VERSION "BodyCAN"

NS_ :

BS_:

BU_: CCM CEM DDM ETC ILCM PDM POT RLDM RRDM SMD SMP TRM Vector_XXX

BO_ 820 CemBodyFr93: 8 CEM
 SG_ ExtrLtgSts_UB : 4|1@0+ (1,0) [0|1] ""  TRM
 SG_ ExtrLtgStsAFS : 23|2@0+ (1,0) [0|3] ""  TRM
 SG_ ExtrLtgStsAHBC : 21|2@0+ (1,0) [0|3] ""  TRM
 SG_ ExtrLtgStsAHL : 19|2@0+ (1,0) [0|3] ""  TRM
 SG_ ExtrLtgStsAllWL : 17|2@0+ (1,0) [0|3] ""  TRM
 SG_ ExtrLtgStsApproach : 31|2@0+ (1,0) [0|3] ""  TRM
 SG_ ExtrLtgStsChks : 15|8@0+ (1,0) [0|255] "Unitless"  TRM
 SG_ ExtrLtgStsCntr : 3|4@0+ (1,0) [0|15] "Unitless"  TRM
 SG_ ExtrLtgStsCornrgLi : 29|2@0+ (1,0) [0|3] ""  TRM
 SG_ ExtrLtgStsDBL : 27|2@0+ (1,0) [0|3] ""  TRM
 SG_ ExtrLtgStsDRL : 25|2@0+ (1,0) [0|3] ""  TRM
 SG_ ExtrLtgStsFlash : 39|2@0+ (1,0) [0|3] ""  TRM
 SG_ ExtrLtgStsFrntFog : 37|2@0+ (1,0) [0|3] ""  TRM
 SG_ ExtrLtgStsGoodbye : 35|2@0+ (1,0) [0|3] ""  TRM
 SG_ ExtrLtgStsHiBeam : 33|2@0+ (1,0) [0|3] ""  TRM
 SG_ ExtrLtgStsHomeSafe : 47|2@0+ (1,0) [0|3] ""  TRM
 SG_ ExtrLtgStsHWL : 45|2@0+ (1,0) [0|3] ""  TRM
 SG_ ExtrLtgStsLoBeam : 43|2@0+ (1,0) [0|3] ""  TRM
 SG_ ExtrLtgStsLtgShow : 41|2@0+ (1,0) [0|3] ""  TRM
 SG_ ExtrLtgStsPosLiFrnt : 55|2@0+ (1,0) [0|3] ""  TRM
 SG_ ExtrLtgStsPosLiRe : 53|2@0+ (1,0) [0|3] ""  TRM
 SG_ ExtrLtgStsReFog : 51|2@0+ (1,0) [0|3] ""  TRM
 SG_ ExtrLtgStsReverseLi : 49|2@0+ (1,0) [0|3] ""  TRM
 SG_ ExtrLtgStsStopLi : 63|2@0+ (1,0) [0|3] ""  TRM
 SG_ ExtrLtgStsTurnIndrLe : 61|2@0+ (1,0) [0|3] ""  TRM
 SG_ ExtrLtgStsTurnIndrRi : 59|2@0+ (1,0) [0|3] ""  TRM
 SG_ ExtrLtgStsWelcome : 57|2@0+ (1,0) [0|3] ""  TRM

BO_ 836 CemBodyFr95: 8 CEM
 SG_ ADIntrLiCtrlReq : 50|3@0+ (1,0) [0|7] ""  ILCM
 SG_ ADIntrLiCtrlReq_UB : 51|1@0+ (1,0) [0|1] ""  ILCM
 SG_ AmbientLiEffectStatus_UB : 55|1@0+ (1,0) [0|1] ""  ILCM
 SG_ AmbientLiEffectStatusBreathingEf : 47|1@0+ (1,0) [0|1] ""  ILCM
 SG_ AmbientLiEffectStatusIdPen : 43|4@0+ (1,0) [0|15] ""  ILCM
 SG_ AmbientLiEffectStatusTransitionE : 46|1@0+ (1,0) [0|1] ""  ILCM
 SG_ AmbLiEnduranceMilgOpenReq_UB : 58|1@0+ (1,0) [0|1] ""  ILCM
 SG_ AmbLiEnduranceMilgOpenReqIdPen : 63|4@0+ (1,0) [0|15] ""  ILCM
 SG_ AmbLiEnduranceMilgOpenReqOnOff1 : 59|1@0+ (1,0) [0|1] ""  ILCM
 SG_ CallSts : 56|1@0+ (1,0) [0|1] ""  ILCM
 SG_ CallSts_UB : 57|1@0+ (1,0) [0|1] ""  ILCM
 SG_ Zone1Settings_UB : 4|1@0+ (1,0) [0|1] ""  ILCM
 SG_ Zone1SettingsBlue : 23|8@0+ (1,0) [0|255] "Unitless"  ILCM
 SG_ Zone1SettingsGreen : 31|8@0+ (1,0) [0|255] "Unitless"  ILCM
 SG_ Zone1SettingsIdPen : 3|4@0+ (1,0) [0|15] ""  ILCM
 SG_ Zone1SettingsIntensity : 12|5@0+ (1,0) [0|31] "Unitless"  ILCM
 SG_ Zone1SettingsRed : 39|8@0+ (1,0) [0|255] "Unitless"  ILCM
 SG_ Zone1SettingsZoneStatus : 13|1@0+ (1,0) [0|1] ""  ILCM

BO_ 840 CemBodyFr96: 8 CEM
 SG_ AmbLiPhoneOpenReq_UB : 50|1@0+ (1,0) [0|1] ""  ILCM
 SG_ AmbLiPhoneOpenReqIdPen : 55|4@0+ (1,0) [0|15] ""  ILCM
 SG_ AmbLiPhoneOpenReqOnOff1 : 51|1@0+ (1,0) [0|1] ""  ILCM
 SG_ FuLvlLoWarn : 40|1@0+ (1,0) [0|1] ""  ILCM
 SG_ FuLvlLoWarn_UB : 41|1@0+ (1,0) [0|1] ""  ILCM
 SG_ GoodbyeLiOpenReq_UB : 42|1@0+ (1,0) [0|1] ""  ILCM
 SG_ GoodbyeLiOpenReqIdPen : 47|4@0+ (1,0) [0|15] ""  ILCM
 SG_ GoodbyeLiOpenReqOnOff1 : 43|1@0+ (1,0) [0|1] ""  ILCM
 SG_ WelcomeLiOpenReq_UB : 58|1@0+ (1,0) [0|1] ""  ILCM
 SG_ WelcomeLiOpenReqIdPen : 63|4@0+ (1,0) [0|15] ""  ILCM
 SG_ WelcomeLiOpenReqOnOff1 : 59|1@0+ (1,0) [0|1] ""  ILCM
 SG_ Zone2Settings_UB : 4|1@0+ (1,0) [0|1] ""  ILCM
 SG_ Zone2SettingsBlue : 23|8@0+ (1,0) [0|255] "Unitless"  ILCM
 SG_ Zone2SettingsGreen : 31|8@0+ (1,0) [0|255] "Unitless"  ILCM
 SG_ Zone2SettingsIdPen : 3|4@0+ (1,0) [0|15] ""  ILCM
 SG_ Zone2SettingsIntensity : 12|5@0+ (1,0) [0|31] "Unitless"  ILCM
 SG_ Zone2SettingsRed : 39|8@0+ (1,0) [0|255] "Unitless"  ILCM
 SG_ Zone2SettingsZoneStatus : 13|1@0+ (1,0) [0|1] ""  ILCM

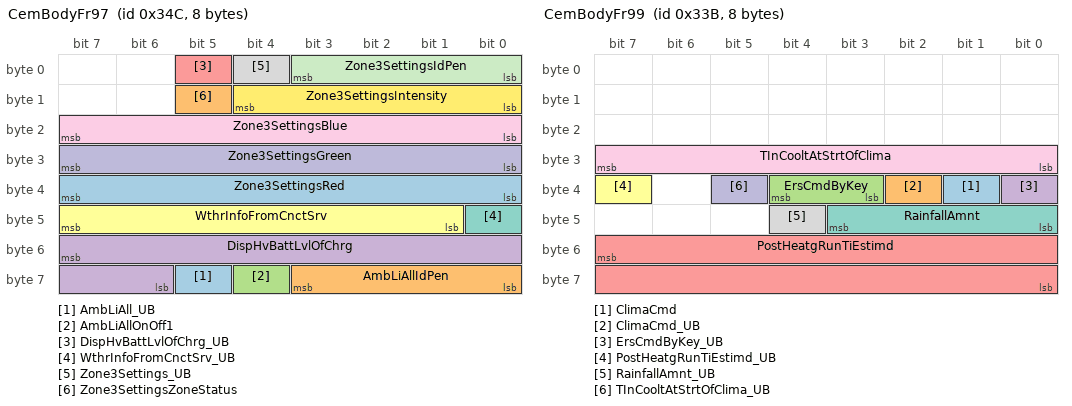
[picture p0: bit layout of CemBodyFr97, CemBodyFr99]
BO_ 844 CemBodyFr97: 8 CEM
 SG_ AmbLiAll_UB : 61|1@0+ (1,0) [0|1] ""  ILCM
 SG_ AmbLiAllIdPen : 59|4@0+ (1,0) [0|15] ""  ILCM
 SG_ AmbLiAllOnOff1 : 60|1@0+ (1,0) [0|1] ""  ILCM
 SG_ DispHvBattLvlOfChrg : 55|10@0+ (0.1,0) [0|102.3] "%"  ILCM
 SG_ DispHvBattLvlOfChrg_UB : 5|1@0+ (1,0) [0|1] ""  ILCM
 SG_ WthrInfoFromCnctSrv : 47|7@0+ (1,0) [0|127] "Unitless"  ILCM
 SG_ WthrInfoFromCnctSrv_UB : 40|1@0+ (1,0) [0|1] ""  ILCM
 SG_ Zone3Settings_UB : 4|1@0+ (1,0) [0|1] ""  ILCM
 SG_ Zone3SettingsBlue : 23|8@0+ (1,0) [0|255] "Unitless"  ILCM
 SG_ Zone3SettingsGreen : 31|8@0+ (1,0) [0|255] "Unitless"  ILCM
 SG_ Zone3SettingsIdPen : 3|4@0+ (1,0) [0|15] ""  ILCM
 SG_ Zone3SettingsIntensity : 12|5@0+ (1,0) [0|31] "Unitless"  ILCM
 SG_ Zone3SettingsRed : 39|8@0+ (1,0) [0|255] "Unitless"  ILCM
 SG_ Zone3SettingsZoneStatus : 13|1@0+ (1,0) [0|1] ""  ILCM

BO_ 34 CemBodyFr98: 8 CEM
 SG_ MusicInfoForMusicShow1_UB : 2|1@0+ (1,0) [0|1] ""  ILCM
 SG_ MusicInfoForMusicShow1DownSampli : 15|4@0+ (1,0) [0|15] "Unitless"  ILCM
 SG_ MusicInfoForMusicShow1MaxFFT100m : 11|4@0+ (1,0) [0|15] "Unitless"  ILCM
 SG_ MusicInfoForMusicShow1MaxFF_0000 : 23|8@0+ (1,0) [0|255] "Unitless"  ILCM
 SG_ MusicInfoForMusicShow1Segment1FF : 31|4@0+ (1,0) [0|15] "Unitless"  ILCM
 SG_ MusicInfoForMusicShow1Segment2FF : 27|4@0+ (1,0) [0|15] "Unitless"  ILCM
 SG_ MusicInfoForMusicShow1Segment3FF : 39|4@0+ (1,0) [0|15] "Unitless"  ILCM
 SG_ MusicInfoForMusicShow1Segment4FF : 35|4@0+ (1,0) [0|15] "Unitless"  ILCM
 SG_ MusicInfoForMusicShow1Segment5FF : 47|4@0+ (1,0) [0|15] "Unitless"  ILCM
 SG_ MusicInfoForMusicShow1Segment6FF : 43|4@0+ (1,0) [0|15] "Unitless"  ILCM
 SG_ MusicInfoForMusicShow1Segment7FF : 55|4@0+ (1,0) [0|15] "Unitless"  ILCM
 SG_ MusicInfoForMusicShow1Segment8FF : 51|4@0+ (1,0) [0|15] "Unitless"  ILCM
 SG_ MusicInfoForMusicShow1StateFlagA : 0|1@0+ (1,0) [0|1] ""  ILCM
 SG_ MusicInfoForMusicShow1StateFlagN : 1|1@0+ (1,0) [0|1] ""  ILCM
 SG_ MusicInfoForMusicShow1TimeFlagAu : 63|4@0+ (1,0) [0|15] "Unitless"  ILCM
 SG_ MusicInfoForMusicShow1TimeFlagMe : 59|4@0+ (1,0) [0|15] "Unitless"  ILCM
 SG_ SecRowRiCmftSet : 4|2@0+ (1,0) [0|3] ""  Vector_XXX
 SG_ SecRowRiCmftSet_UB : 5|1@0+ (1,0) [0|1] ""  Vector_XXX
 SG_ WinOpenLDACReq : 7|1@0+ (1,0) [0|1] ""  DDM,PDM,RLDM,RRDM
 SG_ WinOpenLDACReq_UB : 6|1@0+ (1,0) [0|1] ""  DDM,PDM,RLDM,RRDM

BO_ 827 CemBodyFr99: 8 CEM
 SG_ ClimaCmd : 33|1@0+ (1,0) [0|1] ""  CCM
 SG_ ClimaCmd_UB : 34|1@0+ (1,0) [0|1] ""  CCM
 SG_ ErsCmdByKey : 36|2@0+ (1,0) [0|3] ""  CCM
 SG_ ErsCmdByKey_UB : 32|1@0+ (1,0) [0|1] ""  CCM
 SG_ PostHeatgRunTiEstimd : 55|16@0+ (1,0) [0|65535] "Unitless"  CCM
 SG_ PostHeatgRunTiEstimd_UB : 39|1@0+ (1,0) [0|1] ""  CCM
 SG_ RainfallAmnt : 43|4@0+ (1,0) [0|15] ""  CCM
 SG_ RainfallAmnt_UB : 44|1@0+ (1,0) [0|1] ""  CCM
 SG_ TInCooltAtStrtOfClima : 31|8@0+ (1,-40) [-40|215] "degC"  CCM
 SG_ TInCooltAtStrtOfClima_UB : 37|1@0+ (1,0) [0|1] ""  CCM

BO_ 1281 CemBodyNMFr: 8 CEM
 SG_ PNC16_CEM : 16|1@0+ (1,0) [0|0] ""  CCM
 SG_ PNC17_CEM : 17|1@0+ (1,0) [0|0] ""  CCM
 SG_ PNC18_CEM : 18|1@0+ (1,0) [0|0] ""  CCM
 SG_ PNC19_CEM : 19|1@0+ (1,0) [0|0] ""  CCM
 SG_ PNC20_CEM : 20|1@0+ (1,0) [0|0] ""  CCM
 SG_ PNC21_CEM : 21|1@0+ (1,0) [0|0] ""  CCM
 SG_ PNC22_CEM : 22|1@0+ (1,0) [0|0] ""  CCM
 SG_ PNC23_CEM : 23|1@0+ (1,0) [0|0] ""  CCM
 SG_ PNC24_CEM : 24|1@0+ (1,0) [0|0] ""  CCM
 SG_ PNC25_CEM : 25|1@0+ (1,0) [0|0] ""  CCM
 SG_ PNC26_CEM : 26|1@0+ (1,0) [0|0] ""  CCM
 SG_ PNC27_CEM : 27|1@0+ (1,0) [0|0] ""  CCM
 SG_ PNC28_CEM : 28|1@0+ (1,0) [0|0] ""  CCM
 SG_ PNC29_CEM : 29|1@0+ (1,0) [0|0] ""  CCM
 SG_ PNC30_CEM : 30|1@0+ (1,0) [0|0] ""  CCM
 SG_ PNC31_CEM : 31|1@0+ (1,0) [0|0] ""  CCM
 SG_ PNC32_CEM : 32|1@0+ (1,0) [0|0] ""  CCM
 SG_ PNC33_CEM : 33|1@0+ (1,0) [0|0] ""  CCM
 SG_ PNC34_CEM : 34|1@0+ (1,0) [0|0] ""  CCM
 SG_ PNC35_CEM : 35|1@0+ (1,0) [0|0] ""  CCM
 SG_ PNC36_CEM : 36|1@0+ (1,0) [0|0] ""  CCM
 SG_ PNC37_CEM : 37|1@0+ (1,0) [0|0] ""  CCM
 SG_ PNC38_CEM : 38|1@0+ (1,0) [0|0] ""  CCM
 SG_ PNC39_CEM : 39|1@0+ (1,0) [0|0] ""  CCM
 SG_ PNC40_CEM : 40|1@0+ (1,0) [0|0] ""  CCM
 SG_ PNC41_CEM : 41|1@0+ (1,0) [0|0] ""  CCM
 SG_ PNC42_CEM : 42|1@0+ (1,0) [0|0] ""  CCM
 SG_ NM_PNI_CEM : 14|1@0+ (1,0) [0|0] ""  CCM
 SG_ NM_AW_CEM : 12|1@0+ (1,0) [0|0] ""  CCM
 SG_ NM_CS_CEM : 11|1@0+ (1,0) [0|0] ""  CCM
 SG_ NM_RMR_CEM : 8|1@0+ (1,0) [0|0] ""  CCM
 SG_ NM_NodeID_CEM : 7|8@0+ (1,0) [0|0] ""  CCM

BO_ 2047 CemToAllFuncBodyDiagReqFrame: 8 CEM
 SG_ CemToAllFuncBodyDiagReqNpdu : 7|64@0+ (1,0) [0|0] ""  CCM,DDM,ILCM,PDM,POT,RLDM,RRDM,SMD,SMP,TRM

BO_ 1809 CemToCcmBodyDiagReqFrame: 8 CEM
 SG_ CemToCcmBodyDiagReqNpdu : 7|64@0+ (1,0) [0|0] ""  CCM

BO_ 1810 CemToDdmBodyDiagReqFrame: 8 CEM
 SG_ CemToDdmBodyDiagReqNpdu : 7|64@0+ (1,0) [0|0] ""  DDM

BO_ 1413 CemtoEtcXCPFr01: 8 CEM

BO_ 1414 CemtoEtcXCPFr02: 8 CEM

BO_ 1415 CemtoEtcXCPFr03: 8 CEM

BO_ 1416 CemtoEtcXCPFr04: 8 CEM

BO_ 1840 CemToIlcmBodyDiagReqFrame1: 8 CEM
 SG_ CemToIlcmBodyDiagReqNpdu : 7|64@0+ (1,0) [0|0] ""  ILCM

BO_ 1816 CemToLdmBodyDiagReqFrame: 8 CEM
 SG_ CemToLdmBodyDiagReqNpdu : 7|64@0+ (1,0) [0|0] ""  Vector_XXX

BO_ 1811 CemToPdmBodyDiagReqFrame: 8 CEM
 SG_ CemToPdmBodyDiagReqNpdu : 7|64@0+ (1,0) [0|0] ""  PDM

BO_ 1813 CemToPotBodyDiagReqFrame: 8 CEM
 SG_ CemToPotBodyDiagReqNpdu : 7|64@0+ (1,0) [0|0] ""  POT

BO_ 1817 CemToRdmBodyDiagReqFrame: 8 CEM
 SG_ CemToRdmBodyDiagReqNpdu : 7|64@0+ (1,0) [0|0] ""  Vector_XXX

BO_ 1825 CemToRldmBodyDiagReqFrame: 8 CEM
 SG_ CemToRldmBodyDiagReqNpdu : 7|64@0+ (1,0) [0|0] ""  RLDM

BO_ 1826 CemToRrdmBodyDiagReqFrame: 8 CEM
 SG_ CemToRrdmBodyDiagReqNpdu : 7|64@0+ (1,0) [0|0] ""  RRDM

BO_ 1827 CemToSdlBodyDiagReqFrame: 8 CEM
 SG_ CemToSdlBodyDiagReqNpdu : 7|64@0+ (1,0) [0|0] ""  Vector_XXX

BO_ 1828 CemToSdrBodyDiagReqFrame: 8 CEM
 SG_ CemToSdrBodyDiagReqNpdu : 7|64@0+ (1,0) [0|0] ""  Vector_XXX

BO_ 1841 CemToSmblBodyDiagReqFrame: 8 CEM
 SG_ CemToSmblBodyDiagReqNpdu : 7|64@0+ (1,0) [0|0] ""  Vector_XXX

BO_ 1842 CemToSmbrBodyDiagReqFrame: 8 CEM
 SG_ CemToSmbrBodyDiagReqNpdu : 7|64@0+ (1,0) [0|0] ""  Vector_XXX

BO_ 1831 CemToSmdBodyDiagReqFrame: 8 CEM
 SG_ CemToSmdBodyDiagReqNpdu : 7|64@0+ (1,0) [0|0] ""  SMD

BO_ 1843 CemToSmfBodyDiagReqFram: 8 CEM
 SG_ CemToSmfBodyDiagReqNpdu : 7|64@0+ (1,0) [0|0] ""  Vector_XXX

BO_ 1832 CemToSmpBodyDiagReqFrame: 8 CEM
 SG_ CemToSmpBodyDiagReqNpdu : 7|64@0+ (1,0) [0|0] ""  SMP

BO_ 1833 CemToSmrBodyDiagReqFrame: 8 CEM
 SG_ CemToSmbBodyDiagReqNpdu : 7|64@0+ (1,0) [0|0] ""  Vector_XXX

BO_ 1815 CemToTrmBodyDiagReqFrame: 8 CEM
 SG_ CemToTrmBodyDiagReqNpdu : 7|64@0+ (1,0) [0|0] ""  TRM

BO_ 48 DdmBodyFr01: 8 DDM
 SG_ ChdLockLeftCmd : 7|2@0+ (1,0) [0|3] ""  RLDM
 SG_ ChdLockLeftCmd_UB : 3|1@0+ (1,0) [0|1] ""  RLDM
 SG_ ChdLockRightStsToHmi : 1|2@0+ (1,0) [0|3] ""  CEM
 SG_ ChdLockRightStsToHmi_UB : 2|1@0+ (1,0) [0|1] ""  CEM
 SG_ DoorDrvrHndlHMISts_UB : 15|1@0+ (1,0) [0|1] ""  CEM
 SG_ DoorDrvrHndlHMIStsDeployedOverTm : 23|1@0+ (1,0) [0|1] ""  CEM
 SG_ DoorDrvrHndlHMIStsReserved1 : 22|1@0+ (1,0) [0|1] ""  CEM
 SG_ DoorDrvrHndlHMIStsRetractOverTmd : 21|1@0+ (1,0) [0|1] ""  CEM
 SG_ DoorDrvrHndlHMIStsUnsScsHallSnsr : 20|1@0+ (1,0) [0|1] ""  CEM
 SG_ DoorDrvrRelsFail_UB : 19|1@0+ (1,0) [0|1] ""  CEM
 SG_ DoorDrvrRelsFailCinchOverTimed : 18|1@0+ (1,0) [0|1] ""  CEM
 SG_ DoorDrvrRelsFailFailure1 : 17|1@0+ (1,0) [0|1] ""  CEM
 SG_ DoorDrvrRelsFailMechRels : 16|1@0+ (1,0) [0|1] ""  CEM
 SG_ FltOfIndcrTurnOnDrvrSide : 40|1@0+ (1,0) [0|1] ""  CEM
 SG_ FltOfIndcrTurnOnDrvrSide_UB : 41|1@0+ (1,0) [0|1] ""  CEM
 SG_ MemBtnPsd_UB : 28|1@0+ (1,0) [0|1] ""  CEM
 SG_ MemBtnPsdMemBtn1 : 14|1@0+ (1,0) [0|1] ""  CEM
 SG_ MemBtnPsdMemBtn2 : 13|1@0+ (1,0) [0|1] ""  CEM
 SG_ MemBtnPsdMemBtn3 : 12|1@0+ (1,0) [0|1] ""  CEM
 SG_ MemBtnPsdMemButM : 11|1@0+ (1,0) [0|1] ""  CEM
 SG_ MirrFoldStsAtDrvr : 55|3@0+ (1,0) [0|7] ""  CEM
 SG_ MirrFoldStsAtDrvr_UB : 25|1@0+ (1,0) [0|1] ""  CEM
 SG_ ShortDropWinDrvrSts : 9|2@0+ (1,0) [0|3] ""  CEM
 SG_ ShortDropWinDrvrSts_UB : 10|1@0+ (1,0) [0|1] ""  CEM
 SG_ WinDsblRightCmd : 49|1@0+ (1,0) [0|1] ""  RRDM
 SG_ WinDsblRightCmd_UB : 48|1@0+ (1,0) [0|1] ""  RRDM
 SG_ WinFailrStsAtDrvr : 5|1@0+ (1,0) [0|1] ""  CEM
 SG_ WinFailrStsAtDrvr_UB : 4|1@0+ (1,0) [0|1] ""  CEM

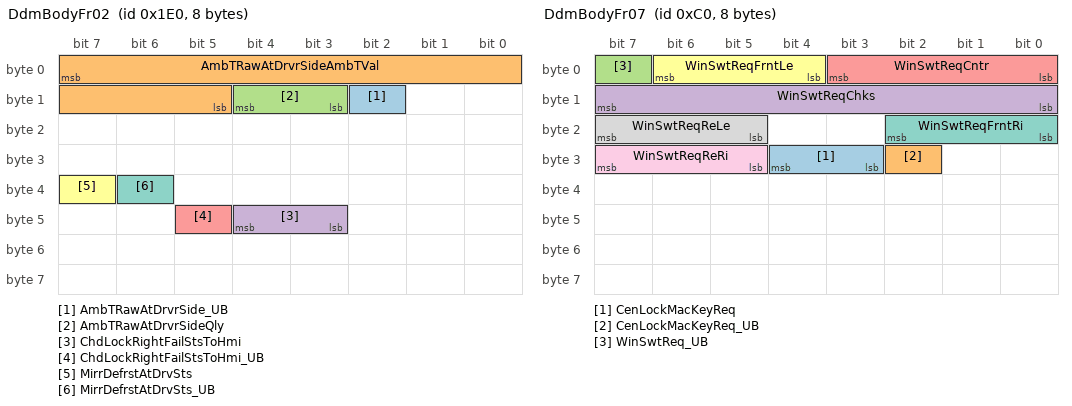
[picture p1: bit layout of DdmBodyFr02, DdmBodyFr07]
BO_ 480 DdmBodyFr02: 8 DDM
 SG_ AmbTRawAtDrvrSide_UB : 10|1@0+ (1,0) [0|1] ""  CEM
 SG_ AmbTRawAtDrvrSideAmbTVal : 7|11@0+ (0.1,-70) [-70|134.7] "degC"  CEM
 SG_ AmbTRawAtDrvrSideQly : 12|2@0+ (1,0) [0|3] ""  CEM
 SG_ ChdLockRightFailStsToHmi : 44|2@0+ (1,0) [0|3] ""  CEM
 SG_ ChdLockRightFailStsToHmi_UB : 45|1@0+ (1,0) [0|1] ""  CEM
 SG_ MirrDefrstAtDrvSts : 39|1@0+ (1,0) [0|1] ""  CEM
 SG_ MirrDefrstAtDrvSts_UB : 38|1@0+ (1,0) [0|1] ""  CEM

BO_ 291 DdmBodyFr03: 8 DDM
 SG_ AmbTURawAtDrvrSide : 55|12@0+ (0.1,-70) [-70|339.5] "degC"  CEM
 SG_ AmbTURawAtDrvrSide_UB : 42|1@0+ (1,0) [0|1] ""  CEM
 SG_ DoorDrvrCinhIntFailInf_UB : 43|1@0+ (1,0) [0|1] ""  CEM
 SG_ DoorDrvrCinhIntFailInfCinchFlt1 : 45|1@0+ (1,0) [0|1] ""  CEM
 SG_ DoorDrvrCinhIntFailInfCinchRestF : 44|1@0+ (1,0) [0|1] ""  CEM
 SG_ DoorDrvrHndlSts : 21|3@0+ (1,0) [0|7] ""  CEM
 SG_ DoorDrvrHndlSts_UB : 22|1@0+ (1,0) [0|1] ""  CEM
 SG_ DoorDrvrSwpLockBtn : 57|1@0+ (1,0) [0|1] ""  CEM
 SG_ DoorDrvrSwpLockBtn_UB : 56|1@0+ (1,0) [0|1] ""  CEM
 SG_ MirrDwnStsAtDrvr : 18|3@0+ (1,0) [0|7] ""  CEM
 SG_ MirrDwnStsAtDrvr_UB : 46|1@0+ (1,0) [0|1] ""  CEM
 SG_ MirrPosnAdjFromCldPass_UB : 23|1@0+ (1,0) [0|1] ""  PDM
 SG_ MirrPosnAdjFromCldPassMirrPosnAd : 7|8@0+ (1,0) [0|180] "Deg"  PDM
 SG_ MirrPosnAdjFromCldPassMirrP_0000 : 15|8@0+ (1,0) [0|180] "Deg"  PDM
 SG_ MirrPosnToCldAtDrvr_UB : 47|1@0+ (1,0) [0|1] ""  CEM
 SG_ MirrPosnToCldAtDrvrMirrPosnAdjCl : 31|8@0+ (1,0) [0|180] "Deg"  CEM
 SG_ MirrPosnToCldAtDrvrMirrPosn_0000 : 39|8@0+ (1,0) [0|180] "Deg"  CEM

BO_ 5 DdmBodyFr04: 8 DDM
 SG_ ChdLockRightCmd : 6|2@0+ (1,0) [0|3] ""  RRDM
 SG_ ChdLockRightCmd_UB : 4|1@0+ (1,0) [0|1] ""  RRDM
 SG_ ChdPrtnLeftFailStsToHmi : 31|2@0+ (1,0) [0|3] ""  CEM
 SG_ ChdPrtnLeftFailStsToHmi_UB : 7|1@0+ (1,0) [0|1] ""  CEM
 SG_ ChdPrtnLeftStsToHmi : 1|2@0+ (1,0) [0|3] ""  CEM
 SG_ ChdPrtnLeftStsToHmi_UB : 2|1@0+ (1,0) [0|1] ""  CEM
 SG_ DoorDrvrLatPawlSt : 33|2@0+ (1,0) [0|3] ""  CEM
 SG_ DoorDrvrLatPawlSt_UB : 34|1@0+ (1,0) [0|1] ""  CEM
 SG_ DoorDrvrLatPosn : 47|2@0+ (1,0) [0|3] ""  CEM
 SG_ DoorDrvrLatPosn_UB : 58|1@0+ (1,0) [0|1] ""  CEM
 SG_ DoorDrvrLockSts : 45|2@0+ (1,0) [0|3] ""  CEM
 SG_ DoorDrvrLockSts_UB : 59|1@0+ (1,0) [0|1] ""  CEM
 SG_ DoorDrvrOpenLowReqOutdSwt1 : 23|2@0+ (1,0) [0|3] ""  CEM
 SG_ DoorDrvrOpenLowReqOutdSwt1_UB : 63|1@0+ (1,0) [0|1] ""  CEM
 SG_ DoorDrvrOpenReqInsdSwt1 : 25|2@0+ (1,0) [0|3] ""  CEM
 SG_ DoorDrvrOpenReqInsdSwt1_UB : 57|1@0+ (1,0) [0|1] ""  CEM
 SG_ DoorDrvrSwtIntrLockgReq : 43|2@0+ (1,0) [0|3] ""  CEM
 SG_ DoorDrvrSwtIntrLockgReq_UB : 60|1@0+ (1,0) [0|1] ""  CEM
 SG_ LcmaLedStsDrvrSide : 29|1@0+ (1,0) [0|1] ""  CEM
 SG_ LcmaLedStsDrvrSide_UB : 28|1@0+ (1,0) [0|1] ""  CEM
 SG_ MirrAtDrvrInMovmt : 41|1@0+ (1,0) [0|1] ""  CEM
 SG_ MirrAtDrvrInMovmt_UB : 61|1@0+ (1,0) [0|1] ""  CEM
 SG_ MirrBtnPsdAtDrvr : 40|1@0+ (1,0) [0|1] ""  CEM
 SG_ MirrBtnPsdAtDrvr_UB : 62|1@0+ (1,0) [0|1] ""  CEM
 SG_ MirrCmdAtPass_UB : 48|1@0+ (1,0) [0|1] ""  PDM
 SG_ MirrCmdAtPassMirrDwnCmd : 55|2@0+ (1,0) [0|3] ""  PDM
 SG_ MirrCmdAtPassMirrFoldCmd : 53|2@0+ (1,0) [0|3] ""  PDM
 SG_ MirrCmdAtPassMirrPosAdjCmd : 51|3@0+ (1,0) [0|7] ""  PDM
 SG_ MirrPosnDownLdSts : 9|2@0+ (1,0) [0|3] ""  CEM
 SG_ MirrPosnDownLdSts_UB : 18|1@0+ (1,0) [0|1] ""  CEM
 SG_ MirrPosnFromCldAtDrvrFb : 11|2@0+ (1,0) [0|3] ""  CEM
 SG_ MirrPosnFromCldAtDrvrFb_UB : 19|1@0+ (1,0) [0|1] ""  CEM
 SG_ MirrPosnFromCldAtPassFb : 13|2@0+ (1,0) [0|3] ""  CEM
 SG_ MirrPosnFromCldAtPassFb_UB : 20|1@0+ (1,0) [0|1] ""  CEM
 SG_ MirrPosnMemSts : 15|2@0+ (1,0) [0|3] ""  CEM
 SG_ MirrPosnMemSts_UB : 21|1@0+ (1,0) [0|1] ""  CEM
 SG_ WinDsblLeftCmd : 26|1@0+ (1,0) [0|1] ""  RLDM
 SG_ WinDsblLeftCmd_UB : 27|1@0+ (1,0) [0|1] ""  RLDM
 SG_ WinPosnStsAtDrvr : 39|5@0+ (1,0) [0|31] ""  CCM,CEM
 SG_ WinPosnStsAtDrvr_UB : 56|1@0+ (1,0) [0|1] ""  CCM,CEM

BO_ 192 DdmBodyFr07: 8 DDM
 SG_ CenLockMacKeyReq : 28|2@0+ (1,0) [0|3] ""  CEM
 SG_ CenLockMacKeyReq_UB : 26|1@0+ (1,0) [0|1] ""  CEM
 SG_ WinSwtReq_UB : 7|1@0+ (1,0) [0|1] ""  PDM,RLDM,RRDM
 SG_ WinSwtReqChks : 15|8@0+ (1,0) [0|255] "Unitless"  PDM,RLDM,RRDM
 SG_ WinSwtReqCntr : 3|4@0+ (1,0) [0|15] "Unitless"  PDM,RLDM,RRDM
 SG_ WinSwtReqFrntLe : 6|3@0+ (1,0) [0|7] ""  PDM,RLDM,RRDM
 SG_ WinSwtReqFrntRi : 18|3@0+ (1,0) [0|7] ""  PDM,RLDM,RRDM
 SG_ WinSwtReqReLe : 23|3@0+ (1,0) [0|7] ""  PDM,RLDM,RRDM
 SG_ WinSwtReqReRi : 31|3@0+ (1,0) [0|7] ""  PDM,RLDM,RRDM

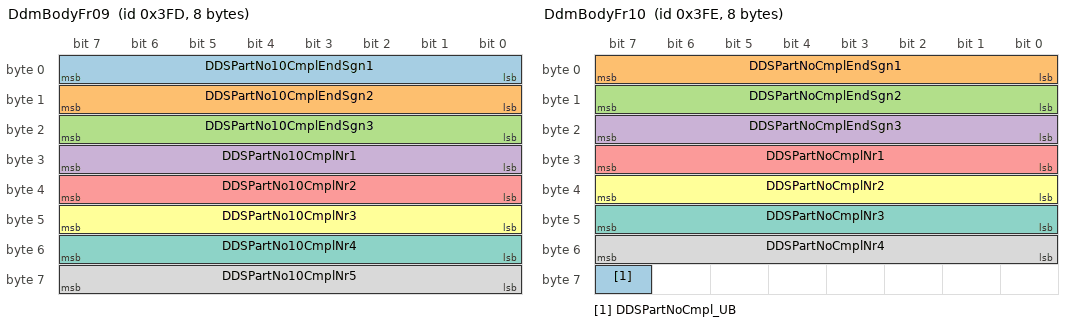
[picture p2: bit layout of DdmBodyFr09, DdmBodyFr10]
BO_ 1021 DdmBodyFr09: 8 DDM
 SG_ DDSPartNo10CmplEndSgn1 : 7|8@0+ (1,0) [0|255] "Unitless"  Vector_XXX
 SG_ DDSPartNo10CmplEndSgn2 : 15|8@0+ (1,0) [0|255] "Unitless"  Vector_XXX
 SG_ DDSPartNo10CmplEndSgn3 : 23|8@0+ (1,0) [0|255] "Unitless"  Vector_XXX
 SG_ DDSPartNo10CmplNr1 : 31|8@0+ (1,0) [0|255] "Unitless"  Vector_XXX
 SG_ DDSPartNo10CmplNr2 : 39|8@0+ (1,0) [0|255] "Unitless"  Vector_XXX
 SG_ DDSPartNo10CmplNr3 : 47|8@0+ (1,0) [0|255] "Unitless"  Vector_XXX
 SG_ DDSPartNo10CmplNr4 : 55|8@0+ (1,0) [0|255] "Unitless"  Vector_XXX
 SG_ DDSPartNo10CmplNr5 : 63|8@0+ (1,0) [0|255] "Unitless"  Vector_XXX

BO_ 1022 DdmBodyFr10: 8 DDM
 SG_ DDSPartNoCmpl_UB : 63|1@0+ (1,0) [0|1] ""  Vector_XXX
 SG_ DDSPartNoCmplEndSgn1 : 7|8@0+ (1,0) [0|255] "Unitless"  Vector_XXX
 SG_ DDSPartNoCmplEndSgn2 : 15|8@0+ (1,0) [0|255] "Unitless"  Vector_XXX
 SG_ DDSPartNoCmplEndSgn3 : 23|8@0+ (1,0) [0|255] "Unitless"  Vector_XXX
 SG_ DDSPartNoCmplNr1 : 31|8@0+ (1,0) [0|255] "Unitless"  Vector_XXX
 SG_ DDSPartNoCmplNr2 : 39|8@0+ (1,0) [0|255] "Unitless"  Vector_XXX
 SG_ DDSPartNoCmplNr3 : 47|8@0+ (1,0) [0|255] "Unitless"  Vector_XXX
 SG_ DDSPartNoCmplNr4 : 55|8@0+ (1,0) [0|255] "Unitless"  Vector_XXX

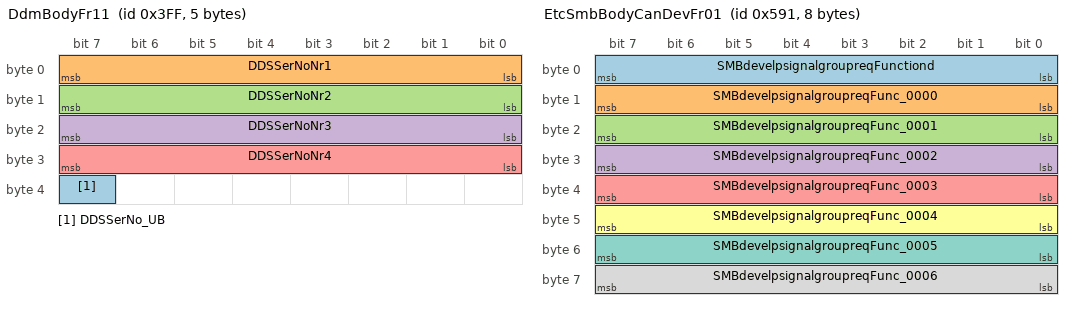
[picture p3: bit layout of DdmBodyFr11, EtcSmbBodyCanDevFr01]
BO_ 1023 DdmBodyFr11: 5 DDM
 SG_ DDSSerNo_UB : 39|1@0+ (1,0) [0|1] ""  Vector_XXX
 SG_ DDSSerNoNr1 : 7|8@0+ (1,0) [0|255] "Unitless"  Vector_XXX
 SG_ DDSSerNoNr2 : 15|8@0+ (1,0) [0|255] "Unitless"  Vector_XXX
 SG_ DDSSerNoNr3 : 23|8@0+ (1,0) [0|255] "Unitless"  Vector_XXX
 SG_ DDSSerNoNr4 : 31|8@0+ (1,0) [0|255] "Unitless"  Vector_XXX

BO_ 1283 DdmBodyNMFr: 8 DDM
 SG_ PNC16_DDM : 16|1@0+ (1,0) [0|0] ""  CEM
 SG_ PNC17_DDM : 17|1@0+ (1,0) [0|0] ""  CEM
 SG_ PNC18_DDM : 18|1@0+ (1,0) [0|0] ""  CEM
 SG_ PNC19_DDM : 19|1@0+ (1,0) [0|0] ""  CEM
 SG_ PNC20_DDM : 20|1@0+ (1,0) [0|0] ""  CEM
 SG_ PNC21_DDM : 21|1@0+ (1,0) [0|0] ""  CEM
 SG_ PNC22_DDM : 22|1@0+ (1,0) [0|0] ""  CEM
 SG_ PNC23_DDM : 23|1@0+ (1,0) [0|0] ""  CEM
 SG_ PNC24_DDM : 24|1@0+ (1,0) [0|0] ""  CEM
 SG_ PNC25_DDM : 25|1@0+ (1,0) [0|0] ""  CEM
 SG_ PNC26_DDM : 26|1@0+ (1,0) [0|0] ""  CEM
 SG_ PNC27_DDM : 27|1@0+ (1,0) [0|0] ""  CEM
 SG_ PNC28_DDM : 28|1@0+ (1,0) [0|0] ""  CEM
 SG_ PNC29_DDM : 29|1@0+ (1,0) [0|0] ""  CEM
 SG_ PNC30_DDM : 30|1@0+ (1,0) [0|0] ""  CEM
 SG_ PNC31_DDM : 31|1@0+ (1,0) [0|0] ""  CEM
 SG_ PNC32_DDM : 32|1@0+ (1,0) [0|0] ""  CEM
 SG_ PNC33_DDM : 33|1@0+ (1,0) [0|0] ""  CEM
 SG_ PNC34_DDM : 34|1@0+ (1,0) [0|0] ""  CEM
 SG_ PNC35_DDM : 35|1@0+ (1,0) [0|0] ""  CEM
 SG_ PNC36_DDM : 36|1@0+ (1,0) [0|0] ""  CEM
 SG_ PNC37_DDM : 37|1@0+ (1,0) [0|0] ""  CEM
 SG_ PNC38_DDM : 38|1@0+ (1,0) [0|0] ""  CEM
 SG_ PNC39_DDM : 39|1@0+ (1,0) [0|0] ""  CEM
 SG_ PNC40_DDM : 40|1@0+ (1,0) [0|0] ""  CEM
 SG_ PNC41_DDM : 41|1@0+ (1,0) [0|0] ""  CEM
 SG_ PNC42_DDM : 42|1@0+ (1,0) [0|0] ""  CEM
 SG_ NM_PNI_DDM : 14|1@0+ (1,0) [0|0] ""  CEM
 SG_ NM_AW_DDM : 12|1@0+ (1,0) [0|0] ""  CEM
 SG_ NM_CS_DDM : 11|1@0+ (1,0) [0|0] ""  CEM
 SG_ NM_RMR_DDM : 8|1@0+ (1,0) [0|0] ""  CEM
 SG_ NM_NodeID_DDM : 7|8@0+ (1,0) [0|0] ""  CEM

BO_ 1347 DdmBodyVFCVectorFr: 8 DDM
 SG_ VFCVectorDDMBlockID : 1|2@0+ (1,0) [0|3] "Unitless"  ETC
 SG_ VFCVectorDDMVFCid0 : 2|1@0+ (1,0) [0|1] ""  ETC
 SG_ VFCVectorDDMVFCid1 : 3|1@0+ (1,0) [0|1] ""  ETC
 SG_ VFCVectorDDMVFCid10 : 12|1@0+ (1,0) [0|1] ""  ETC
 SG_ VFCVectorDDMVFCid11 : 13|1@0+ (1,0) [0|1] ""  ETC
 SG_ VFCVectorDDMVFCid12 : 14|1@0+ (1,0) [0|1] ""  ETC
 SG_ VFCVectorDDMVFCid13 : 15|1@0+ (1,0) [0|1] ""  ETC
 SG_ VFCVectorDDMVFCid14 : 16|1@0+ (1,0) [0|1] ""  ETC
 SG_ VFCVectorDDMVFCid15 : 17|1@0+ (1,0) [0|1] ""  ETC
 SG_ VFCVectorDDMVFCid16 : 18|1@0+ (1,0) [0|1] ""  ETC
 SG_ VFCVectorDDMVFCid17 : 19|1@0+ (1,0) [0|1] ""  ETC
 SG_ VFCVectorDDMVFCid18 : 20|1@0+ (1,0) [0|1] ""  ETC
 SG_ VFCVectorDDMVFCid19 : 21|1@0+ (1,0) [0|1] ""  ETC
 SG_ VFCVectorDDMVFCid2 : 4|1@0+ (1,0) [0|1] ""  ETC
 SG_ VFCVectorDDMVFCid20 : 22|1@0+ (1,0) [0|1] ""  ETC
 SG_ VFCVectorDDMVFCid21 : 23|1@0+ (1,0) [0|1] ""  ETC
 SG_ VFCVectorDDMVFCid22 : 24|1@0+ (1,0) [0|1] ""  ETC
 SG_ VFCVectorDDMVFCid23 : 25|1@0+ (1,0) [0|1] ""  ETC
 SG_ VFCVectorDDMVFCid24 : 26|1@0+ (1,0) [0|1] ""  ETC
 SG_ VFCVectorDDMVFCid25 : 27|1@0+ (1,0) [0|1] ""  ETC
 SG_ VFCVectorDDMVFCid26 : 28|1@0+ (1,0) [0|1] ""  ETC
 SG_ VFCVectorDDMVFCid27 : 29|1@0+ (1,0) [0|1] ""  ETC
 SG_ VFCVectorDDMVFCid28 : 30|1@0+ (1,0) [0|1] ""  ETC
 SG_ VFCVectorDDMVFCid29 : 31|1@0+ (1,0) [0|1] ""  ETC
 SG_ VFCVectorDDMVFCid3 : 5|1@0+ (1,0) [0|1] ""  ETC
 SG_ VFCVectorDDMVFCid30 : 32|1@0+ (1,0) [0|1] ""  ETC
 SG_ VFCVectorDDMVFCid31 : 33|1@0+ (1,0) [0|1] ""  ETC
 SG_ VFCVectorDDMVFCid32 : 34|1@0+ (1,0) [0|1] ""  ETC
 SG_ VFCVectorDDMVFCid33 : 35|1@0+ (1,0) [0|1] ""  ETC
 SG_ VFCVectorDDMVFCid34 : 36|1@0+ (1,0) [0|1] ""  ETC
 SG_ VFCVectorDDMVFCid35 : 37|1@0+ (1,0) [0|1] ""  ETC
 SG_ VFCVectorDDMVFCid36 : 38|1@0+ (1,0) [0|1] ""  ETC
 SG_ VFCVectorDDMVFCid37 : 39|1@0+ (1,0) [0|1] ""  ETC
 SG_ VFCVectorDDMVFCid38 : 40|1@0+ (1,0) [0|1] ""  ETC
 SG_ VFCVectorDDMVFCid39 : 41|1@0+ (1,0) [0|1] ""  ETC
 SG_ VFCVectorDDMVFCid4 : 6|1@0+ (1,0) [0|1] ""  ETC
 SG_ VFCVectorDDMVFCid40 : 42|1@0+ (1,0) [0|1] ""  ETC
 SG_ VFCVectorDDMVFCid41 : 43|1@0+ (1,0) [0|1] ""  ETC
 SG_ VFCVectorDDMVFCid42 : 44|1@0+ (1,0) [0|1] ""  ETC
 SG_ VFCVectorDDMVFCid43 : 45|1@0+ (1,0) [0|1] ""  ETC
 SG_ VFCVectorDDMVFCid44 : 46|1@0+ (1,0) [0|1] ""  ETC
 SG_ VFCVectorDDMVFCid45 : 47|1@0+ (1,0) [0|1] ""  ETC
 SG_ VFCVectorDDMVFCid46 : 48|1@0+ (1,0) [0|1] ""  ETC
 SG_ VFCVectorDDMVFCid47 : 49|1@0+ (1,0) [0|1] ""  ETC
 SG_ VFCVectorDDMVFCid48 : 50|1@0+ (1,0) [0|1] ""  ETC
 SG_ VFCVectorDDMVFCid49 : 51|1@0+ (1,0) [0|1] ""  ETC
 SG_ VFCVectorDDMVFCid5 : 7|1@0+ (1,0) [0|1] ""  ETC
 SG_ VFCVectorDDMVFCid50 : 52|1@0+ (1,0) [0|1] ""  ETC
 SG_ VFCVectorDDMVFCid51 : 53|1@0+ (1,0) [0|1] ""  ETC
 SG_ VFCVectorDDMVFCid52 : 54|1@0+ (1,0) [0|1] ""  ETC
 SG_ VFCVectorDDMVFCid53 : 55|1@0+ (1,0) [0|1] ""  ETC
 SG_ VFCVectorDDMVFCid54 : 56|1@0+ (1,0) [0|1] ""  ETC
 SG_ VFCVectorDDMVFCid55 : 57|1@0+ (1,0) [0|1] ""  ETC
 SG_ VFCVectorDDMVFCid56 : 58|1@0+ (1,0) [0|1] ""  ETC
 SG_ VFCVectorDDMVFCid57 : 59|1@0+ (1,0) [0|1] ""  ETC
 SG_ VFCVectorDDMVFCid58 : 60|1@0+ (1,0) [0|1] ""  ETC
 SG_ VFCVectorDDMVFCid59 : 61|1@0+ (1,0) [0|1] ""  ETC
 SG_ VFCVectorDDMVFCid6 : 8|1@0+ (1,0) [0|1] ""  ETC
 SG_ VFCVectorDDMVFCid60 : 62|1@0+ (1,0) [0|1] ""  ETC
 SG_ VFCVectorDDMVFCid61 : 63|1@0+ (1,0) [0|1] ""  ETC
 SG_ VFCVectorDDMVFCid7 : 9|1@0+ (1,0) [0|1] ""  ETC
 SG_ VFCVectorDDMVFCid8 : 10|1@0+ (1,0) [0|1] ""  ETC
 SG_ VFCVectorDDMVFCid9 : 11|1@0+ (1,0) [0|1] ""  ETC

BO_ 1554 DdmToCemBodyDiagResFrame: 8 DDM
 SG_ DdmToCemBodyDiagResNpdu : 7|64@0+ (1,0) [0|0] ""  CEM

BO_ 1417 DdmtoEtcXCPFr01: 8 DDM

BO_ 1425 EtcSmbBodyCanDevFr01: 8 ETC
 SG_ SMBdevelpsignalgroupreqFunctiond : 7|8@0+ (1,0) [0|255] "Unitless"  Vector_XXX
 SG_ SMBdevelpsignalgroupreqFunc_0000 : 15|8@0+ (1,0) [0|255] "Unitless"  Vector_XXX
 SG_ SMBdevelpsignalgroupreqFunc_0001 : 23|8@0+ (1,0) [0|255] "Unitless"  Vector_XXX
 SG_ SMBdevelpsignalgroupreqFunc_0002 : 31|8@0+ (1,0) [0|255] "Unitless"  Vector_XXX
 SG_ SMBdevelpsignalgroupreqFunc_0003 : 39|8@0+ (1,0) [0|255] "Unitless"  Vector_XXX
 SG_ SMBdevelpsignalgroupreqFunc_0004 : 47|8@0+ (1,0) [0|255] "Unitless"  Vector_XXX
 SG_ SMBdevelpsignalgroupreqFunc_0005 : 55|8@0+ (1,0) [0|255] "Unitless"  Vector_XXX
 SG_ SMBdevelpsignalgroupreqFunc_0006 : 63|8@0+ (1,0) [0|255] "Unitless"  Vector_XXX

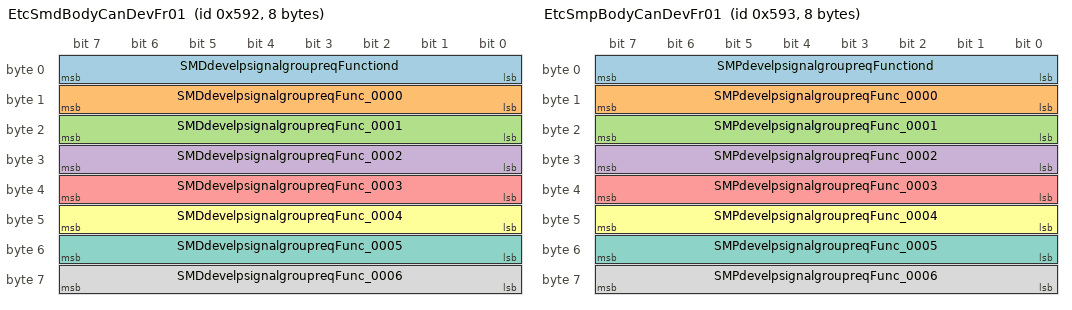
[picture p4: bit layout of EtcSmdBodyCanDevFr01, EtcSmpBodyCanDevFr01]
BO_ 1426 EtcSmdBodyCanDevFr01: 8 ETC
 SG_ SMDdevelpsignalgroupreqFunctiond : 7|8@0+ (1,0) [0|255] "Unitless"  SMD
 SG_ SMDdevelpsignalgroupreqFunc_0000 : 15|8@0+ (1,0) [0|255] "Unitless"  SMD
 SG_ SMDdevelpsignalgroupreqFunc_0001 : 23|8@0+ (1,0) [0|255] "Unitless"  SMD
 SG_ SMDdevelpsignalgroupreqFunc_0002 : 31|8@0+ (1,0) [0|255] "Unitless"  SMD
 SG_ SMDdevelpsignalgroupreqFunc_0003 : 39|8@0+ (1,0) [0|255] "Unitless"  SMD
 SG_ SMDdevelpsignalgroupreqFunc_0004 : 47|8@0+ (1,0) [0|255] "Unitless"  SMD
 SG_ SMDdevelpsignalgroupreqFunc_0005 : 55|8@0+ (1,0) [0|255] "Unitless"  SMD
 SG_ SMDdevelpsignalgroupreqFunc_0006 : 63|8@0+ (1,0) [0|255] "Unitless"  SMD

BO_ 1427 EtcSmpBodyCanDevFr01: 8 ETC
 SG_ SMPdevelpsignalgroupreqFunctiond : 7|8@0+ (1,0) [0|255] "Unitless"  SMP
 SG_ SMPdevelpsignalgroupreqFunc_0000 : 15|8@0+ (1,0) [0|255] "Unitless"  SMP
 SG_ SMPdevelpsignalgroupreqFunc_0001 : 23|8@0+ (1,0) [0|255] "Unitless"  SMP
 SG_ SMPdevelpsignalgroupreqFunc_0002 : 31|8@0+ (1,0) [0|255] "Unitless"  SMP
 SG_ SMPdevelpsignalgroupreqFunc_0003 : 39|8@0+ (1,0) [0|255] "Unitless"  SMP
 SG_ SMPdevelpsignalgroupreqFunc_0004 : 47|8@0+ (1,0) [0|255] "Unitless"  SMP
 SG_ SMPdevelpsignalgroupreqFunc_0005 : 55|8@0+ (1,0) [0|255] "Unitless"  SMP
 SG_ SMPdevelpsignalgroupreqFunc_0006 : 63|8@0+ (1,0) [0|255] "Unitless"  SMP

BO_ 1526 EtcToCcmXCPFr01: 8 ETC

BO_ 1527 EtcToCcmXCPFr02: 8 ETC

BO_ 1528 EtcToCcmXCPFr03: 8 ETC

BO_ 1529 EtcToCcmXCPFr04: 8 ETC

BO_ 1521 EtcToCemXCPFr01: 8 ETC

BO_ 1522 EtcToDdmXCPFr01: 8 ETC

BO_ 1530 EtcToIlcmXcpFr01: 8 ETC

BO_ 1523 EtcToPdmXCPFr01: 8 ETC

BO_ 1467 EtcToPotXCPFr01: 8 ETC

BO_ 1524 EtcToRldmXCPFr01: 8 ETC

BO_ 1525 EtcToRrdmXCPFr01: 8 ETC

BO_ 1465 EtcToTrmXcpFr01: 8 ETC

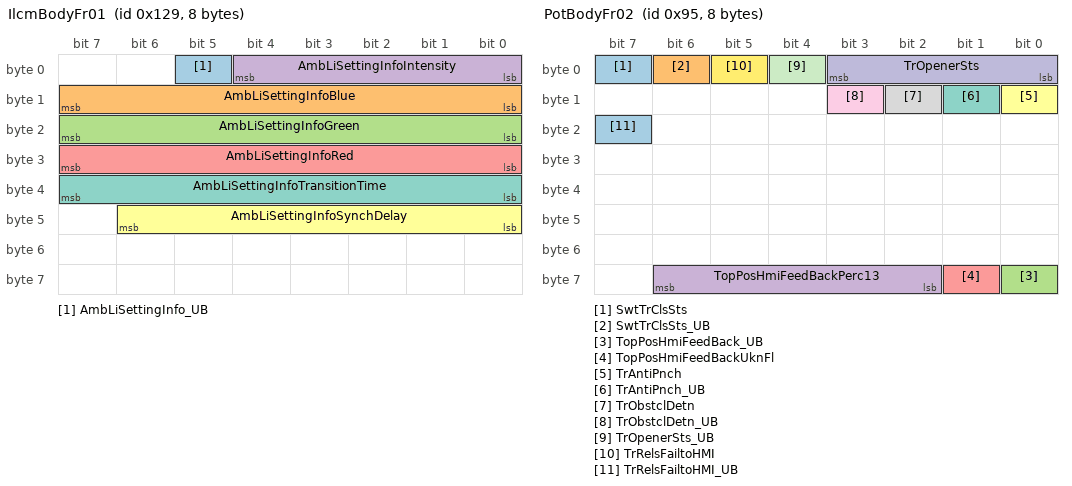
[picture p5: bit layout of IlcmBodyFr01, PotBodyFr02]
BO_ 297 IlcmBodyFr01: 8 ILCM
 SG_ AmbLiSettingInfo_UB : 5|1@0+ (1,0) [0|1] ""  CEM
 SG_ AmbLiSettingInfoBlue : 15|8@0+ (1,0) [0|255] "Unitless"  CEM
 SG_ AmbLiSettingInfoGreen : 23|8@0+ (1,0) [0|255] "Unitless"  CEM
 SG_ AmbLiSettingInfoIntensity : 4|5@0+ (1,0) [0|31] "Unitless"  CEM
 SG_ AmbLiSettingInfoRed : 31|8@0+ (1,0) [0|255] "Unitless"  CEM
 SG_ AmbLiSettingInfoSynchDelay : 46|7@0+ (1,0) [0|127] "Unitless"  CEM
 SG_ AmbLiSettingInfoTransitionTime : 39|8@0+ (1,0) [0|255] "Unitless"  CEM

BO_ 1301 IlcmBodyNMFr: 8 ILCM
 SG_ PNC16_ILCM : 16|1@0+ (1,0) [0|0] ""  DDM
 SG_ PNC17_ILCM : 17|1@0+ (1,0) [0|0] ""  DDM
 SG_ PNC18_ILCM : 18|1@0+ (1,0) [0|0] ""  DDM
 SG_ PNC19_ILCM : 19|1@0+ (1,0) [0|0] ""  DDM
 SG_ PNC20_ILCM : 20|1@0+ (1,0) [0|0] ""  DDM
 SG_ PNC21_ILCM : 21|1@0+ (1,0) [0|0] ""  DDM
 SG_ PNC22_ILCM : 22|1@0+ (1,0) [0|0] ""  DDM
 SG_ PNC23_ILCM : 23|1@0+ (1,0) [0|0] ""  DDM
 SG_ PNC24_ILCM : 24|1@0+ (1,0) [0|0] ""  DDM
 SG_ PNC25_ILCM : 25|1@0+ (1,0) [0|0] ""  DDM
 SG_ PNC26_ILCM : 26|1@0+ (1,0) [0|0] ""  DDM
 SG_ PNC27_ILCM : 27|1@0+ (1,0) [0|0] ""  DDM
 SG_ PNC28_ILCM : 28|1@0+ (1,0) [0|0] ""  DDM
 SG_ PNC29_ILCM : 29|1@0+ (1,0) [0|0] ""  DDM
 SG_ PNC30_ILCM : 30|1@0+ (1,0) [0|0] ""  DDM
 SG_ PNC31_ILCM : 31|1@0+ (1,0) [0|0] ""  DDM
 SG_ PNC32_ILCM : 32|1@0+ (1,0) [0|0] ""  DDM
 SG_ PNC33_ILCM : 33|1@0+ (1,0) [0|0] ""  DDM
 SG_ PNC34_ILCM : 34|1@0+ (1,0) [0|0] ""  DDM
 SG_ PNC35_ILCM : 35|1@0+ (1,0) [0|0] ""  DDM
 SG_ PNC36_ILCM : 36|1@0+ (1,0) [0|0] ""  DDM
 SG_ PNC37_ILCM : 37|1@0+ (1,0) [0|0] ""  DDM
 SG_ PNC38_ILCM : 38|1@0+ (1,0) [0|0] ""  DDM
 SG_ PNC39_ILCM : 39|1@0+ (1,0) [0|0] ""  DDM
 SG_ PNC40_ILCM : 40|1@0+ (1,0) [0|0] ""  DDM
 SG_ PNC41_ILCM : 41|1@0+ (1,0) [0|0] ""  DDM
 SG_ PNC42_ILCM : 42|1@0+ (1,0) [0|0] ""  DDM
 SG_ NM_PNI_ILCM : 14|1@0+ (1,0) [0|0] ""  DDM
 SG_ NM_AW_ILCM : 12|1@0+ (1,0) [0|0] ""  DDM
 SG_ NM_CS_ILCM : 11|1@0+ (1,0) [0|0] ""  DDM
 SG_ NM_RMR_ILCM : 8|1@0+ (1,0) [0|0] ""  DDM
 SG_ NM_NodeID_ILCM : 7|8@0+ (1,0) [0|0] ""  DDM

BO_ 1584 IlcmToCemBodyDiagResFrame1: 8 ILCM
 SG_ IlcmToCemBodyDiagResNpdu : 7|64@0+ (1,0) [0|0] ""  CEM

BO_ 1531 IlcmToEtcXcpFr01: 8 ILCM

BO_ 16 PdmBodyFr01: 8 PDM
 SG_ DoorPassLatPawlSt : 44|2@0+ (1,0) [0|3] ""  CEM
 SG_ DoorPassLatPawlSt_UB : 42|1@0+ (1,0) [0|1] ""  CEM
 SG_ DoorPassLatPosn : 31|2@0+ (1,0) [0|3] ""  CEM
 SG_ DoorPassLatPosn_UB : 32|1@0+ (1,0) [0|1] ""  CEM
 SG_ DoorPassLockSts : 27|2@0+ (1,0) [0|3] ""  CEM
 SG_ DoorPassLockSts_UB : 35|1@0+ (1,0) [0|1] ""  CEM
 SG_ DoorPassOpenLowReqOutdSwt1 : 47|2@0+ (1,0) [0|3] ""  CEM
 SG_ DoorPassOpenLowReqOutdSwt1_UB : 34|1@0+ (1,0) [0|1] ""  CEM
 SG_ DoorPassOpenReqInsdSwt1 : 25|2@0+ (1,0) [0|3] ""  CEM
 SG_ DoorPassOpenReqInsdSwt1_UB : 45|1@0+ (1,0) [0|1] ""  CEM
 SG_ DoorPassRelsFail_UB : 41|1@0+ (1,0) [0|1] ""  CEM
 SG_ DoorPassRelsFailCinchOverTimed : 55|1@0+ (1,0) [0|1] ""  CEM
 SG_ DoorPassRelsFailFailure1 : 54|1@0+ (1,0) [0|1] ""  CEM
 SG_ DoorPassRelsFailMechRels : 53|1@0+ (1,0) [0|1] ""  CEM
 SG_ DoorPassSwtIntrLockgReq : 18|2@0+ (1,0) [0|3] ""  CEM
 SG_ DoorPassSwtIntrLockgReq_UB : 16|1@0+ (1,0) [0|1] ""  CEM
 SG_ FltOfIndcrTurnOnPassSide : 29|1@0+ (1,0) [0|1] ""  CEM
 SG_ FltOfIndcrTurnOnPassSide_UB : 28|1@0+ (1,0) [0|1] ""  CEM
 SG_ LcmaLedStsPassSide : 39|1@0+ (1,0) [0|1] ""  CEM
 SG_ LcmaLedStsPassSide_UB : 33|1@0+ (1,0) [0|1] ""  CEM
 SG_ MirrAtPassInMovmt : 1|1@0+ (1,0) [0|1] ""  CEM
 SG_ MirrAtPassInMovmt_UB : 0|1@0+ (1,0) [0|1] ""  CEM
 SG_ MirrDwnStsAtPass : 15|3@0+ (1,0) [0|7] ""  CEM,DDM
 SG_ MirrDwnStsAtPass_UB : 12|1@0+ (1,0) [0|1] ""  CEM,DDM
 SG_ MirrFoldStsAtPass : 11|3@0+ (1,0) [0|7] ""  CEM,DDM
 SG_ MirrFoldStsAtPass_UB : 8|1@0+ (1,0) [0|1] ""  CEM,DDM
 SG_ PassMemBtnPsd_UB : 19|1@0+ (1,0) [0|1] ""  CEM
 SG_ PassMemBtnPsdMemBtn1 : 23|1@0+ (1,0) [0|1] ""  CEM
 SG_ PassMemBtnPsdMemBtn2 : 22|1@0+ (1,0) [0|1] ""  CEM
 SG_ PassMemBtnPsdMemBtn3 : 21|1@0+ (1,0) [0|1] ""  CEM
 SG_ PassMemBtnPsdMemButM : 20|1@0+ (1,0) [0|1] ""  CEM
 SG_ ShortDropWinPassSts : 38|2@0+ (1,0) [0|3] ""  CEM
 SG_ ShortDropWinPassSts_UB : 36|1@0+ (1,0) [0|1] ""  CEM
 SG_ WinPosnStsAtPass : 7|5@0+ (1,0) [0|31] ""  CCM,CEM
 SG_ WinPosnStsAtPass_UB : 2|1@0+ (1,0) [0|1] ""  CCM,CEM

BO_ 293 PdmBodyFr03: 8 PDM
 SG_ AmbTRawAtPassSide_UB : 29|1@0+ (1,0) [0|1] ""  CEM
 SG_ AmbTRawAtPassSideAmbTVal : 26|11@0+ (0.1,-70) [-70|134.7] "degC"  CEM
 SG_ AmbTRawAtPassSideQly : 28|2@0+ (1,0) [0|3] ""  CEM
 SG_ AmbTURawAtPassSide : 55|12@0+ (0.1,-70) [-70|339.5] "degC"  CEM
 SG_ AmbTURawAtPassSide_UB : 16|1@0+ (1,0) [0|1] ""  CEM
 SG_ DoorPassCinhIntFailInf_UB : 40|1@0+ (1,0) [0|1] ""  CEM
 SG_ DoorPassCinhIntFailInfCinchFlt1 : 42|1@0+ (1,0) [0|1] ""  CEM
 SG_ DoorPassCinhIntFailInfCinchRestF : 41|1@0+ (1,0) [0|1] ""  CEM
 SG_ DoorPassHndlHMISts_UB : 21|1@0+ (1,0) [0|1] ""  CEM
 SG_ DoorPassHndlHMIStsDeployedOverTm : 59|1@0+ (1,0) [0|1] ""  CEM
 SG_ DoorPassHndlHMIStsReserved1 : 58|1@0+ (1,0) [0|1] ""  CEM
 SG_ DoorPassHndlHMIStsRetractOverTmd : 57|1@0+ (1,0) [0|1] ""  CEM
 SG_ DoorPassHndlHMIStsUnsScsHallSnsr : 56|1@0+ (1,0) [0|1] ""  CEM
 SG_ DoorPassHndlSts : 19|3@0+ (1,0) [0|7] ""  CEM
 SG_ DoorPassHndlSts_UB : 20|1@0+ (1,0) [0|1] ""  CEM
 SG_ MirrDefrstAtPassSts : 31|1@0+ (1,0) [0|1] ""  CEM
 SG_ MirrDefrstAtPassSts_UB : 30|1@0+ (1,0) [0|1] ""  CEM
 SG_ MirrPosnFromCldAtPassIntFb : 47|2@0+ (1,0) [0|3] ""  DDM
 SG_ MirrPosnFromCldAtPassIntFb_UB : 45|1@0+ (1,0) [0|1] ""  DDM
 SG_ MirrPosnToCldAtPass_UB : 23|1@0+ (1,0) [0|1] ""  CEM
 SG_ MirrPosnToCldAtPassMirrPosnAdjCl : 7|8@0+ (1,0) [0|180] "Deg"  CEM
 SG_ MirrPosnToCldAtPassMirrPosn_0000 : 15|8@0+ (1,0) [0|180] "Deg"  CEM
 SG_ WinFailrStsAtPass : 44|1@0+ (1,0) [0|1] ""  CEM
 SG_ WinFailrStsAtPass_UB : 43|1@0+ (1,0) [0|1] ""  CEM

BO_ 565 PdmBodyFr04: 8 PDM
 SG_ DoorPassSwpLockBtn : 59|1@0+ (1,0) [0|1] ""  CEM
 SG_ DoorPassSwpLockBtn_UB : 57|1@0+ (1,0) [0|1] ""  CEM

BO_ 1284 PdmBodyNMFr: 8 PDM
 SG_ PNC16_PDM : 16|1@0+ (1,0) [0|0] ""  Vector_XXX
 SG_ PNC17_PDM : 17|1@0+ (1,0) [0|0] ""  Vector_XXX
 SG_ PNC18_PDM : 18|1@0+ (1,0) [0|0] ""  Vector_XXX
 SG_ PNC19_PDM : 19|1@0+ (1,0) [0|0] ""  Vector_XXX
 SG_ PNC20_PDM : 20|1@0+ (1,0) [0|0] ""  Vector_XXX
 SG_ PNC21_PDM : 21|1@0+ (1,0) [0|0] ""  Vector_XXX
 SG_ PNC22_PDM : 22|1@0+ (1,0) [0|0] ""  Vector_XXX
 SG_ PNC23_PDM : 23|1@0+ (1,0) [0|0] ""  Vector_XXX
 SG_ PNC24_PDM : 24|1@0+ (1,0) [0|0] ""  Vector_XXX
 SG_ PNC25_PDM : 25|1@0+ (1,0) [0|0] ""  Vector_XXX
 SG_ PNC26_PDM : 26|1@0+ (1,0) [0|0] ""  Vector_XXX
 SG_ PNC27_PDM : 27|1@0+ (1,0) [0|0] ""  Vector_XXX
 SG_ PNC28_PDM : 28|1@0+ (1,0) [0|0] ""  Vector_XXX
 SG_ PNC29_PDM : 29|1@0+ (1,0) [0|0] ""  Vector_XXX
 SG_ PNC30_PDM : 30|1@0+ (1,0) [0|0] ""  Vector_XXX
 SG_ PNC31_PDM : 31|1@0+ (1,0) [0|0] ""  Vector_XXX
 SG_ PNC32_PDM : 32|1@0+ (1,0) [0|0] ""  Vector_XXX
 SG_ PNC33_PDM : 33|1@0+ (1,0) [0|0] ""  Vector_XXX
 SG_ PNC34_PDM : 34|1@0+ (1,0) [0|0] ""  Vector_XXX
 SG_ PNC35_PDM : 35|1@0+ (1,0) [0|0] ""  Vector_XXX
 SG_ PNC36_PDM : 36|1@0+ (1,0) [0|0] ""  Vector_XXX
 SG_ PNC37_PDM : 37|1@0+ (1,0) [0|0] ""  Vector_XXX
 SG_ PNC38_PDM : 38|1@0+ (1,0) [0|0] ""  Vector_XXX
 SG_ PNC39_PDM : 39|1@0+ (1,0) [0|0] ""  Vector_XXX
 SG_ PNC40_PDM : 40|1@0+ (1,0) [0|0] ""  Vector_XXX
 SG_ PNC41_PDM : 41|1@0+ (1,0) [0|0] ""  Vector_XXX
 SG_ PNC42_PDM : 42|1@0+ (1,0) [0|0] ""  Vector_XXX
 SG_ NM_PNI_PDM : 14|1@0+ (1,0) [0|0] ""  Vector_XXX
 SG_ NM_AW_PDM : 12|1@0+ (1,0) [0|0] ""  Vector_XXX
 SG_ NM_CS_PDM : 11|1@0+ (1,0) [0|0] ""  Vector_XXX
 SG_ NM_RMR_PDM : 8|1@0+ (1,0) [0|0] ""  Vector_XXX
 SG_ NM_NodeID_PDM : 7|8@0+ (1,0) [0|0] ""  Vector_XXX

BO_ 1348 PdmBodyVFCVectorFr: 8 PDM
 SG_ VFCVectorPDMBlockID : 1|2@0+ (1,0) [0|3] "Unitless"  ETC
 SG_ VFCVectorPDMVFCid0 : 2|1@0+ (1,0) [0|1] ""  ETC
 SG_ VFCVectorPDMVFCid1 : 3|1@0+ (1,0) [0|1] ""  ETC
 SG_ VFCVectorPDMVFCid10 : 12|1@0+ (1,0) [0|1] ""  ETC
 SG_ VFCVectorPDMVFCid11 : 13|1@0+ (1,0) [0|1] ""  ETC
 SG_ VFCVectorPDMVFCid12 : 14|1@0+ (1,0) [0|1] ""  ETC
 SG_ VFCVectorPDMVFCid13 : 15|1@0+ (1,0) [0|1] ""  ETC
 SG_ VFCVectorPDMVFCid14 : 16|1@0+ (1,0) [0|1] ""  ETC
 SG_ VFCVectorPDMVFCid15 : 17|1@0+ (1,0) [0|1] ""  ETC
 SG_ VFCVectorPDMVFCid16 : 18|1@0+ (1,0) [0|1] ""  ETC
 SG_ VFCVectorPDMVFCid17 : 19|1@0+ (1,0) [0|1] ""  ETC
 SG_ VFCVectorPDMVFCid18 : 20|1@0+ (1,0) [0|1] ""  ETC
 SG_ VFCVectorPDMVFCid19 : 21|1@0+ (1,0) [0|1] ""  ETC
 SG_ VFCVectorPDMVFCid2 : 4|1@0+ (1,0) [0|1] ""  ETC
 SG_ VFCVectorPDMVFCid20 : 22|1@0+ (1,0) [0|1] ""  ETC
 SG_ VFCVectorPDMVFCid21 : 23|1@0+ (1,0) [0|1] ""  ETC
 SG_ VFCVectorPDMVFCid22 : 24|1@0+ (1,0) [0|1] ""  ETC
 SG_ VFCVectorPDMVFCid23 : 25|1@0+ (1,0) [0|1] ""  ETC
 SG_ VFCVectorPDMVFCid24 : 26|1@0+ (1,0) [0|1] ""  ETC
 SG_ VFCVectorPDMVFCid25 : 27|1@0+ (1,0) [0|1] ""  ETC
 SG_ VFCVectorPDMVFCid26 : 28|1@0+ (1,0) [0|1] ""  ETC
 SG_ VFCVectorPDMVFCid27 : 29|1@0+ (1,0) [0|1] ""  ETC
 SG_ VFCVectorPDMVFCid28 : 30|1@0+ (1,0) [0|1] ""  ETC
 SG_ VFCVectorPDMVFCid29 : 31|1@0+ (1,0) [0|1] ""  ETC
 SG_ VFCVectorPDMVFCid3 : 5|1@0+ (1,0) [0|1] ""  ETC
 SG_ VFCVectorPDMVFCid30 : 32|1@0+ (1,0) [0|1] ""  ETC
 SG_ VFCVectorPDMVFCid31 : 33|1@0+ (1,0) [0|1] ""  ETC
 SG_ VFCVectorPDMVFCid32 : 34|1@0+ (1,0) [0|1] ""  ETC
 SG_ VFCVectorPDMVFCid33 : 35|1@0+ (1,0) [0|1] ""  ETC
 SG_ VFCVectorPDMVFCid34 : 36|1@0+ (1,0) [0|1] ""  ETC
 SG_ VFCVectorPDMVFCid35 : 37|1@0+ (1,0) [0|1] ""  ETC
 SG_ VFCVectorPDMVFCid36 : 38|1@0+ (1,0) [0|1] ""  ETC
 SG_ VFCVectorPDMVFCid37 : 39|1@0+ (1,0) [0|1] ""  ETC
 SG_ VFCVectorPDMVFCid38 : 40|1@0+ (1,0) [0|1] ""  ETC
 SG_ VFCVectorPDMVFCid39 : 41|1@0+ (1,0) [0|1] ""  ETC
 SG_ VFCVectorPDMVFCid4 : 6|1@0+ (1,0) [0|1] ""  ETC
 SG_ VFCVectorPDMVFCid40 : 42|1@0+ (1,0) [0|1] ""  ETC
 SG_ VFCVectorPDMVFCid41 : 43|1@0+ (1,0) [0|1] ""  ETC
 SG_ VFCVectorPDMVFCid42 : 44|1@0+ (1,0) [0|1] ""  ETC
 SG_ VFCVectorPDMVFCid43 : 45|1@0+ (1,0) [0|1] ""  ETC
 SG_ VFCVectorPDMVFCid44 : 46|1@0+ (1,0) [0|1] ""  ETC
 SG_ VFCVectorPDMVFCid45 : 47|1@0+ (1,0) [0|1] ""  ETC
 SG_ VFCVectorPDMVFCid46 : 48|1@0+ (1,0) [0|1] ""  ETC
 SG_ VFCVectorPDMVFCid47 : 49|1@0+ (1,0) [0|1] ""  ETC
 SG_ VFCVectorPDMVFCid48 : 50|1@0+ (1,0) [0|1] ""  ETC
 SG_ VFCVectorPDMVFCid49 : 51|1@0+ (1,0) [0|1] ""  ETC
 SG_ VFCVectorPDMVFCid5 : 7|1@0+ (1,0) [0|1] ""  ETC
 SG_ VFCVectorPDMVFCid50 : 52|1@0+ (1,0) [0|1] ""  ETC
 SG_ VFCVectorPDMVFCid51 : 53|1@0+ (1,0) [0|1] ""  ETC
 SG_ VFCVectorPDMVFCid52 : 54|1@0+ (1,0) [0|1] ""  ETC
 SG_ VFCVectorPDMVFCid53 : 55|1@0+ (1,0) [0|1] ""  ETC
 SG_ VFCVectorPDMVFCid54 : 56|1@0+ (1,0) [0|1] ""  ETC
 SG_ VFCVectorPDMVFCid55 : 57|1@0+ (1,0) [0|1] ""  ETC
 SG_ VFCVectorPDMVFCid56 : 58|1@0+ (1,0) [0|1] ""  ETC
 SG_ VFCVectorPDMVFCid57 : 59|1@0+ (1,0) [0|1] ""  ETC
 SG_ VFCVectorPDMVFCid58 : 60|1@0+ (1,0) [0|1] ""  ETC
 SG_ VFCVectorPDMVFCid59 : 61|1@0+ (1,0) [0|1] ""  ETC
 SG_ VFCVectorPDMVFCid6 : 8|1@0+ (1,0) [0|1] ""  ETC
 SG_ VFCVectorPDMVFCid60 : 62|1@0+ (1,0) [0|1] ""  ETC
 SG_ VFCVectorPDMVFCid61 : 63|1@0+ (1,0) [0|1] ""  ETC
 SG_ VFCVectorPDMVFCid7 : 9|1@0+ (1,0) [0|1] ""  ETC
 SG_ VFCVectorPDMVFCid8 : 10|1@0+ (1,0) [0|1] ""  ETC
 SG_ VFCVectorPDMVFCid9 : 11|1@0+ (1,0) [0|1] ""  ETC

BO_ 1555 PdmToCemBodyDiagResFrame: 8 PDM
 SG_ PdmToCemBodyDiagResNpdu : 7|64@0+ (1,0) [0|0] ""  CEM

BO_ 1424 PdmToEtcXCPFr01: 8 PDM

BO_ 416 PotBodyFr01: 8 POT
 SG_ BodyMissComPrmntFromBoot : 0|1@0+ (1,0) [0|1] ""  CEM
 SG_ BodyMissComPrmntFromBoot_UB : 1|1@0+ (1,0) [0|1] ""  CEM

BO_ 149 PotBodyFr02: 8 POT
 SG_ SwtTrClsSts : 7|1@0+ (1,0) [0|1] ""  CEM
 SG_ SwtTrClsSts_UB : 6|1@0+ (1,0) [0|1] ""  CEM
 SG_ TopPosHmiFeedBack_UB : 56|1@0+ (1,0) [0|1] ""  CEM
 SG_ TopPosHmiFeedBackPerc13 : 62|5@0+ (4,0) [0|100] "%"  CEM
 SG_ TopPosHmiFeedBackUknFl : 57|1@0+ (1,0) [0|1] ""  CEM
 SG_ TrAntiPnch : 8|1@0+ (1,0) [0|1] ""  CEM
 SG_ TrAntiPnch_UB : 9|1@0+ (1,0) [0|1] ""  CEM
 SG_ TrObstclDetn : 10|1@0+ (1,0) [0|1] ""  CEM
 SG_ TrObstclDetn_UB : 11|1@0+ (1,0) [0|1] ""  CEM
 SG_ TrOpenerSts : 3|4@0+ (1,0) [0|15] ""  CEM
 SG_ TrOpenerSts_UB : 4|1@0+ (1,0) [0|1] ""  CEM
 SG_ TrRelsFailtoHMI : 5|1@0+ (1,0) [0|1] ""  CEM
 SG_ TrRelsFailtoHMI_UB : 23|1@0+ (1,0) [0|1] ""  CEM

BO_ 1287 PotBodyNMFr: 8 POT
 SG_ PNC16_POT : 16|1@0+ (1,0) [0|0] ""  PDM
 SG_ PNC17_POT : 17|1@0+ (1,0) [0|0] ""  PDM
 SG_ PNC18_POT : 18|1@0+ (1,0) [0|0] ""  PDM
 SG_ PNC19_POT : 19|1@0+ (1,0) [0|0] ""  PDM
 SG_ PNC20_POT : 20|1@0+ (1,0) [0|0] ""  PDM
 SG_ PNC21_POT : 21|1@0+ (1,0) [0|0] ""  PDM
 SG_ PNC22_POT : 22|1@0+ (1,0) [0|0] ""  PDM
 SG_ PNC23_POT : 23|1@0+ (1,0) [0|0] ""  PDM
 SG_ PNC24_POT : 24|1@0+ (1,0) [0|0] ""  PDM
 SG_ PNC25_POT : 25|1@0+ (1,0) [0|0] ""  PDM
 SG_ PNC26_POT : 26|1@0+ (1,0) [0|0] ""  PDM
 SG_ PNC27_POT : 27|1@0+ (1,0) [0|0] ""  PDM
 SG_ PNC28_POT : 28|1@0+ (1,0) [0|0] ""  PDM
 SG_ PNC29_POT : 29|1@0+ (1,0) [0|0] ""  PDM
 SG_ PNC30_POT : 30|1@0+ (1,0) [0|0] ""  PDM
 SG_ PNC31_POT : 31|1@0+ (1,0) [0|0] ""  PDM
 SG_ PNC32_POT : 32|1@0+ (1,0) [0|0] ""  PDM
 SG_ PNC33_POT : 33|1@0+ (1,0) [0|0] ""  PDM
 SG_ PNC34_POT : 34|1@0+ (1,0) [0|0] ""  PDM
 SG_ PNC35_POT : 35|1@0+ (1,0) [0|0] ""  PDM
 SG_ PNC36_POT : 36|1@0+ (1,0) [0|0] ""  PDM
 SG_ PNC37_POT : 37|1@0+ (1,0) [0|0] ""  PDM
 SG_ PNC38_POT : 38|1@0+ (1,0) [0|0] ""  PDM
 SG_ PNC39_POT : 39|1@0+ (1,0) [0|0] ""  PDM
 SG_ PNC40_POT : 40|1@0+ (1,0) [0|0] ""  PDM
 SG_ PNC41_POT : 41|1@0+ (1,0) [0|0] ""  PDM
 SG_ PNC42_POT : 42|1@0+ (1,0) [0|0] ""  PDM
 SG_ NM_PNI_POT : 14|1@0+ (1,0) [0|0] ""  PDM
 SG_ NM_AW_POT : 12|1@0+ (1,0) [0|0] ""  PDM
 SG_ NM_CS_POT : 11|1@0+ (1,0) [0|0] ""  PDM
 SG_ NM_RMR_POT : 8|1@0+ (1,0) [0|0] ""  PDM
 SG_ NM_NodeID_POT : 7|8@0+ (1,0) [0|0] ""  PDM

BO_ 1351 PotBodyVFCVectorFr: 8 POT
 SG_ VFCVectorPOTBlockID : 1|2@0+ (1,0) [0|3] "Unitless"  ETC
 SG_ VFCVectorPOTVFCid0 : 2|1@0+ (1,0) [0|1] ""  ETC
 SG_ VFCVectorPOTVFCid1 : 3|1@0+ (1,0) [0|1] ""  ETC
 SG_ VFCVectorPOTVFCid10 : 12|1@0+ (1,0) [0|1] ""  ETC
 SG_ VFCVectorPOTVFCid11 : 13|1@0+ (1,0) [0|1] ""  ETC
 SG_ VFCVectorPOTVFCid12 : 14|1@0+ (1,0) [0|1] ""  ETC
 SG_ VFCVectorPOTVFCid13 : 15|1@0+ (1,0) [0|1] ""  ETC
 SG_ VFCVectorPOTVFCid14 : 16|1@0+ (1,0) [0|1] ""  ETC
 SG_ VFCVectorPOTVFCid15 : 17|1@0+ (1,0) [0|1] ""  ETC
 SG_ VFCVectorPOTVFCid16 : 18|1@0+ (1,0) [0|1] ""  ETC
 SG_ VFCVectorPOTVFCid17 : 19|1@0+ (1,0) [0|1] ""  ETC
 SG_ VFCVectorPOTVFCid18 : 20|1@0+ (1,0) [0|1] ""  ETC
 SG_ VFCVectorPOTVFCid19 : 21|1@0+ (1,0) [0|1] ""  ETC
 SG_ VFCVectorPOTVFCid2 : 4|1@0+ (1,0) [0|1] ""  ETC
 SG_ VFCVectorPOTVFCid20 : 22|1@0+ (1,0) [0|1] ""  ETC
 SG_ VFCVectorPOTVFCid21 : 23|1@0+ (1,0) [0|1] ""  ETC
 SG_ VFCVectorPOTVFCid22 : 24|1@0+ (1,0) [0|1] ""  ETC
 SG_ VFCVectorPOTVFCid23 : 25|1@0+ (1,0) [0|1] ""  ETC
 SG_ VFCVectorPOTVFCid24 : 26|1@0+ (1,0) [0|1] ""  ETC
 SG_ VFCVectorPOTVFCid25 : 27|1@0+ (1,0) [0|1] ""  ETC
 SG_ VFCVectorPOTVFCid26 : 28|1@0+ (1,0) [0|1] ""  ETC
 SG_ VFCVectorPOTVFCid27 : 29|1@0+ (1,0) [0|1] ""  ETC
 SG_ VFCVectorPOTVFCid28 : 30|1@0+ (1,0) [0|1] ""  ETC
 SG_ VFCVectorPOTVFCid29 : 31|1@0+ (1,0) [0|1] ""  ETC
 SG_ VFCVectorPOTVFCid3 : 5|1@0+ (1,0) [0|1] ""  ETC
 SG_ VFCVectorPOTVFCid30 : 32|1@0+ (1,0) [0|1] ""  ETC
 SG_ VFCVectorPOTVFCid31 : 33|1@0+ (1,0) [0|1] ""  ETC
 SG_ VFCVectorPOTVFCid32 : 34|1@0+ (1,0) [0|1] ""  ETC
 SG_ VFCVectorPOTVFCid33 : 35|1@0+ (1,0) [0|1] ""  ETC
 SG_ VFCVectorPOTVFCid34 : 36|1@0+ (1,0) [0|1] ""  ETC
 SG_ VFCVectorPOTVFCid35 : 37|1@0+ (1,0) [0|1] ""  ETC
 SG_ VFCVectorPOTVFCid36 : 38|1@0+ (1,0) [0|1] ""  ETC
 SG_ VFCVectorPOTVFCid37 : 39|1@0+ (1,0) [0|1] ""  ETC
 SG_ VFCVectorPOTVFCid38 : 40|1@0+ (1,0) [0|1] ""  ETC
 SG_ VFCVectorPOTVFCid39 : 41|1@0+ (1,0) [0|1] ""  ETC
 SG_ VFCVectorPOTVFCid4 : 6|1@0+ (1,0) [0|1] ""  ETC
 SG_ VFCVectorPOTVFCid40 : 42|1@0+ (1,0) [0|1] ""  ETC
 SG_ VFCVectorPOTVFCid41 : 43|1@0+ (1,0) [0|1] ""  ETC
 SG_ VFCVectorPOTVFCid42 : 44|1@0+ (1,0) [0|1] ""  ETC
 SG_ VFCVectorPOTVFCid43 : 45|1@0+ (1,0) [0|1] ""  ETC
 SG_ VFCVectorPOTVFCid44 : 46|1@0+ (1,0) [0|1] ""  ETC
 SG_ VFCVectorPOTVFCid45 : 47|1@0+ (1,0) [0|1] ""  ETC
 SG_ VFCVectorPOTVFCid46 : 48|1@0+ (1,0) [0|1] ""  ETC
 SG_ VFCVectorPOTVFCid47 : 49|1@0+ (1,0) [0|1] ""  ETC
 SG_ VFCVectorPOTVFCid48 : 50|1@0+ (1,0) [0|1] ""  ETC
 SG_ VFCVectorPOTVFCid49 : 51|1@0+ (1,0) [0|1] ""  ETC
 SG_ VFCVectorPOTVFCid5 : 7|1@0+ (1,0) [0|1] ""  ETC
 SG_ VFCVectorPOTVFCid50 : 52|1@0+ (1,0) [0|1] ""  ETC
 SG_ VFCVectorPOTVFCid51 : 53|1@0+ (1,0) [0|1] ""  ETC
 SG_ VFCVectorPOTVFCid52 : 54|1@0+ (1,0) [0|1] ""  ETC
 SG_ VFCVectorPOTVFCid53 : 55|1@0+ (1,0) [0|1] ""  ETC
 SG_ VFCVectorPOTVFCid54 : 56|1@0+ (1,0) [0|1] ""  ETC
 SG_ VFCVectorPOTVFCid55 : 57|1@0+ (1,0) [0|1] ""  ETC
 SG_ VFCVectorPOTVFCid56 : 58|1@0+ (1,0) [0|1] ""  ETC
 SG_ VFCVectorPOTVFCid57 : 59|1@0+ (1,0) [0|1] ""  ETC
 SG_ VFCVectorPOTVFCid58 : 60|1@0+ (1,0) [0|1] ""  ETC
 SG_ VFCVectorPOTVFCid59 : 61|1@0+ (1,0) [0|1] ""  ETC
 SG_ VFCVectorPOTVFCid6 : 8|1@0+ (1,0) [0|1] ""  ETC
 SG_ VFCVectorPOTVFCid60 : 62|1@0+ (1,0) [0|1] ""  ETC
 SG_ VFCVectorPOTVFCid61 : 63|1@0+ (1,0) [0|1] ""  ETC
 SG_ VFCVectorPOTVFCid7 : 9|1@0+ (1,0) [0|1] ""  ETC
 SG_ VFCVectorPOTVFCid8 : 10|1@0+ (1,0) [0|1] ""  ETC
 SG_ VFCVectorPOTVFCid9 : 11|1@0+ (1,0) [0|1] ""  ETC

BO_ 1557 PotToCemBodyDiagResFrame: 8 POT
 SG_ PotToCemBodyDiagResNpdu : 7|64@0+ (1,0) [0|0] ""  CEM

BO_ 1466 PotToEtcXCPFr01: 8 POT

CM_ SG_ 820 ExtrLtgStsAFS "AFS status";
CM_ SG_ 820 ExtrLtgStsAHBC "AHBC Status";
CM_ SG_ 820 ExtrLtgStsAHL "AHL Status";
CM_ SG_ 820 ExtrLtgStsAllWL "All Weather Light Status";
CM_ SG_ 820 ExtrLtgStsApproach "Approach Light Status";
CM_ SG_ 820 ExtrLtgStsChks "Checksum";
CM_ SG_ 820 ExtrLtgStsCntr "Counter";
CM_ SG_ 820 ExtrLtgStsCornrgLi "Cornering Light Status";
CM_ SG_ 820 ExtrLtgStsDBL "DBL Stataus";
CM_ SG_ 820 ExtrLtgStsDRL "DRL Status";
CM_ SG_ 820 ExtrLtgStsFlash "Flash Light Status";
CM_ SG_ 820 ExtrLtgStsFrntFog "Front Fog Light Status";
CM_ SG_ 820 ExtrLtgStsGoodbye "Good Bye Light Status";
CM_ SG_ 820 ExtrLtgStsHiBeam "Hi Beam Status";
CM_ SG_ 820 ExtrLtgStsHomeSafe "Home Safe Light Status";
CM_ SG_ 820 ExtrLtgStsHWL "HWL Status";
CM_ SG_ 820 ExtrLtgStsLoBeam "Low Beam Status";
CM_ SG_ 820 ExtrLtgStsLtgShow "Light Show Status";
CM_ SG_ 820 ExtrLtgStsPosLiFrnt "Position Light Front Status";
CM_ SG_ 820 ExtrLtgStsPosLiRe "Position Light Rear Status";
CM_ SG_ 820 ExtrLtgStsReFog "Rear Fog Light Status";
CM_ SG_ 820 ExtrLtgStsReverseLi "Reverse Light Status";
CM_ SG_ 820 ExtrLtgStsStopLi "Stop Light Status";
CM_ SG_ 820 ExtrLtgStsTurnIndrLe "Turn Indicator Left Status";
CM_ SG_ 820 ExtrLtgStsTurnIndrRi "Turn Indicator Right Status
";
CM_ SG_ 820 ExtrLtgStsWelcome "Welcome Light Status";
CM_ SG_ 836 ADIntrLiCtrlReq "Atmosphere light request for AD function.";
CM_ SG_ 836 AmbientLiEffectStatusBreathingEf "Breathing effect enable or disable";
CM_ SG_ 836 AmbientLiEffectStatusIdPen "Profile save";
CM_ SG_ 836 AmbientLiEffectStatusTransitionE "Transition effect enable or disable";
CM_ SG_ 836 AmbLiEnduranceMilgOpenReqIdPen "Ambience light endurance mileage remind";
CM_ SG_ 836 AmbLiEnduranceMilgOpenReqOnOff1 "Ambience light endurance mileage remind";
CM_ SG_ 836 CallSts "call status";
CM_ SG_ 836 Zone1SettingsBlue "Color settings for zone 1";
CM_ SG_ 836 Zone1SettingsGreen "Color settings for zone 1";
CM_ SG_ 836 Zone1SettingsIdPen "Idpen";
CM_ SG_ 836 Zone1SettingsIntensity "Intensity settings for zone 1";
CM_ SG_ 836 Zone1SettingsRed "Color settings for zone 1";
CM_ SG_ 836 Zone1SettingsZoneStatus "Zone status settings for zone 1";
CM_ SG_ 840 AmbLiPhoneOpenReqIdPen "Ambience light phone reminding open request";
CM_ SG_ 840 AmbLiPhoneOpenReqOnOff1 "Ambience light phone reminding open request";
CM_ SG_ 840 FuLvlLoWarn "Signal that indicated if the RED low fuel warning LED is lit";
CM_ SG_ 840 GoodbyeLiOpenReqIdPen "Open or close ambience light goodbye show";
CM_ SG_ 840 GoodbyeLiOpenReqOnOff1 "Open or close ambience light goodbye show";
CM_ SG_ 840 WelcomeLiOpenReqIdPen "Welcome light open or close request";
CM_ SG_ 840 WelcomeLiOpenReqOnOff1 "Welcome light open or close request";
CM_ SG_ 840 Zone2SettingsBlue "Color settings for zone 2";
CM_ SG_ 840 Zone2SettingsGreen "Color settings for zone 2";
CM_ SG_ 840 Zone2SettingsIdPen "Idpen";
CM_ SG_ 840 Zone2SettingsIntensity "Intensity settings for zone 2";
CM_ SG_ 840 Zone2SettingsRed "Color settings for zone 2";
CM_ SG_ 840 Zone2SettingsZoneStatus "Zone status settings for zone 2";
CM_ SG_ 844 AmbLiAllIdPen "A main on/off button to control Ambience light";
CM_ SG_ 844 AmbLiAllOnOff1 "A main on/off button to control Ambience light";
CM_ SG_ 844 DispHvBattLvlOfChrg "HV battery State-Of-Charge (SOC) value for display to driver. Note: this value may differ from the actual battery SOC. ";
CM_ SG_ 844 WthrInfoFromCnctSrv "Weather information from Connected Service";
CM_ SG_ 844 Zone3SettingsBlue "Color settings for zone 3";
CM_ SG_ 844 Zone3SettingsGreen "Color settings for zone 3";
CM_ SG_ 844 Zone3SettingsIdPen "Idpen";
CM_ SG_ 844 Zone3SettingsIntensity "Intensity settings for zone 3";
CM_ SG_ 844 Zone3SettingsRed "Color settings for zone 3";
CM_ SG_ 844 Zone3SettingsZoneStatus "Zone status settings for zone 3";
CM_ SG_ 34 MusicInfoForMusicShow1DownSampli "The down-sampling amplitude of 10ms raw PCM audio data ";
CM_ SG_ 34 MusicInfoForMusicShow1MaxFFT100m "The amplitude of max amplitude-frequency point among
100Hz-2.65kHz,";
CM_ SG_ 34 MusicInfoForMusicShow1MaxFF_0000 "The frequency of max amplitude-frequency point among
100Hz-2.65kHz,";
CM_ SG_ 34 MusicInfoForMusicShow1Segment1FF "10ms amplitude-frequency results of 1st segment";
CM_ SG_ 34 MusicInfoForMusicShow1Segment2FF "10ms amplitude-frequency results of 2nd segment";
CM_ SG_ 34 MusicInfoForMusicShow1Segment3FF "10ms amplitude-frequency results of 3rd segment";
CM_ SG_ 34 MusicInfoForMusicShow1Segment4FF "10ms amplitude-frequency results of 4th segment";
CM_ SG_ 34 MusicInfoForMusicShow1Segment5FF "10ms amplitude-frequency results of 5th segment";
CM_ SG_ 34 MusicInfoForMusicShow1Segment6FF "10ms amplitude-frequency results of 6th segment";
CM_ SG_ 34 MusicInfoForMusicShow1Segment7FF "10ms amplitude-frequency results of 7th segment";
CM_ SG_ 34 MusicInfoForMusicShow1Segment8FF "10ms amplitude-frequency results of 8th segment";
CM_ SG_ 34 MusicInfoForMusicShow1StateFlagA "The flag of audio playing status";
CM_ SG_ 34 MusicInfoForMusicShow1StateFlagN "The flag of a new audio";
CM_ SG_ 34 MusicInfoForMusicShow1TimeFlagAu "The time stamp of the playing audio";
CM_ SG_ 34 MusicInfoForMusicShow1TimeFlagMe "The time stamp of data transmission";
CM_ SG_ 34 SecRowRiCmftSet "One-key seat comfort or recover position adjustment control for Second row right customer.";
CM_ SG_ 34 WinOpenLDACReq "Lower windows request from LDAC";
CM_ SG_ 827 ClimaCmd "Indicates whether the climate sub-system is allowed by CELC to start a requested operation.";
CM_ SG_ 827 ErsCmdByKey "Signaling Engine Remote Start commands from the keyfob.

- ErsCmdNotSet: No ERS command active
- ErsCmdOn: Keyfob command to start ERS
- ErsCmdOff: Keyfob command to stop ERS";
CM_ SG_ 827 PostHeatgRunTiEstimd "Estimated heating afterrun time.";
CM_ SG_ 827 RainfallAmnt "The signal describe the amount of rain falling";
CM_ SG_ 827 TInCooltAtStrtOfClima "Temperature measured by the heater in the coolant at the start of the latest pre-conditioning.";
CM_ SG_ 48 ChdLockLeftCmd "Signal sent from the Driver door module to the locking and window functionality in the left rear door module. The signal contains information whether the power window disable function and the electric child lock function shall be enabled or disabled.";
CM_ SG_ 48 ChdLockRightStsToHmi "Signal sent from the Driver door module to the Driver information module to inform if the electric child lock  is ative or not for right rear door";
CM_ SG_ 48 DoorDrvrHndlHMIStsDeployedOverTm "Signal Utilized to communicate to HMI subsystem the following specific events in Driver door
Handle retract over timed On-Off
Handle deploy over timed On-Off
Unsuccessful  Hall sensor reset On-Off";
CM_ SG_ 48 DoorDrvrHndlHMIStsReserved1 "Signal Utilized to communicate to HMI subsystem the following specific events in Driver door
Handle retract over timed On-Off
Handle deploy over timed On-Off
Unsuccessful  Hall sensor reset On-Off";
CM_ SG_ 48 DoorDrvrHndlHMIStsRetractOverTmd "Signal Utilized to communicate to HMI subsystem the following specific events in Driver door
Handle retract over timed On-Off
Handle deploy over timed On-Off
Unsuccessful  Hall sensor reset On-Off";
CM_ SG_ 48 DoorDrvrHndlHMIStsUnsScsHallSnsr "Signal Utilized to communicate to HMI subsystem the following specific events in Driver door
Handle retract over timed On-Off
Handle deploy over timed On-Off
Unsuccessful  Hall sensor reset On-Off";
CM_ SG_ 48 DoorDrvrRelsFailCinchOverTimed "Cinch processwas not successfull. It is overtimed.";
CM_ SG_ 48 DoorDrvrRelsFailFailure1 "Issue described by requiremnt according to specific project";
CM_ SG_ 48 DoorDrvrRelsFailMechRels "Door Mechanical release (No Power operated)";
CM_ SG_ 48 FltOfIndcrTurnOnDrvrSide "Light source failure (open load or short circuit) indication to driver, side direction indicator driver side.";
CM_ SG_ 48 MemBtnPsdMemBtn1 "Driver Memory Button 2";
CM_ SG_ 48 MemBtnPsdMemBtn2 "Driver Memory Button 2";
CM_ SG_ 48 MemBtnPsdMemBtn3 "Driver Memory Button 3";
CM_ SG_ 48 MemBtnPsdMemButM "Driver Memory Button";
CM_ SG_ 48 MirrFoldStsAtDrvr "Reports the fold status of the outer rear view mirrors. Driver side.";
CM_ SG_ 48 ShortDropWinDrvrSts "Short drop a status sent back to locking to secure window is down and door is ready to be released. ";
CM_ SG_ 48 WinDsblRightCmd "Rear Right Window Switch Control";
CM_ SG_ 48 WinFailrStsAtDrvr "Report failure if Window motor is not possible to Run";
CM_ SG_ 480 AmbTRawAtDrvrSideAmbTVal "Unfiltered ambient temp raw data in deg C";
CM_ SG_ 480 AmbTRawAtDrvrSideQly "quality";
CM_ SG_ 480 ChdLockRightFailStsToHmi "Signal sent from the Driver door module to the Driver information module to inform if there is a failure in the electric child lock funtionality for right rear door";
CM_ SG_ 480 MirrDefrstAtDrvSts "Status signal exterior rear view mirror electrical defroster driver side.";
CM_ SG_ 291 AmbTURawAtDrvrSide "Ambient temp raw data in deg C at Driver side";
CM_ SG_ 291 DoorDrvrCinhIntFailInfCinchFlt1 "Cinch fault";
CM_ SG_ 291 DoorDrvrCinhIntFailInfCinchRestF "Cinch reset fault";
CM_ SG_ 291 DoorDrvrHndlSts "To inform about driver door handle status, i.e. unknown, opened, closed according to
DoorDrvrHndlSts
- Ukwn
- FullRtrctd
- MovgOut
- StopDurgDply
- FullDplyd
- MovgIn
- StopDurgRtrct
- Flt";
CM_ SG_ 291 DoorDrvrSwpLockBtn "Door Driver swiping locking status";
CM_ SG_ 291 MirrDwnStsAtDrvr "Reports the status of the mirror dipping mode. Driver side.";
CM_ SG_ 291 MirrPosnAdjFromCldPassMirrPosnAd "Passenger Mirror Position adjustment from Cloud Lef-Right";
CM_ SG_ 291 MirrPosnAdjFromCldPassMirrP_0000 "Passenger Mirror Position adjustment from Cloud Up-Down";
CM_ SG_ 291 MirrPosnToCldAtDrvrMirrPosnAdjCl "Mirror Position send to Cloud Left-Right";
CM_ SG_ 291 MirrPosnToCldAtDrvrMirrPosn_0000 "Mirror Position send to Cloud Up-Down";
CM_ SG_ 5 ChdLockRightCmd "Signal sent from the Driver door module to the locking and window functionality in the right rear door module. The signal contains information whether the power window disable function and the electric child lock function shall be enabled or disabled.";
CM_ SG_ 5 ChdPrtnLeftFailStsToHmi "Signal sent from the Driver door module to the Driver information module to inform if there is a failure in the electric child lock funtionality";
CM_ SG_ 5 ChdPrtnLeftStsToHmi "Signal sent from the Driver door module to the Driver information module to inform if the electric child lock  is ative or not";
CM_ SG_ 5 DoorDrvrLatPawlSt "Used to indicate if the driver door actuator must be triggered based in the pawl switch status AND other conditions from Driver door latch. [Close] Door is fully closed, the Pawl switch has changed value to PSD and timer to reach ajar is out without reaching ajar. [Open] Pawl Switch has not changed status to [PSD] OR latch successfully reach Ajar position within time. [Undefined] Not enough information about Pawl Switch status is found";
CM_ SG_ 5 DoorDrvrLatPosn "Driver door Cinch position. x01 equal fully open, x02 equal secondary position, x03 equal fully closed.";
CM_ SG_ 5 DoorDrvrLockSts "DoorDrvrLockSts - Driver Door Lock Status
Lock status
LockStsUkwn - Lock Status Unknown
Unlckd - Unlocked
Lockd - Locked
SafeLockd - Safe Locked (Double Locked)";
CM_ SG_ 5 DoorDrvrOpenLowReqOutdSwt1 "DoorDrvrOpenLowReqOutdSwt1 - Driver Door Open Request from Outside Switch 1 - Traditional door (No Power operated). Button status of the outside driver door handle switch connection 1.
Psd - Pressed
NotPsd - Not Pressed
NoInfo1/2 - Invalid";
CM_ SG_ 5 DoorDrvrOpenReqInsdSwt1 "DoorDrvrOpenReqInsdSwt1 - Driver Door Open Request from Inside Switch 1
Button status of the inside driver door handle switch connection 1
Psd - Pressed
NotPsd - Not Pressed
NoInfo1/2 - Invalid";
CM_ SG_ 5 DoorDrvrSwtIntrLockgReq "DoorDrvrSwtIntrLockgReq - Driver Door Interior Locking Switch Request
Central locking-unlocking request from driver door interior central locking-unlocking switch
Idle - No Request
Unlck - Unlock request
Lock - Lock request";
CM_ SG_ 5 LcmaLedStsDrvrSide "LED status in Driver side rear mirror.";
CM_ SG_ 5 MirrAtDrvrInMovmt "Informs the Setting Management subsystem that the outer rear view mirrors are in movement. Driver side.";
CM_ SG_ 5 MirrBtnPsdAtDrvr "Tells if any mirror button has been pressed.";
CM_ SG_ 5 MirrCmdAtPassMirrDwnCmd "Mirror Down/Dip Command";
CM_ SG_ 5 MirrCmdAtPassMirrFoldCmd "Mirror Fold Command";
CM_ SG_ 5 MirrCmdAtPassMirrPosAdjCmd "Mirror Position Adjust Command";
CM_ SG_ 5 MirrPosnDownLdSts "Mirror position Download Status.";
CM_ SG_ 5 MirrPosnFromCldAtDrvrFb "Mirror position feedback to ProfMgr";
CM_ SG_ 5 MirrPosnFromCldAtPassFb "Mirror position feedback to ProfMgr";
CM_ SG_ 5 MirrPosnMemSts "Mirror Position memory status.";
CM_ SG_ 5 WinDsblLeftCmd "Turn local rear window switch ON/OFF";
CM_ SG_ 5 WinPosnStsAtDrvr "Signal sent to inform the rest of the car of the window position status for the front driver side door. The value of the signal is either an approximated percentage of openness, of the window is moving or if the position is unkown.
";
CM_ SG_ 192 CenLockMacKeyReq "Mechanical key central control lock lock request";
CM_ SG_ 192 WinSwtReqChks "Checksum";
CM_ SG_ 192 WinSwtReqCntr "Counter";
CM_ SG_ 192 WinSwtReqFrntLe "Signal from the Driver door switchpack to the Door modules containing the state of the window switches. Front left. ";
CM_ SG_ 192 WinSwtReqFrntRi "Signal from the Driver door switchpack to the Door modules containing the state of the window switches. Front right. ";
CM_ SG_ 192 WinSwtReqReLe "Signal from the Driver door switchpack to the Door modules containing the state of the window switches. Rear left. ";
CM_ SG_ 192 WinSwtReqReRi "Signal from the Driver door switchpack to the Door modules containing the state of the window switches.  Rear right. ";
CM_ SG_ 1021 DDSPartNo10CmplEndSgn1 " First letter of suffix";
CM_ SG_ 1021 DDSPartNo10CmplEndSgn2 " Second letter of suffix";
CM_ SG_ 1021 DDSPartNo10CmplEndSgn3 " Third letter of suffix";
CM_ SG_ 1021 DDSPartNo10CmplNr1 " First two BCD numbers";
CM_ SG_ 1021 DDSPartNo10CmplNr2 " Second two BCD numbers";
CM_ SG_ 1021 DDSPartNo10CmplNr3 " Third two BCD numbers";
CM_ SG_ 1021 DDSPartNo10CmplNr4 " Fourth pair of BCD numbers";
CM_ SG_ 1021 DDSPartNo10CmplNr5 " Fifth pair of BCD numbers";
CM_ SG_ 1022 DDSPartNoCmplEndSgn1 " First letter of suffix";
CM_ SG_ 1022 DDSPartNoCmplEndSgn2 " Second letter of suffix";
CM_ SG_ 1022 DDSPartNoCmplEndSgn3 " Third letter of suffix";
CM_ SG_ 1022 DDSPartNoCmplNr1 " First two BCD numbers";
CM_ SG_ 1022 DDSPartNoCmplNr2 " Second two BCD numbers";
CM_ SG_ 1022 DDSPartNoCmplNr3 " Third two BCD numbers";
CM_ SG_ 1022 DDSPartNoCmplNr4 " Fourth pair of BCD numbers";
CM_ SG_ 1023 DDSSerNoNr1 "Most significant byte of the serial number.";
CM_ SG_ 1023 DDSSerNoNr2 "Byte 2 of the serial number";
CM_ SG_ 1023 DDSSerNoNr3 "Byte 3 of the serial number";
CM_ SG_ 1023 DDSSerNoNr4 "Least significant byte of the serial number";
CM_ SG_ 1347 VFCVectorDDMBlockID "Block Identifier";
CM_ SG_ 1347 VFCVectorDDMVFCid0 "VFC0";
CM_ SG_ 1347 VFCVectorDDMVFCid1 "VFC1";
CM_ SG_ 1347 VFCVectorDDMVFCid10 "VFC10";
CM_ SG_ 1347 VFCVectorDDMVFCid11 "VFC11";
CM_ SG_ 1347 VFCVectorDDMVFCid12 "VFC12";
CM_ SG_ 1347 VFCVectorDDMVFCid13 "VFC13";
CM_ SG_ 1347 VFCVectorDDMVFCid14 "VFC14";
CM_ SG_ 1347 VFCVectorDDMVFCid15 "VFC15";
CM_ SG_ 1347 VFCVectorDDMVFCid16 "VFC16";
CM_ SG_ 1347 VFCVectorDDMVFCid17 "VFC17";
CM_ SG_ 1347 VFCVectorDDMVFCid18 "VFC18";
CM_ SG_ 1347 VFCVectorDDMVFCid19 "VFC19";
CM_ SG_ 1347 VFCVectorDDMVFCid2 "VFC2";
CM_ SG_ 1347 VFCVectorDDMVFCid20 "VFC20";
CM_ SG_ 1347 VFCVectorDDMVFCid21 "VFC21";
CM_ SG_ 1347 VFCVectorDDMVFCid22 "VFC22";
CM_ SG_ 1347 VFCVectorDDMVFCid23 "VFC23";
CM_ SG_ 1347 VFCVectorDDMVFCid24 "VFC24";
CM_ SG_ 1347 VFCVectorDDMVFCid25 "VFC25";
CM_ SG_ 1347 VFCVectorDDMVFCid26 "VFC26";
CM_ SG_ 1347 VFCVectorDDMVFCid27 "VFC27";
CM_ SG_ 1347 VFCVectorDDMVFCid28 "VFC28";
CM_ SG_ 1347 VFCVectorDDMVFCid29 "VFC29";
CM_ SG_ 1347 VFCVectorDDMVFCid3 "VFC3";
CM_ SG_ 1347 VFCVectorDDMVFCid30 "VFC30";
CM_ SG_ 1347 VFCVectorDDMVFCid31 "VFC31";
CM_ SG_ 1347 VFCVectorDDMVFCid32 "VFC32";
CM_ SG_ 1347 VFCVectorDDMVFCid33 "VFC33";
CM_ SG_ 1347 VFCVectorDDMVFCid34 "VFC34";
CM_ SG_ 1347 VFCVectorDDMVFCid35 "VFC35";
CM_ SG_ 1347 VFCVectorDDMVFCid36 "VFC36";
CM_ SG_ 1347 VFCVectorDDMVFCid37 "VFC37";
CM_ SG_ 1347 VFCVectorDDMVFCid38 "VFC38";
CM_ SG_ 1347 VFCVectorDDMVFCid39 "VFC39";
CM_ SG_ 1347 VFCVectorDDMVFCid4 "VFC4";
CM_ SG_ 1347 VFCVectorDDMVFCid40 "VFC40";
CM_ SG_ 1347 VFCVectorDDMVFCid41 "VFC41";
CM_ SG_ 1347 VFCVectorDDMVFCid42 "VFC42";
CM_ SG_ 1347 VFCVectorDDMVFCid43 "VFC43";
CM_ SG_ 1347 VFCVectorDDMVFCid44 "VFC44";
CM_ SG_ 1347 VFCVectorDDMVFCid45 "VFC45";
CM_ SG_ 1347 VFCVectorDDMVFCid46 "VFC46";
CM_ SG_ 1347 VFCVectorDDMVFCid47 "VFC47";
CM_ SG_ 1347 VFCVectorDDMVFCid48 "VFC48";
CM_ SG_ 1347 VFCVectorDDMVFCid49 "VFC49";
CM_ SG_ 1347 VFCVectorDDMVFCid5 "VFC5";
CM_ SG_ 1347 VFCVectorDDMVFCid50 "VFC50";
CM_ SG_ 1347 VFCVectorDDMVFCid51 "VFC51";
CM_ SG_ 1347 VFCVectorDDMVFCid52 "VFC52";
CM_ SG_ 1347 VFCVectorDDMVFCid53 "VFC53";
CM_ SG_ 1347 VFCVectorDDMVFCid54 "VFC54";
CM_ SG_ 1347 VFCVectorDDMVFCid55 "VFC55";
CM_ SG_ 1347 VFCVectorDDMVFCid56 "VFC56";
CM_ SG_ 1347 VFCVectorDDMVFCid57 "VFC57";
CM_ SG_ 1347 VFCVectorDDMVFCid58 "VFC58";
CM_ SG_ 1347 VFCVectorDDMVFCid59 "VFC59";
CM_ SG_ 1347 VFCVectorDDMVFCid6 "VFC6";
CM_ SG_ 1347 VFCVectorDDMVFCid60 "VFC60";
CM_ SG_ 1347 VFCVectorDDMVFCid61 "VFC61";
CM_ SG_ 1347 VFCVectorDDMVFCid7 "VFC7";
CM_ SG_ 1347 VFCVectorDDMVFCid8 "VFC8";
CM_ SG_ 1347 VFCVectorDDMVFCid9 "VFC9";
CM_ SG_ 1425 SMBdevelpsignalgroupreqFunctiond "develop signal group request";
CM_ SG_ 1425 SMBdevelpsignalgroupreqFunc_0000 "develop signal group request";
CM_ SG_ 1425 SMBdevelpsignalgroupreqFunc_0001 "develop signal group request";
CM_ SG_ 1425 SMBdevelpsignalgroupreqFunc_0002 "develop signal group request";
CM_ SG_ 1425 SMBdevelpsignalgroupreqFunc_0003 "develop signal group request";
CM_ SG_ 1425 SMBdevelpsignalgroupreqFunc_0004 "develop signal group request";
CM_ SG_ 1425 SMBdevelpsignalgroupreqFunc_0005 "develop signal group request";
CM_ SG_ 1425 SMBdevelpsignalgroupreqFunc_0006 "develop signal group request";
CM_ SG_ 1426 SMDdevelpsignalgroupreqFunctiond "develop signal group request";
CM_ SG_ 1426 SMDdevelpsignalgroupreqFunc_0000 "develop signal group request";
CM_ SG_ 1426 SMDdevelpsignalgroupreqFunc_0001 "develop signal group request";
CM_ SG_ 1426 SMDdevelpsignalgroupreqFunc_0002 "develop signal group request";
CM_ SG_ 1426 SMDdevelpsignalgroupreqFunc_0003 "develop signal group request";
CM_ SG_ 1426 SMDdevelpsignalgroupreqFunc_0004 "develop signal group request";
CM_ SG_ 1426 SMDdevelpsignalgroupreqFunc_0005 "develop signal group request";
CM_ SG_ 1426 SMDdevelpsignalgroupreqFunc_0006 "develop signal group request";
CM_ SG_ 1427 SMPdevelpsignalgroupreqFunctiond "develop signal group request";
CM_ SG_ 1427 SMPdevelpsignalgroupreqFunc_0000 "develop signal group request";
CM_ SG_ 1427 SMPdevelpsignalgroupreqFunc_0001 "develop signal group request";
CM_ SG_ 1427 SMPdevelpsignalgroupreqFunc_0002 "develop signal group request";
CM_ SG_ 1427 SMPdevelpsignalgroupreqFunc_0003 "develop signal group request";
CM_ SG_ 1427 SMPdevelpsignalgroupreqFunc_0004 "develop signal group request";
CM_ SG_ 1427 SMPdevelpsignalgroupreqFunc_0005 "develop signal group request";
CM_ SG_ 1427 SMPdevelpsignalgroupreqFunc_0006 "develop signal group request";
CM_ SG_ 297 AmbLiSettingInfoBlue "Blue ingredient.";
CM_ SG_ 297 AmbLiSettingInfoGreen "Green ingredient.";
CM_ SG_ 297 AmbLiSettingInfoIntensity "Intensity";
CM_ SG_ 297 AmbLiSettingInfoRed "Red ingredient.";
CM_ SG_ 297 AmbLiSettingInfoSynchDelay "Synchronisation delay";
CM_ SG_ 297 AmbLiSettingInfoTransitionTime "Transition time";
CM_ SG_ 16 DoorPassLatPawlSt "Used to indicate if the passenger door actuator must be triggered based in the pawl switch status AND other conditions from passenger door latch. [Close] Door is fully closed, the Pawl switch has changed value to PSD and timer to reach ajar is out without reaching ajar. [Open] Pawl Switch has not changed status to [PSD] OR latch successfully reach Ajar position within time. [Undefined] Not enough information about Pawl Switch status is found";
CM_ SG_ 16 DoorPassLatPosn "Passenger door Cinch position. x01 equal fully open, x02 equal secondary position, x03 equal fully closed.";
CM_ SG_ 16 DoorPassLockSts "DoorPassLockSts - Passenger Door Lock Status
Lock status
LockStsUkwn - Lock Status Unknown
Unlckd - Unlocked
Lockd - Locked
SafeLockd - Safe Locked (Double Locked)";
CM_ SG_ 16 DoorPassOpenLowReqOutdSwt1 "DooPassOpenLowReqOutdSwt1 - Passenger Door Open Request from Outside Switch 1 - Traditional door (No Power operated). Button status of the outside dpassenger door handle switch connection 1.
Psd - Pressed
NotPsd - Not Pressed
NoInfo1/2 - Invalid";
CM_ SG_ 16 DoorPassOpenReqInsdSwt1 "DoorDrvrOpenReqInsdSwt1 - Passenger Door Open Request from Inside Switch 1
Button status of the inside passenger door handle switch connection 1
Psd - Pressed
NotPsd - Not Pressed
NoInfo1/2 - Invalid";
CM_ SG_ 16 DoorPassRelsFailCinchOverTimed "Cinch processwas not successfull. It is overtimed.";
CM_ SG_ 16 DoorPassRelsFailFailure1 "Issue described by requiremnt according to specific project";
CM_ SG_ 16 DoorPassRelsFailMechRels "Door Mechanical release (No Power operated)";
CM_ SG_ 16 DoorPassSwtIntrLockgReq "DoorPassSwtIntrLockgReq - Passenger Door Interior Locking Switch Request
Central locking or unlocking request from passenger door interior central locking or unlocking switch
Idle - No Request
Unlck - Unlock request
Lock - Lock request";
CM_ SG_ 16 FltOfIndcrTurnOnPassSide "Light source failure (open load or short circuit) indication to driver, side direction indicator passenger side.";
CM_ SG_ 16 LcmaLedStsPassSide "LED status in passenger side rear mirror";
CM_ SG_ 16 MirrAtPassInMovmt "Informs the Setting Management subsystem that the outer rear view mirrors are in movement. Passanger side.";
CM_ SG_ 16 MirrDwnStsAtPass "Reports the status of the mirror dipping mode. Passanger side.";
CM_ SG_ 16 MirrFoldStsAtPass "Reports the fold status of the outer rear view mirrors. Passanger side.";
CM_ SG_ 16 PassMemBtnPsdMemBtn1 "Passenger Memory Button 1";
CM_ SG_ 16 PassMemBtnPsdMemBtn2 "Passenger Memory Button 2";
CM_ SG_ 16 PassMemBtnPsdMemBtn3 "Passenger Memory Button 3";
CM_ SG_ 16 PassMemBtnPsdMemButM "Passenger Memory Button";
CM_ SG_ 16 ShortDropWinPassSts "Short drop a status sent back to locking to secure window is down and door is ready to be released. ";
CM_ SG_ 16 WinPosnStsAtPass "Signal sent to inform the rest of the car of the window position status for the front passenger side door. The value of the signal is either an approximated percentage of openness, of the window is moving or if the position is unkown.
";
CM_ SG_ 293 AmbTRawAtPassSideAmbTVal "Unfiltered ambient temp raw data in deg C";
CM_ SG_ 293 AmbTRawAtPassSideQly "quality";
CM_ SG_ 293 AmbTURawAtPassSide "Ambient temp raw data in deg C at passenger side";
CM_ SG_ 293 DoorPassCinhIntFailInfCinchFlt1 "Cinch fault";
CM_ SG_ 293 DoorPassCinhIntFailInfCinchRestF "Cinch reset fault";
CM_ SG_ 293 DoorPassHndlHMIStsDeployedOverTm "Signal Utilized to communicate to HMI subsystem the following specific events in passenger door
Handle retract over timed On-Off
Handle deploy over timed On-Off
Unsuccessful  Hall sensor reset On-Off";
CM_ SG_ 293 DoorPassHndlHMIStsReserved1 "Signal Utilized to communicate to HMI subsystem the following specific events in passenger door
Handle retract over timed On-Off
Handle deploy over timed On-Off
Unsuccessful  Hall sensor reset On-Off";
CM_ SG_ 293 DoorPassHndlHMIStsRetractOverTmd "Signal Utilized to communicate to HMI subsystem the following specific events in passenger door
Handle retract over timed On-Off
Handle deploy over timed On-Off
Unsuccessful  Hall sensor reset On-Off";
CM_ SG_ 293 DoorPassHndlHMIStsUnsScsHallSnsr "Signal Utilized to communicate to HMI subsystem the following specific events in passenger door
Handle retract over timed On-Off
Handle deploy over timed On-Off
Unsuccessful  Hall sensor reset On-Off";
CM_ SG_ 293 DoorPassHndlSts "To inform about passenger door handle status, i.e. unknown, opened, closed according to
DoorPassHndlSts
- Ukwn
- FullRtrctd
- MovgOut
- StopDurgDply
- FullDplyd
- MovgIn
- StopDurgRtrct
- Flt";
CM_ SG_ 293 MirrDefrstAtPassSts "Status signal exterior rear view mirror electrical defroster passenger side.";
CM_ SG_ 293 MirrPosnFromCldAtPassIntFb "Mirror position feedback to MirrPosnMst.";
CM_ SG_ 293 MirrPosnToCldAtPassMirrPosnAdjCl "Mirror Position send to Cloud Left-Right";
CM_ SG_ 293 MirrPosnToCldAtPassMirrPosn_0000 "Mirror Position send to Cloud Up-Down";
CM_ SG_ 293 WinFailrStsAtPass "Report failure if Window motor is not possible to Run";
CM_ SG_ 565 DoorPassSwpLockBtn "Door Passenger swiping locking status";
CM_ SG_ 1348 VFCVectorPDMBlockID "Block Identifier";
CM_ SG_ 1348 VFCVectorPDMVFCid0 "VFC0";
CM_ SG_ 1348 VFCVectorPDMVFCid1 "VFC1";
CM_ SG_ 1348 VFCVectorPDMVFCid10 "VFC10";
CM_ SG_ 1348 VFCVectorPDMVFCid11 "VFC11";
CM_ SG_ 1348 VFCVectorPDMVFCid12 "VFC12";
CM_ SG_ 1348 VFCVectorPDMVFCid13 "VFC13";
CM_ SG_ 1348 VFCVectorPDMVFCid14 "VFC14";
CM_ SG_ 1348 VFCVectorPDMVFCid15 "VFC15";
CM_ SG_ 1348 VFCVectorPDMVFCid16 "VFC16";
CM_ SG_ 1348 VFCVectorPDMVFCid17 "VFC17";
CM_ SG_ 1348 VFCVectorPDMVFCid18 "VFC18";
CM_ SG_ 1348 VFCVectorPDMVFCid19 "VFC19";
CM_ SG_ 1348 VFCVectorPDMVFCid2 "VFC2";
CM_ SG_ 1348 VFCVectorPDMVFCid20 "VFC20";
CM_ SG_ 1348 VFCVectorPDMVFCid21 "VFC21";
CM_ SG_ 1348 VFCVectorPDMVFCid22 "VFC22";
CM_ SG_ 1348 VFCVectorPDMVFCid23 "VFC23";
CM_ SG_ 1348 VFCVectorPDMVFCid24 "VFC24";
CM_ SG_ 1348 VFCVectorPDMVFCid25 "VFC25";
CM_ SG_ 1348 VFCVectorPDMVFCid26 "VFC26";
CM_ SG_ 1348 VFCVectorPDMVFCid27 "VFC27";
CM_ SG_ 1348 VFCVectorPDMVFCid28 "VFC28";
CM_ SG_ 1348 VFCVectorPDMVFCid29 "VFC29";
CM_ SG_ 1348 VFCVectorPDMVFCid3 "VFC3";
CM_ SG_ 1348 VFCVectorPDMVFCid30 "VFC30";
CM_ SG_ 1348 VFCVectorPDMVFCid31 "VFC31";
CM_ SG_ 1348 VFCVectorPDMVFCid32 "VFC32";
CM_ SG_ 1348 VFCVectorPDMVFCid33 "VFC33";
CM_ SG_ 1348 VFCVectorPDMVFCid34 "VFC34";
CM_ SG_ 1348 VFCVectorPDMVFCid35 "VFC35";
CM_ SG_ 1348 VFCVectorPDMVFCid36 "VFC36";
CM_ SG_ 1348 VFCVectorPDMVFCid37 "VFC37";
CM_ SG_ 1348 VFCVectorPDMVFCid38 "VFC38";
CM_ SG_ 1348 VFCVectorPDMVFCid39 "VFC39";
CM_ SG_ 1348 VFCVectorPDMVFCid4 "VFC4";
CM_ SG_ 1348 VFCVectorPDMVFCid40 "VFC40";
CM_ SG_ 1348 VFCVectorPDMVFCid41 "VFC41";
CM_ SG_ 1348 VFCVectorPDMVFCid42 "VFC42";
CM_ SG_ 1348 VFCVectorPDMVFCid43 "VFC43";
CM_ SG_ 1348 VFCVectorPDMVFCid44 "VFC44";
CM_ SG_ 1348 VFCVectorPDMVFCid45 "VFC45";
CM_ SG_ 1348 VFCVectorPDMVFCid46 "VFC46";
CM_ SG_ 1348 VFCVectorPDMVFCid47 "VFC47";
CM_ SG_ 1348 VFCVectorPDMVFCid48 "VFC48";
CM_ SG_ 1348 VFCVectorPDMVFCid49 "VFC49";
CM_ SG_ 1348 VFCVectorPDMVFCid5 "VFC5";
CM_ SG_ 1348 VFCVectorPDMVFCid50 "VFC50";
CM_ SG_ 1348 VFCVectorPDMVFCid51 "VFC51";
CM_ SG_ 1348 VFCVectorPDMVFCid52 "VFC52";
CM_ SG_ 1348 VFCVectorPDMVFCid53 "VFC53";
CM_ SG_ 1348 VFCVectorPDMVFCid54 "VFC54";
CM_ SG_ 1348 VFCVectorPDMVFCid55 "VFC55";
CM_ SG_ 1348 VFCVectorPDMVFCid56 "VFC56";
CM_ SG_ 1348 VFCVectorPDMVFCid57 "VFC57";
CM_ SG_ 1348 VFCVectorPDMVFCid58 "VFC58";
CM_ SG_ 1348 VFCVectorPDMVFCid59 "VFC59";
CM_ SG_ 1348 VFCVectorPDMVFCid6 "VFC6";
CM_ SG_ 1348 VFCVectorPDMVFCid60 "VFC60";
CM_ SG_ 1348 VFCVectorPDMVFCid61 "VFC61";
CM_ SG_ 1348 VFCVectorPDMVFCid7 "VFC7";
CM_ SG_ 1348 VFCVectorPDMVFCid8 "VFC8";
CM_ SG_ 1348 VFCVectorPDMVFCid9 "VFC9";
CM_ SG_ 416 BodyMissComPrmntFromBoot "BodyMissComPrmntBoot - Permanent missing communication POT";
CM_ SG_ 149 SwtTrClsSts "SwtTrClsSts - Close Tailgate/Bootlid switch status

Status signal for shutface close switch.

Psd - Pressed
NotPsd - Not Pressed";
CM_ SG_ 149 TopPosHmiFeedBackPerc13 "Bootlid position from 0 to 100 with 4 % resolution";
CM_ SG_ 149 TopPosHmiFeedBackUknFl "Bootlid status feedback signal to HMI. The status varies between Unkown or Fail";
CM_ SG_ 149 TrAntiPnch "Contains info if POT motor anti-pinch is activated or not";
CM_ SG_ 149 TrObstclDetn "TrObstclDetn - Trunk Obstacle Detection
Signal if obstacle is detected by trunk while opening.
False - No obstacle detected
True - Obstacle detected";
CM_ SG_ 149 TrOpenerSts "To inform about POT status. moving, opened, closed...";
CM_ SG_ 149 TrRelsFailtoHMI "Used to communicate if there is an error in Tailgate/bootlid latch power operation";
CM_ SG_ 1351 VFCVectorPOTBlockID "BlockID";
CM_ SG_ 1351 VFCVectorPOTVFCid0 "SettingsComfort";
CM_ SG_ 1351 VFCVectorPOTVFCid1 "ParkingDrivingClimatization";
CM_ SG_ 1351 VFCVectorPOTVFCid10 "ExteriorLighting";
CM_ SG_ 1351 VFCVectorPOTVFCid11 "VFCid11";
CM_ SG_ 1351 VFCVectorPOTVFCid12 "Alarm";
CM_ SG_ 1351 VFCVectorPOTVFCid13 "VFCid13";
CM_ SG_ 1351 VFCVectorPOTVFCid14 "InteriorLighting";
CM_ SG_ 1351 VFCVectorPOTVFCid15 "VFCid15";
CM_ SG_ 1351 VFCVectorPOTVFCid16 "Locking";
CM_ SG_ 1351 VFCVectorPOTVFCid17 "RemoteKeyFunctionality";
CM_ SG_ 1351 VFCVectorPOTVFCid18 "PropulsionStart";
CM_ SG_ 1351 VFCVectorPOTVFCid19 "VFCid19";
CM_ SG_ 1351 VFCVectorPOTVFCid2 "PostClimatisation";
CM_ SG_ 1351 VFCVectorPOTVFCid20 "VFCid20";
CM_ SG_ 1351 VFCVectorPOTVFCid21 "PowerClosures";
CM_ SG_ 1351 VFCVectorPOTVFCid22 "VehicleDriving";
CM_ SG_ 1351 VFCVectorPOTVFCid23 "VFCid23";
CM_ SG_ 1351 VFCVectorPOTVFCid24 "SettingsProfile";
CM_ SG_ 1351 VFCVectorPOTVFCid25 "SeatComfortFunctions";
CM_ SG_ 1351 VFCVectorPOTVFCid26 "Brake";
CM_ SG_ 1351 VFCVectorPOTVFCid27 "InfotainmentPoll";
CM_ SG_ 1351 VFCVectorPOTVFCid28 "HVEnergyStorage";
CM_ SG_ 1351 VFCVectorPOTVFCid29 "VFCid29";
CM_ SG_ 1351 VFCVectorPOTVFCid3 "PowertrainParkingClimatization";
CM_ SG_ 1351 VFCVectorPOTVFCid30 "TelematicsConnectivity";
CM_ SG_ 1351 VFCVectorPOTVFCid31 "VFCid31";
CM_ SG_ 1351 VFCVectorPOTVFCid32 "VFCid32";
CM_ SG_ 1351 VFCVectorPOTVFCid33 "Diagnostics";
CM_ SG_ 1351 VFCVectorPOTVFCid34 "VehicleModeManagement";
CM_ SG_ 1351 VFCVectorPOTVFCid35 "TrailerCaravanFunctions";
CM_ SG_ 1351 VFCVectorPOTVFCid36 "Immobilizer";
CM_ SG_ 1351 VFCVectorPOTVFCid37 "Windows";
CM_ SG_ 1351 VFCVectorPOTVFCid38 "Visibility";
CM_ SG_ 1351 VFCVectorPOTVFCid39 "VFCid39";
CM_ SG_ 1351 VFCVectorPOTVFCid4 "VFCid4";
CM_ SG_ 1351 VFCVectorPOTVFCid40 "VFCid40";
CM_ SG_ 1351 VFCVectorPOTVFCid41 "InfotainmentPush";
CM_ SG_ 1351 VFCVectorPOTVFCid42 "ChargingHV";
CM_ SG_ 1351 VFCVectorPOTVFCid43 "BodyPreClimatisation";
CM_ SG_ 1351 VFCVectorPOTVFCid44 "Crash";
CM_ SG_ 1351 VFCVectorPOTVFCid45 "GlobalShortDuration";
CM_ SG_ 1351 VFCVectorPOTVFCid46 "ExteriorLightsHazard";
CM_ SG_ 1351 VFCVectorPOTVFCid47 "VFCid47";
CM_ SG_ 1351 VFCVectorPOTVFCid48 "DoorOpenWarning";
CM_ SG_ 1351 VFCVectorPOTVFCid49 "ChargingLVInit";
CM_ SG_ 1351 VFCVectorPOTVFCid5 "VFCid5";
CM_ SG_ 1351 VFCVectorPOTVFCid50 "VFCid50";
CM_ SG_ 1351 VFCVectorPOTVFCid51 "VFCid51";
CM_ SG_ 1351 VFCVectorPOTVFCid52 "HVBatteryThermalEventWarning";
CM_ SG_ 1351 VFCVectorPOTVFCid53 "VisualAssist";
CM_ SG_ 1351 VFCVectorPOTVFCid54 "VFCid54";
CM_ SG_ 1351 VFCVectorPOTVFCid55 "VFCid55";
CM_ SG_ 1351 VFCVectorPOTVFCid56 "VFCid56";
CM_ SG_ 1351 VFCVectorPOTVFCid57 "VFCid57";
CM_ SG_ 1351 VFCVectorPOTVFCid58 "VFCid58";
CM_ SG_ 1351 VFCVectorPOTVFCid59 "VFCid59";
CM_ SG_ 1351 VFCVectorPOTVFCid6 "SettingsVehicle";
CM_ SG_ 1351 VFCVectorPOTVFCid60 "VFCid60";
CM_ SG_ 1351 VFCVectorPOTVFCid61 "VFCid61";
CM_ SG_ 1351 VFCVectorPOTVFCid7 "VFCid7";
CM_ SG_ 1351 VFCVectorPOTVFCid8 "VFCid8";
CM_ SG_ 1351 VFCVectorPOTVFCid9 "IPWakeup";
BA_DEF_ BO_  "GenMsgSendType" ENUM  "cyclic","spontaneous","not-used","not-used","not-used","cyclicAndSpontaneous","not-used","cyclicIfActive","NoMsgSendType";
BA_DEF_ BO_  "GenMsgCycleTime" INT 0 65536;
BA_DEF_ BO_  "GenMsgStartDelayTime" INT 0 65536;
BA_DEF_ BO_  "GenMsgDelayTime" INT 0 65536;
BA_DEF_ SG_  "GenSigSendType" ENUM  "Cyclic","OnWrite","OnWriteWithRepetition","OnChange","OnChangeWithRepetition","IfActive","IfActiveWithRepetition","NoSigSendType";
BA_DEF_ SG_  "GenSigStartValue" HEX 0 80000000;
BA_DEF_ BO_  "GenMsgILSupport" ENUM  "No","Yes";
BA_DEF_ BO_  "NmAsrMessage" ENUM  "No","Yes";
BA_DEF_ SG_  "GenSigFuncType" ENUM  "NoFunction","n/a","n/a","n/a","n/a","n/a","n/a","n/a","n/a","n/a","n/a","n/a","n/a","n/a","n/a","CHK","CNTR","n/a","n/a","n/a","CNTR_AR_01","CRC_AR_01_BOTH","CRC_AR_01_ALT","CRC_AR_01_LOW","CRC_AR_01_NIBBLE","CNTR_AR_04","CRC_AR_04A","CNTR_AR_05","CRC_AR_05";
BA_DEF_ SG_  "GenSigDataID" STRING ;
BA_DEF_ SG_  "SystemSignalLongSymbol" STRING ;
BA_DEF_DEF_  "GenMsgSendType" "NoMsgSendType";
BA_DEF_DEF_  "GenMsgCycleTime" 0;
BA_DEF_DEF_  "GenMsgStartDelayTime" 0;
BA_DEF_DEF_  "GenMsgDelayTime" 0;
BA_DEF_DEF_  "GenSigSendType" "NoSigSendType";
BA_DEF_DEF_  "GenSigStartValue" 0;
BA_DEF_DEF_  "GenMsgILSupport" "Yes";
BA_DEF_DEF_  "NmAsrMessage" "No";
BA_DEF_DEF_  "GenSigFuncType" "NoFunction";
BA_DEF_DEF_  "GenSigDataID" "";
BA_DEF_DEF_  "SystemSignalLongSymbol" "";
BA_ "GenMsgSendType" BO_ 820 0;
BA_ "GenMsgCycleTime" BO_ 820 200;
BA_ "GenMsgSendType" BO_ 836 0;
BA_ "GenMsgCycleTime" BO_ 836 140;
BA_ "GenMsgSendType" BO_ 840 0;
BA_ "GenMsgCycleTime" BO_ 840 140;
BA_ "GenMsgSendType" BO_ 844 0;
BA_ "GenMsgCycleTime" BO_ 844 140;
BA_ "GenMsgSendType" BO_ 34 0;
BA_ "GenMsgCycleTime" BO_ 34 30;
BA_ "GenMsgSendType" BO_ 827 0;
BA_ "GenMsgCycleTime" BO_ 827 240;
BA_ "GenMsgSendType" BO_ 1281 1;
BA_ "GenMsgDelayTime" BO_ 1281 20;
BA_ "GenMsgILSupport" BO_ 1281 0;
BA_ "NmAsrMessage" BO_ 1281 1;
BA_ "GenMsgSendType" BO_ 2047 1;
BA_ "GenMsgDelayTime" BO_ 2047 5;
BA_ "GenMsgSendType" BO_ 1809 1;
BA_ "GenMsgDelayTime" BO_ 1809 5;
BA_ "GenMsgSendType" BO_ 1810 1;
BA_ "GenMsgDelayTime" BO_ 1810 5;
BA_ "GenMsgSendType" BO_ 1413 1;
BA_ "GenMsgDelayTime" BO_ 1413 5;
BA_ "GenMsgSendType" BO_ 1414 1;
BA_ "GenMsgDelayTime" BO_ 1414 5;
BA_ "GenMsgSendType" BO_ 1415 1;
BA_ "GenMsgDelayTime" BO_ 1415 5;
BA_ "GenMsgSendType" BO_ 1416 1;
BA_ "GenMsgDelayTime" BO_ 1416 5;
BA_ "GenMsgSendType" BO_ 1840 1;
BA_ "GenMsgDelayTime" BO_ 1840 5;
BA_ "GenMsgSendType" BO_ 1816 1;
BA_ "GenMsgDelayTime" BO_ 1816 5;
BA_ "GenMsgSendType" BO_ 1811 1;
BA_ "GenMsgDelayTime" BO_ 1811 5;
BA_ "GenMsgSendType" BO_ 1813 1;
BA_ "GenMsgDelayTime" BO_ 1813 5;
BA_ "GenMsgSendType" BO_ 1817 1;
BA_ "GenMsgDelayTime" BO_ 1817 5;
BA_ "GenMsgSendType" BO_ 1825 1;
BA_ "GenMsgDelayTime" BO_ 1825 5;
BA_ "GenMsgSendType" BO_ 1826 1;
BA_ "GenMsgDelayTime" BO_ 1826 5;
BA_ "GenMsgSendType" BO_ 1827 1;
BA_ "GenMsgDelayTime" BO_ 1827 5;
BA_ "GenMsgSendType" BO_ 1828 1;
BA_ "GenMsgDelayTime" BO_ 1828 5;
BA_ "GenMsgSendType" BO_ 1841 1;
BA_ "GenMsgDelayTime" BO_ 1841 5;
BA_ "GenMsgSendType" BO_ 1842 1;
BA_ "GenMsgDelayTime" BO_ 1842 5;
BA_ "GenMsgSendType" BO_ 1831 1;
BA_ "GenMsgDelayTime" BO_ 1831 5;
BA_ "GenMsgSendType" BO_ 1843 1;
BA_ "GenMsgDelayTime" BO_ 1843 5;
BA_ "GenMsgSendType" BO_ 1832 1;
BA_ "GenMsgDelayTime" BO_ 1832 5;
BA_ "GenMsgSendType" BO_ 1833 1;
BA_ "GenMsgDelayTime" BO_ 1833 5;
BA_ "GenMsgSendType" BO_ 1815 1;
BA_ "GenMsgDelayTime" BO_ 1815 5;
BA_ "GenMsgSendType" BO_ 48 5;
BA_ "GenMsgCycleTime" BO_ 48 70;
BA_ "GenMsgDelayTime" BO_ 48 20;
BA_ "GenMsgSendType" BO_ 480 0;
BA_ "GenMsgCycleTime" BO_ 480 400;
BA_ "GenMsgSendType" BO_ 291 0;
BA_ "GenMsgCycleTime" BO_ 291 100;
BA_ "GenMsgSendType" BO_ 5 0;
BA_ "GenMsgCycleTime" BO_ 5 25;
BA_ "GenMsgSendType" BO_ 192 0;
BA_ "GenMsgCycleTime" BO_ 192 20;
BA_ "GenMsgSendType" BO_ 1021 0;
BA_ "GenMsgCycleTime" BO_ 1021 500;
BA_ "GenMsgSendType" BO_ 1022 0;
BA_ "GenMsgCycleTime" BO_ 1022 500;
BA_ "GenMsgSendType" BO_ 1023 0;
BA_ "GenMsgCycleTime" BO_ 1023 500;
BA_ "GenMsgSendType" BO_ 1283 1;
BA_ "GenMsgDelayTime" BO_ 1283 20;
BA_ "GenMsgILSupport" BO_ 1283 0;
BA_ "NmAsrMessage" BO_ 1283 1;
BA_ "GenMsgSendType" BO_ 1347 1;
BA_ "GenMsgDelayTime" BO_ 1347 495;
BA_ "GenMsgSendType" BO_ 1554 1;
BA_ "GenMsgDelayTime" BO_ 1554 5;
BA_ "GenMsgSendType" BO_ 1417 1;
BA_ "GenMsgDelayTime" BO_ 1417 5;
BA_ "GenMsgSendType" BO_ 1425 1;
BA_ "GenMsgDelayTime" BO_ 1425 95;
BA_ "GenMsgSendType" BO_ 1426 1;
BA_ "GenMsgDelayTime" BO_ 1426 95;
BA_ "GenMsgSendType" BO_ 1427 1;
BA_ "GenMsgDelayTime" BO_ 1427 95;
BA_ "GenMsgSendType" BO_ 1526 1;
BA_ "GenMsgDelayTime" BO_ 1526 5;
BA_ "GenMsgSendType" BO_ 1527 1;
BA_ "GenMsgDelayTime" BO_ 1527 5;
BA_ "GenMsgSendType" BO_ 1528 1;
BA_ "GenMsgDelayTime" BO_ 1528 5;
BA_ "GenMsgSendType" BO_ 1529 1;
BA_ "GenMsgDelayTime" BO_ 1529 5;
BA_ "GenMsgSendType" BO_ 1521 1;
BA_ "GenMsgDelayTime" BO_ 1521 5;
BA_ "GenMsgSendType" BO_ 1522 1;
BA_ "GenMsgDelayTime" BO_ 1522 5;
BA_ "GenMsgSendType" BO_ 1530 1;
BA_ "GenMsgDelayTime" BO_ 1530 5;
BA_ "GenMsgSendType" BO_ 1523 1;
BA_ "GenMsgDelayTime" BO_ 1523 5;
BA_ "GenMsgSendType" BO_ 1467 1;
BA_ "GenMsgDelayTime" BO_ 1467 10;
BA_ "GenMsgSendType" BO_ 1524 1;
BA_ "GenMsgDelayTime" BO_ 1524 5;
BA_ "GenMsgSendType" BO_ 1525 1;
BA_ "GenMsgDelayTime" BO_ 1525 5;
BA_ "GenMsgSendType" BO_ 1465 1;
BA_ "GenMsgDelayTime" BO_ 1465 10;
BA_ "GenMsgSendType" BO_ 297 0;
BA_ "GenMsgCycleTime" BO_ 297 100;
BA_ "GenMsgSendType" BO_ 1301 1;
BA_ "GenMsgDelayTime" BO_ 1301 20;
BA_ "GenMsgILSupport" BO_ 1301 0;
BA_ "NmAsrMessage" BO_ 1301 1;
BA_ "GenMsgSendType" BO_ 1584 1;
BA_ "GenMsgDelayTime" BO_ 1584 5;
BA_ "GenMsgSendType" BO_ 1531 1;
BA_ "GenMsgDelayTime" BO_ 1531 5;
BA_ "GenMsgSendType" BO_ 16 5;
BA_ "GenMsgCycleTime" BO_ 16 20;
BA_ "GenMsgDelayTime" BO_ 16 20;
BA_ "GenMsgSendType" BO_ 293 0;
BA_ "GenMsgCycleTime" BO_ 293 100;
BA_ "GenMsgSendType" BO_ 565 0;
BA_ "GenMsgCycleTime" BO_ 565 100;
BA_ "GenMsgSendType" BO_ 1284 1;
BA_ "GenMsgDelayTime" BO_ 1284 20;
BA_ "GenMsgILSupport" BO_ 1284 0;
BA_ "NmAsrMessage" BO_ 1284 1;
BA_ "GenMsgSendType" BO_ 1348 1;
BA_ "GenMsgDelayTime" BO_ 1348 495;
BA_ "GenMsgSendType" BO_ 1555 1;
BA_ "GenMsgDelayTime" BO_ 1555 5;
BA_ "GenMsgSendType" BO_ 1424 1;
BA_ "GenMsgDelayTime" BO_ 1424 5;
BA_ "GenMsgSendType" BO_ 416 0;
BA_ "GenMsgCycleTime" BO_ 416 300;
BA_ "GenMsgSendType" BO_ 149 0;
BA_ "GenMsgCycleTime" BO_ 149 45;
BA_ "GenMsgSendType" BO_ 1287 1;
BA_ "GenMsgDelayTime" BO_ 1287 20;
BA_ "GenMsgILSupport" BO_ 1287 0;
BA_ "NmAsrMessage" BO_ 1287 1;
BA_ "GenMsgSendType" BO_ 1351 1;
BA_ "GenMsgDelayTime" BO_ 1351 495;
BA_ "GenMsgSendType" BO_ 1557 1;
BA_ "GenMsgDelayTime" BO_ 1557 5;
BA_ "GenMsgSendType" BO_ 1466 1;
BA_ "GenMsgDelayTime" BO_ 1466 10;
BA_ "GenSigSendType" SG_ 820 ExtrLtgStsAFS 0;
BA_ "GenSigSendType" SG_ 820 ExtrLtgStsAHBC 0;
BA_ "GenSigSendType" SG_ 820 ExtrLtgStsAHL 0;
BA_ "GenSigSendType" SG_ 820 ExtrLtgStsAllWL 0;
BA_ "GenSigSendType" SG_ 820 ExtrLtgStsApproach 0;
BA_ "GenSigSendType" SG_ 820 ExtrLtgStsChks 0;
BA_ "GenSigFuncType" SG_ 820 ExtrLtgStsChks 15;
BA_ "GenSigDataID" SG_ 820 ExtrLtgStsChks "0x44C";
BA_ "GenSigSendType" SG_ 820 ExtrLtgStsCntr 0;
BA_ "GenSigFuncType" SG_ 820 ExtrLtgStsCntr 16;
BA_ "GenSigSendType" SG_ 820 ExtrLtgStsCornrgLi 0;
BA_ "GenSigSendType" SG_ 820 ExtrLtgStsDBL 0;
BA_ "GenSigSendType" SG_ 820 ExtrLtgStsDRL 0;
BA_ "GenSigSendType" SG_ 820 ExtrLtgStsFlash 0;
BA_ "GenSigSendType" SG_ 820 ExtrLtgStsFrntFog 0;
BA_ "GenSigSendType" SG_ 820 ExtrLtgStsGoodbye 0;
BA_ "GenSigSendType" SG_ 820 ExtrLtgStsHiBeam 0;
BA_ "GenSigSendType" SG_ 820 ExtrLtgStsHomeSafe 0;
BA_ "GenSigSendType" SG_ 820 ExtrLtgStsHWL 0;
BA_ "GenSigSendType" SG_ 820 ExtrLtgStsLoBeam 0;
BA_ "GenSigSendType" SG_ 820 ExtrLtgStsLtgShow 0;
BA_ "GenSigSendType" SG_ 820 ExtrLtgStsPosLiFrnt 0;
BA_ "GenSigSendType" SG_ 820 ExtrLtgStsPosLiRe 0;
BA_ "GenSigSendType" SG_ 820 ExtrLtgStsReFog 0;
BA_ "GenSigSendType" SG_ 820 ExtrLtgStsReverseLi 0;
BA_ "GenSigSendType" SG_ 820 ExtrLtgStsStopLi 0;
BA_ "GenSigSendType" SG_ 820 ExtrLtgStsTurnIndrLe 0;
BA_ "GenSigSendType" SG_ 820 ExtrLtgStsTurnIndrRi 0;
BA_ "GenSigSendType" SG_ 820 ExtrLtgStsWelcome 0;
BA_ "GenSigSendType" SG_ 836 ADIntrLiCtrlReq 0;
BA_ "GenSigSendType" SG_ 836 AmbientLiEffectStatusBreathingEf 0;
BA_ "SystemSignalLongSymbol" SG_ 836 AmbientLiEffectStatusBreathingEf "AmbientLiEffectStatusBreathingEffectStatus";
BA_ "GenSigSendType" SG_ 836 AmbientLiEffectStatusIdPen 0;
BA_ "GenSigSendType" SG_ 836 AmbientLiEffectStatusTransitionE 0;
BA_ "SystemSignalLongSymbol" SG_ 836 AmbientLiEffectStatusTransitionE "AmbientLiEffectStatusTransitionEffectStatus";
BA_ "GenSigSendType" SG_ 836 AmbLiEnduranceMilgOpenReqIdPen 0;
BA_ "GenSigSendType" SG_ 836 AmbLiEnduranceMilgOpenReqOnOff1 0;
BA_ "GenSigSendType" SG_ 836 CallSts 0;
BA_ "GenSigSendType" SG_ 836 Zone1SettingsBlue 0;
BA_ "GenSigSendType" SG_ 836 Zone1SettingsGreen 0;
BA_ "GenSigSendType" SG_ 836 Zone1SettingsIdPen 0;
BA_ "GenSigSendType" SG_ 836 Zone1SettingsIntensity 0;
BA_ "GenSigSendType" SG_ 836 Zone1SettingsRed 0;
BA_ "GenSigSendType" SG_ 836 Zone1SettingsZoneStatus 0;
BA_ "GenSigSendType" SG_ 840 AmbLiPhoneOpenReqIdPen 0;
BA_ "GenSigSendType" SG_ 840 AmbLiPhoneOpenReqOnOff1 0;
BA_ "GenSigSendType" SG_ 840 FuLvlLoWarn 0;
BA_ "GenSigSendType" SG_ 840 GoodbyeLiOpenReqIdPen 0;
BA_ "GenSigSendType" SG_ 840 GoodbyeLiOpenReqOnOff1 0;
BA_ "GenSigSendType" SG_ 840 WelcomeLiOpenReqIdPen 0;
BA_ "GenSigSendType" SG_ 840 WelcomeLiOpenReqOnOff1 0;
BA_ "GenSigSendType" SG_ 840 Zone2SettingsBlue 0;
BA_ "GenSigSendType" SG_ 840 Zone2SettingsGreen 0;
BA_ "GenSigSendType" SG_ 840 Zone2SettingsIdPen 0;
BA_ "GenSigSendType" SG_ 840 Zone2SettingsIntensity 0;
BA_ "GenSigSendType" SG_ 840 Zone2SettingsRed 0;
BA_ "GenSigSendType" SG_ 840 Zone2SettingsZoneStatus 0;
BA_ "GenSigSendType" SG_ 844 AmbLiAllIdPen 0;
BA_ "GenSigSendType" SG_ 844 AmbLiAllOnOff1 0;
BA_ "GenSigSendType" SG_ 844 DispHvBattLvlOfChrg 0;
BA_ "GenSigStartValue" SG_ 844 WthrInfoFromCnctSrv 127;
BA_ "GenSigSendType" SG_ 844 WthrInfoFromCnctSrv 0;
BA_ "GenSigSendType" SG_ 844 Zone3SettingsBlue 0;
BA_ "GenSigSendType" SG_ 844 Zone3SettingsGreen 0;
BA_ "GenSigSendType" SG_ 844 Zone3SettingsIdPen 0;
BA_ "GenSigSendType" SG_ 844 Zone3SettingsIntensity 0;
BA_ "GenSigSendType" SG_ 844 Zone3SettingsRed 0;
BA_ "GenSigSendType" SG_ 844 Zone3SettingsZoneStatus 0;
BA_ "GenSigSendType" SG_ 34 MusicInfoForMusicShow1DownSampli 0;
BA_ "SystemSignalLongSymbol" SG_ 34 MusicInfoForMusicShow1DownSampli "MusicInfoForMusicShow1DownSamplingAmplitude";
BA_ "GenSigSendType" SG_ 34 MusicInfoForMusicShow1MaxFFT100m 0;
BA_ "SystemSignalLongSymbol" SG_ 34 MusicInfoForMusicShow1MaxFFT100m "MusicInfoForMusicShow1MaxFFT100ms3kAmplitude";
BA_ "GenSigSendType" SG_ 34 MusicInfoForMusicShow1MaxFF_0000 0;
BA_ "SystemSignalLongSymbol" SG_ 34 MusicInfoForMusicShow1MaxFF_0000 "MusicInfoForMusicShow1MaxFFT100ms3kFrequency";
BA_ "GenSigSendType" SG_ 34 MusicInfoForMusicShow1Segment1FF 0;
BA_ "SystemSignalLongSymbol" SG_ 34 MusicInfoForMusicShow1Segment1FF "MusicInfoForMusicShow1Segment1FFTamplitude";
BA_ "GenSigSendType" SG_ 34 MusicInfoForMusicShow1Segment2FF 0;
BA_ "SystemSignalLongSymbol" SG_ 34 MusicInfoForMusicShow1Segment2FF "MusicInfoForMusicShow1Segment2FFTamplitude";
BA_ "GenSigSendType" SG_ 34 MusicInfoForMusicShow1Segment3FF 0;
BA_ "SystemSignalLongSymbol" SG_ 34 MusicInfoForMusicShow1Segment3FF "MusicInfoForMusicShow1Segment3FFTamplitude";
BA_ "GenSigSendType" SG_ 34 MusicInfoForMusicShow1Segment4FF 0;
BA_ "SystemSignalLongSymbol" SG_ 34 MusicInfoForMusicShow1Segment4FF "MusicInfoForMusicShow1Segment4FFTamplitude";
BA_ "GenSigSendType" SG_ 34 MusicInfoForMusicShow1Segment5FF 0;
BA_ "SystemSignalLongSymbol" SG_ 34 MusicInfoForMusicShow1Segment5FF "MusicInfoForMusicShow1Segment5FFTamplitude";
BA_ "GenSigSendType" SG_ 34 MusicInfoForMusicShow1Segment6FF 0;
BA_ "SystemSignalLongSymbol" SG_ 34 MusicInfoForMusicShow1Segment6FF "MusicInfoForMusicShow1Segment6FFTamplitude";
BA_ "GenSigSendType" SG_ 34 MusicInfoForMusicShow1Segment7FF 0;
BA_ "SystemSignalLongSymbol" SG_ 34 MusicInfoForMusicShow1Segment7FF "MusicInfoForMusicShow1Segment7FFTamplitude";
BA_ "GenSigSendType" SG_ 34 MusicInfoForMusicShow1Segment8FF 0;
BA_ "SystemSignalLongSymbol" SG_ 34 MusicInfoForMusicShow1Segment8FF "MusicInfoForMusicShow1Segment8FFTamplitude";
BA_ "GenSigSendType" SG_ 34 MusicInfoForMusicShow1StateFlagA 0;
BA_ "SystemSignalLongSymbol" SG_ 34 MusicInfoForMusicShow1StateFlagA "MusicInfoForMusicShow1StateFlagAudioPlay";
BA_ "GenSigSendType" SG_ 34 MusicInfoForMusicShow1StateFlagN 0;
BA_ "SystemSignalLongSymbol" SG_ 34 MusicInfoForMusicShow1StateFlagN "MusicInfoForMusicShow1StateFlagNewAudio";
BA_ "GenSigSendType" SG_ 34 MusicInfoForMusicShow1TimeFlagAu 0;
BA_ "SystemSignalLongSymbol" SG_ 34 MusicInfoForMusicShow1TimeFlagAu "MusicInfoForMusicShow1TimeFlagAudioPlay";
BA_ "GenSigSendType" SG_ 34 MusicInfoForMusicShow1TimeFlagMe 0;
BA_ "SystemSignalLongSymbol" SG_ 34 MusicInfoForMusicShow1TimeFlagMe "MusicInfoForMusicShow1TimeFlagMessage";
BA_ "GenSigSendType" SG_ 34 SecRowRiCmftSet 0;
BA_ "GenSigSendType" SG_ 827 ClimaCmd 0;
BA_ "GenSigSendType" SG_ 827 ErsCmdByKey 0;
BA_ "GenSigStartValue" SG_ 827 RainfallAmnt 14;
BA_ "GenSigSendType" SG_ 827 RainfallAmnt 0;
BA_ "GenSigStartValue" SG_ 827 TInCooltAtStrtOfClima 40;
BA_ "GenSigSendType" SG_ 827 TInCooltAtStrtOfClima 0;
BA_ "GenSigSendType" SG_ 48 ChdLockLeftCmd 0;
BA_ "GenSigSendType" SG_ 48 ChdLockRightStsToHmi 0;
BA_ "GenSigSendType" SG_ 48 DoorDrvrHndlHMIStsDeployedOverTm 0;
BA_ "SystemSignalLongSymbol" SG_ 48 DoorDrvrHndlHMIStsDeployedOverTm "DoorDrvrHndlHMIStsDeployedOverTmd";
BA_ "GenSigSendType" SG_ 48 DoorDrvrHndlHMIStsReserved1 0;
BA_ "GenSigSendType" SG_ 48 DoorDrvrHndlHMIStsRetractOverTmd 0;
BA_ "GenSigSendType" SG_ 48 DoorDrvrHndlHMIStsUnsScsHallSnsr 0;
BA_ "SystemSignalLongSymbol" SG_ 48 DoorDrvrHndlHMIStsUnsScsHallSnsr "DoorDrvrHndlHMIStsUnsScsHallSnsrRest";
BA_ "GenSigSendType" SG_ 48 DoorDrvrRelsFailCinchOverTimed 0;
BA_ "GenSigSendType" SG_ 48 DoorDrvrRelsFailFailure1 0;
BA_ "GenSigSendType" SG_ 48 DoorDrvrRelsFailMechRels 0;
BA_ "GenSigSendType" SG_ 48 FltOfIndcrTurnOnDrvrSide 0;
BA_ "GenSigSendType" SG_ 48 MemBtnPsdMemBtn1 1;
BA_ "GenSigSendType" SG_ 48 MemBtnPsdMemBtn2 1;
BA_ "GenSigSendType" SG_ 48 MemBtnPsdMemBtn3 1;
BA_ "GenSigSendType" SG_ 48 MemBtnPsdMemButM 1;
BA_ "GenSigSendType" SG_ 48 MirrFoldStsAtDrvr 0;
BA_ "GenSigSendType" SG_ 48 ShortDropWinDrvrSts 0;
BA_ "GenSigSendType" SG_ 48 WinDsblRightCmd 0;
BA_ "GenSigSendType" SG_ 48 WinFailrStsAtDrvr 0;
BA_ "GenSigStartValue" SG_ 480 AmbTRawAtDrvrSideAmbTVal 700;
BA_ "GenSigSendType" SG_ 480 AmbTRawAtDrvrSideAmbTVal 0;
BA_ "GenSigSendType" SG_ 480 AmbTRawAtDrvrSideQly 0;
BA_ "GenSigStartValue" SG_ 480 ChdLockRightFailStsToHmi 2;
BA_ "GenSigSendType" SG_ 480 ChdLockRightFailStsToHmi 0;
BA_ "GenSigSendType" SG_ 480 MirrDefrstAtDrvSts 0;
BA_ "GenSigStartValue" SG_ 291 AmbTURawAtDrvrSide 700;
BA_ "GenSigSendType" SG_ 291 AmbTURawAtDrvrSide 0;
BA_ "GenSigSendType" SG_ 291 DoorDrvrCinhIntFailInfCinchFlt1 0;
BA_ "GenSigSendType" SG_ 291 DoorDrvrCinhIntFailInfCinchRestF 0;
BA_ "SystemSignalLongSymbol" SG_ 291 DoorDrvrCinhIntFailInfCinchRestF "DoorDrvrCinhIntFailInfCinchRestFlt";
BA_ "GenSigSendType" SG_ 291 DoorDrvrHndlSts 0;
BA_ "GenSigSendType" SG_ 291 DoorDrvrSwpLockBtn 0;
BA_ "GenSigSendType" SG_ 291 MirrDwnStsAtDrvr 0;
BA_ "GenSigSendType" SG_ 291 MirrPosnAdjFromCldPassMirrPosnAd 0;
BA_ "SystemSignalLongSymbol" SG_ 291 MirrPosnAdjFromCldPassMirrPosnAd "MirrPosnAdjFromCldPassMirrPosnAdjCldLeRi";
BA_ "GenSigSendType" SG_ 291 MirrPosnAdjFromCldPassMirrP_0000 0;
BA_ "SystemSignalLongSymbol" SG_ 291 MirrPosnAdjFromCldPassMirrP_0000 "MirrPosnAdjFromCldPassMirrPosnAdjCldUpDwn";
BA_ "GenSigSendType" SG_ 291 MirrPosnToCldAtDrvrMirrPosnAdjCl 0;
BA_ "SystemSignalLongSymbol" SG_ 291 MirrPosnToCldAtDrvrMirrPosnAdjCl "MirrPosnToCldAtDrvrMirrPosnAdjCldLeRi";
BA_ "GenSigSendType" SG_ 291 MirrPosnToCldAtDrvrMirrPosn_0000 0;
BA_ "SystemSignalLongSymbol" SG_ 291 MirrPosnToCldAtDrvrMirrPosn_0000 "MirrPosnToCldAtDrvrMirrPosnAdjCldUpDwn";
BA_ "GenSigSendType" SG_ 5 ChdLockRightCmd 0;
BA_ "GenSigStartValue" SG_ 5 ChdPrtnLeftFailStsToHmi 2;
BA_ "GenSigSendType" SG_ 5 ChdPrtnLeftFailStsToHmi 0;
BA_ "GenSigSendType" SG_ 5 ChdPrtnLeftStsToHmi 0;
BA_ "GenSigSendType" SG_ 5 DoorDrvrLatPawlSt 0;
BA_ "GenSigSendType" SG_ 5 DoorDrvrLatPosn 0;
BA_ "GenSigSendType" SG_ 5 DoorDrvrLockSts 0;
BA_ "GenSigStartValue" SG_ 5 DoorDrvrOpenLowReqOutdSwt1 2;
BA_ "GenSigSendType" SG_ 5 DoorDrvrOpenLowReqOutdSwt1 0;
BA_ "GenSigStartValue" SG_ 5 DoorDrvrOpenReqInsdSwt1 2;
BA_ "GenSigSendType" SG_ 5 DoorDrvrOpenReqInsdSwt1 0;
BA_ "GenSigSendType" SG_ 5 DoorDrvrSwtIntrLockgReq 0;
BA_ "GenSigStartValue" SG_ 5 LcmaLedStsDrvrSide 1;
BA_ "GenSigSendType" SG_ 5 LcmaLedStsDrvrSide 0;
BA_ "GenSigSendType" SG_ 5 MirrAtDrvrInMovmt 0;
BA_ "GenSigSendType" SG_ 5 MirrBtnPsdAtDrvr 0;
BA_ "GenSigSendType" SG_ 5 MirrCmdAtPassMirrDwnCmd 0;
BA_ "GenSigSendType" SG_ 5 MirrCmdAtPassMirrFoldCmd 0;
BA_ "GenSigSendType" SG_ 5 MirrCmdAtPassMirrPosAdjCmd 0;
BA_ "GenSigSendType" SG_ 5 MirrPosnDownLdSts 0;
BA_ "GenSigSendType" SG_ 5 MirrPosnFromCldAtDrvrFb 0;
BA_ "GenSigSendType" SG_ 5 MirrPosnFromCldAtPassFb 0;
BA_ "GenSigSendType" SG_ 5 MirrPosnMemSts 0;
BA_ "GenSigSendType" SG_ 5 WinDsblLeftCmd 0;
BA_ "GenSigSendType" SG_ 5 WinPosnStsAtDrvr 0;
BA_ "GenSigSendType" SG_ 192 CenLockMacKeyReq 0;
BA_ "GenSigSendType" SG_ 192 WinSwtReqChks 0;
BA_ "GenSigFuncType" SG_ 192 WinSwtReqChks 15;
BA_ "GenSigDataID" SG_ 192 WinSwtReqChks "0x45E";
BA_ "GenSigSendType" SG_ 192 WinSwtReqCntr 0;
BA_ "GenSigFuncType" SG_ 192 WinSwtReqCntr 16;
BA_ "GenSigSendType" SG_ 192 WinSwtReqFrntLe 0;
BA_ "GenSigSendType" SG_ 192 WinSwtReqFrntRi 0;
BA_ "GenSigSendType" SG_ 192 WinSwtReqReLe 0;
BA_ "GenSigSendType" SG_ 192 WinSwtReqReRi 0;
BA_ "GenSigSendType" SG_ 1021 DDSPartNo10CmplEndSgn1 0;
BA_ "GenSigSendType" SG_ 1021 DDSPartNo10CmplEndSgn2 0;
BA_ "GenSigSendType" SG_ 1021 DDSPartNo10CmplEndSgn3 0;
BA_ "GenSigSendType" SG_ 1021 DDSPartNo10CmplNr1 0;
BA_ "GenSigSendType" SG_ 1021 DDSPartNo10CmplNr2 0;
BA_ "GenSigSendType" SG_ 1021 DDSPartNo10CmplNr3 0;
BA_ "GenSigSendType" SG_ 1021 DDSPartNo10CmplNr4 0;
BA_ "GenSigSendType" SG_ 1021 DDSPartNo10CmplNr5 0;
BA_ "GenSigSendType" SG_ 1022 DDSPartNoCmplEndSgn1 0;
BA_ "GenSigSendType" SG_ 1022 DDSPartNoCmplEndSgn2 0;
BA_ "GenSigSendType" SG_ 1022 DDSPartNoCmplEndSgn3 0;
BA_ "GenSigSendType" SG_ 1022 DDSPartNoCmplNr1 0;
BA_ "GenSigSendType" SG_ 1022 DDSPartNoCmplNr2 0;
BA_ "GenSigSendType" SG_ 1022 DDSPartNoCmplNr3 0;
BA_ "GenSigSendType" SG_ 1022 DDSPartNoCmplNr4 0;
BA_ "GenSigSendType" SG_ 1023 DDSSerNoNr1 0;
BA_ "GenSigSendType" SG_ 1023 DDSSerNoNr2 0;
BA_ "GenSigSendType" SG_ 1023 DDSSerNoNr3 0;
BA_ "GenSigSendType" SG_ 1023 DDSSerNoNr4 0;
BA_ "GenSigSendType" SG_ 1347 VFCVectorDDMBlockID 1;
BA_ "GenSigSendType" SG_ 1347 VFCVectorDDMVFCid0 1;
BA_ "GenSigSendType" SG_ 1347 VFCVectorDDMVFCid1 1;
BA_ "GenSigSendType" SG_ 1347 VFCVectorDDMVFCid10 1;
BA_ "GenSigSendType" SG_ 1347 VFCVectorDDMVFCid11 1;
BA_ "GenSigSendType" SG_ 1347 VFCVectorDDMVFCid12 1;
BA_ "GenSigSendType" SG_ 1347 VFCVectorDDMVFCid13 1;
BA_ "GenSigSendType" SG_ 1347 VFCVectorDDMVFCid14 1;
BA_ "GenSigSendType" SG_ 1347 VFCVectorDDMVFCid15 1;
BA_ "GenSigSendType" SG_ 1347 VFCVectorDDMVFCid16 1;
BA_ "GenSigSendType" SG_ 1347 VFCVectorDDMVFCid17 1;
BA_ "GenSigSendType" SG_ 1347 VFCVectorDDMVFCid18 1;
BA_ "GenSigSendType" SG_ 1347 VFCVectorDDMVFCid19 1;
BA_ "GenSigSendType" SG_ 1347 VFCVectorDDMVFCid2 1;
BA_ "GenSigSendType" SG_ 1347 VFCVectorDDMVFCid20 1;
BA_ "GenSigSendType" SG_ 1347 VFCVectorDDMVFCid21 1;
BA_ "GenSigSendType" SG_ 1347 VFCVectorDDMVFCid22 1;
BA_ "GenSigSendType" SG_ 1347 VFCVectorDDMVFCid23 1;
BA_ "GenSigSendType" SG_ 1347 VFCVectorDDMVFCid24 1;
BA_ "GenSigSendType" SG_ 1347 VFCVectorDDMVFCid25 1;
BA_ "GenSigSendType" SG_ 1347 VFCVectorDDMVFCid26 1;
BA_ "GenSigSendType" SG_ 1347 VFCVectorDDMVFCid27 1;
BA_ "GenSigSendType" SG_ 1347 VFCVectorDDMVFCid28 1;
BA_ "GenSigSendType" SG_ 1347 VFCVectorDDMVFCid29 1;
BA_ "GenSigSendType" SG_ 1347 VFCVectorDDMVFCid3 1;
BA_ "GenSigSendType" SG_ 1347 VFCVectorDDMVFCid30 1;
BA_ "GenSigSendType" SG_ 1347 VFCVectorDDMVFCid31 1;
BA_ "GenSigSendType" SG_ 1347 VFCVectorDDMVFCid32 1;
BA_ "GenSigSendType" SG_ 1347 VFCVectorDDMVFCid33 1;
BA_ "GenSigSendType" SG_ 1347 VFCVectorDDMVFCid34 1;
BA_ "GenSigSendType" SG_ 1347 VFCVectorDDMVFCid35 1;
BA_ "GenSigSendType" SG_ 1347 VFCVectorDDMVFCid36 1;
BA_ "GenSigSendType" SG_ 1347 VFCVectorDDMVFCid37 1;
BA_ "GenSigSendType" SG_ 1347 VFCVectorDDMVFCid38 1;
BA_ "GenSigSendType" SG_ 1347 VFCVectorDDMVFCid39 1;
BA_ "GenSigSendType" SG_ 1347 VFCVectorDDMVFCid4 1;
BA_ "GenSigSendType" SG_ 1347 VFCVectorDDMVFCid40 1;
BA_ "GenSigSendType" SG_ 1347 VFCVectorDDMVFCid41 1;
BA_ "GenSigSendType" SG_ 1347 VFCVectorDDMVFCid42 1;
BA_ "GenSigSendType" SG_ 1347 VFCVectorDDMVFCid43 1;
BA_ "GenSigSendType" SG_ 1347 VFCVectorDDMVFCid44 1;
BA_ "GenSigSendType" SG_ 1347 VFCVectorDDMVFCid45 1;
BA_ "GenSigSendType" SG_ 1347 VFCVectorDDMVFCid46 1;
BA_ "GenSigSendType" SG_ 1347 VFCVectorDDMVFCid47 1;
BA_ "GenSigSendType" SG_ 1347 VFCVectorDDMVFCid48 1;
BA_ "GenSigSendType" SG_ 1347 VFCVectorDDMVFCid49 1;
BA_ "GenSigSendType" SG_ 1347 VFCVectorDDMVFCid5 1;
BA_ "GenSigSendType" SG_ 1347 VFCVectorDDMVFCid50 1;
BA_ "GenSigSendType" SG_ 1347 VFCVectorDDMVFCid51 1;
BA_ "GenSigSendType" SG_ 1347 VFCVectorDDMVFCid52 1;
BA_ "GenSigSendType" SG_ 1347 VFCVectorDDMVFCid53 1;
BA_ "GenSigSendType" SG_ 1347 VFCVectorDDMVFCid54 1;
BA_ "GenSigSendType" SG_ 1347 VFCVectorDDMVFCid55 1;
BA_ "GenSigSendType" SG_ 1347 VFCVectorDDMVFCid56 1;
BA_ "GenSigSendType" SG_ 1347 VFCVectorDDMVFCid57 1;
BA_ "GenSigSendType" SG_ 1347 VFCVectorDDMVFCid58 1;
BA_ "GenSigSendType" SG_ 1347 VFCVectorDDMVFCid59 1;
BA_ "GenSigSendType" SG_ 1347 VFCVectorDDMVFCid6 1;
BA_ "GenSigSendType" SG_ 1347 VFCVectorDDMVFCid60 1;
BA_ "GenSigSendType" SG_ 1347 VFCVectorDDMVFCid61 1;
BA_ "GenSigSendType" SG_ 1347 VFCVectorDDMVFCid7 1;
BA_ "GenSigSendType" SG_ 1347 VFCVectorDDMVFCid8 1;
BA_ "GenSigSendType" SG_ 1347 VFCVectorDDMVFCid9 1;
BA_ "GenSigSendType" SG_ 1425 SMBdevelpsignalgroupreqFunctiond 1;
BA_ "SystemSignalLongSymbol" SG_ 1425 SMBdevelpsignalgroupreqFunctiond "SMBdevelpsignalgroupreqFunctiondevpsignalgroup1";
BA_ "GenSigSendType" SG_ 1425 SMBdevelpsignalgroupreqFunc_0000 1;
BA_ "SystemSignalLongSymbol" SG_ 1425 SMBdevelpsignalgroupreqFunc_0000 "SMBdevelpsignalgroupreqFunctiondevpsignalgroup2";
BA_ "GenSigSendType" SG_ 1425 SMBdevelpsignalgroupreqFunc_0001 1;
BA_ "SystemSignalLongSymbol" SG_ 1425 SMBdevelpsignalgroupreqFunc_0001 "SMBdevelpsignalgroupreqFunctiondevpsignalgroup3";
BA_ "GenSigSendType" SG_ 1425 SMBdevelpsignalgroupreqFunc_0002 1;
BA_ "SystemSignalLongSymbol" SG_ 1425 SMBdevelpsignalgroupreqFunc_0002 "SMBdevelpsignalgroupreqFunctiondevpsignalgroup4";
BA_ "GenSigSendType" SG_ 1425 SMBdevelpsignalgroupreqFunc_0003 1;
BA_ "SystemSignalLongSymbol" SG_ 1425 SMBdevelpsignalgroupreqFunc_0003 "SMBdevelpsignalgroupreqFunctiondevpsignalgroup5";
BA_ "GenSigSendType" SG_ 1425 SMBdevelpsignalgroupreqFunc_0004 1;
BA_ "SystemSignalLongSymbol" SG_ 1425 SMBdevelpsignalgroupreqFunc_0004 "SMBdevelpsignalgroupreqFunctiondevpsignalgroup6";
BA_ "GenSigSendType" SG_ 1425 SMBdevelpsignalgroupreqFunc_0005 1;
BA_ "SystemSignalLongSymbol" SG_ 1425 SMBdevelpsignalgroupreqFunc_0005 "SMBdevelpsignalgroupreqFunctiondevpsignalgroup7";
BA_ "GenSigSendType" SG_ 1425 SMBdevelpsignalgroupreqFunc_0006 1;
BA_ "SystemSignalLongSymbol" SG_ 1425 SMBdevelpsignalgroupreqFunc_0006 "SMBdevelpsignalgroupreqFunctiondevpsignalgroup8";
BA_ "GenSigSendType" SG_ 1426 SMDdevelpsignalgroupreqFunctiond 1;
BA_ "SystemSignalLongSymbol" SG_ 1426 SMDdevelpsignalgroupreqFunctiond "SMDdevelpsignalgroupreqFunctiondevpsignalgroup1";
BA_ "GenSigSendType" SG_ 1426 SMDdevelpsignalgroupreqFunc_0000 1;
BA_ "SystemSignalLongSymbol" SG_ 1426 SMDdevelpsignalgroupreqFunc_0000 "SMDdevelpsignalgroupreqFunctiondevpsignalgroup2";
BA_ "GenSigSendType" SG_ 1426 SMDdevelpsignalgroupreqFunc_0001 1;
BA_ "SystemSignalLongSymbol" SG_ 1426 SMDdevelpsignalgroupreqFunc_0001 "SMDdevelpsignalgroupreqFunctiondevpsignalgroup3";
BA_ "GenSigSendType" SG_ 1426 SMDdevelpsignalgroupreqFunc_0002 1;
BA_ "SystemSignalLongSymbol" SG_ 1426 SMDdevelpsignalgroupreqFunc_0002 "SMDdevelpsignalgroupreqFunctiondevpsignalgroup4";
BA_ "GenSigSendType" SG_ 1426 SMDdevelpsignalgroupreqFunc_0003 1;
BA_ "SystemSignalLongSymbol" SG_ 1426 SMDdevelpsignalgroupreqFunc_0003 "SMDdevelpsignalgroupreqFunctiondevpsignalgroup5";
BA_ "GenSigSendType" SG_ 1426 SMDdevelpsignalgroupreqFunc_0004 1;
BA_ "SystemSignalLongSymbol" SG_ 1426 SMDdevelpsignalgroupreqFunc_0004 "SMDdevelpsignalgroupreqFunctiondevpsignalgroup6";
BA_ "GenSigSendType" SG_ 1426 SMDdevelpsignalgroupreqFunc_0005 1;
BA_ "SystemSignalLongSymbol" SG_ 1426 SMDdevelpsignalgroupreqFunc_0005 "SMDdevelpsignalgroupreqFunctiondevpsignalgroup7";
BA_ "GenSigSendType" SG_ 1426 SMDdevelpsignalgroupreqFunc_0006 1;
BA_ "SystemSignalLongSymbol" SG_ 1426 SMDdevelpsignalgroupreqFunc_0006 "SMDdevelpsignalgroupreqFunctiondevpsignalgroup8";
BA_ "GenSigSendType" SG_ 1427 SMPdevelpsignalgroupreqFunctiond 1;
BA_ "SystemSignalLongSymbol" SG_ 1427 SMPdevelpsignalgroupreqFunctiond "SMPdevelpsignalgroupreqFunctiondevpsignalgroup1";
BA_ "GenSigSendType" SG_ 1427 SMPdevelpsignalgroupreqFunc_0000 1;
BA_ "SystemSignalLongSymbol" SG_ 1427 SMPdevelpsignalgroupreqFunc_0000 "SMPdevelpsignalgroupreqFunctiondevpsignalgroup2";
BA_ "GenSigSendType" SG_ 1427 SMPdevelpsignalgroupreqFunc_0001 1;
BA_ "SystemSignalLongSymbol" SG_ 1427 SMPdevelpsignalgroupreqFunc_0001 "SMPdevelpsignalgroupreqFunctiondevpsignalgroup3";
BA_ "GenSigSendType" SG_ 1427 SMPdevelpsignalgroupreqFunc_0002 1;
BA_ "SystemSignalLongSymbol" SG_ 1427 SMPdevelpsignalgroupreqFunc_0002 "SMPdevelpsignalgroupreqFunctiondevpsignalgroup4";
BA_ "GenSigSendType" SG_ 1427 SMPdevelpsignalgroupreqFunc_0003 1;
BA_ "SystemSignalLongSymbol" SG_ 1427 SMPdevelpsignalgroupreqFunc_0003 "SMPdevelpsignalgroupreqFunctiondevpsignalgroup5";
BA_ "GenSigSendType" SG_ 1427 SMPdevelpsignalgroupreqFunc_0004 1;
BA_ "SystemSignalLongSymbol" SG_ 1427 SMPdevelpsignalgroupreqFunc_0004 "SMPdevelpsignalgroupreqFunctiondevpsignalgroup6";
BA_ "GenSigSendType" SG_ 1427 SMPdevelpsignalgroupreqFunc_0005 1;
BA_ "SystemSignalLongSymbol" SG_ 1427 SMPdevelpsignalgroupreqFunc_0005 "SMPdevelpsignalgroupreqFunctiondevpsignalgroup7";
BA_ "GenSigSendType" SG_ 1427 SMPdevelpsignalgroupreqFunc_0006 1;
BA_ "SystemSignalLongSymbol" SG_ 1427 SMPdevelpsignalgroupreqFunc_0006 "SMPdevelpsignalgroupreqFunctiondevpsignalgroup8";
BA_ "GenSigSendType" SG_ 297 AmbLiSettingInfoBlue 0;
BA_ "GenSigSendType" SG_ 297 AmbLiSettingInfoGreen 0;
BA_ "GenSigSendType" SG_ 297 AmbLiSettingInfoIntensity 0;
BA_ "GenSigSendType" SG_ 297 AmbLiSettingInfoRed 0;
BA_ "GenSigSendType" SG_ 297 AmbLiSettingInfoSynchDelay 0;
BA_ "GenSigSendType" SG_ 297 AmbLiSettingInfoTransitionTime 0;
BA_ "GenSigSendType" SG_ 16 DoorPassLatPawlSt 0;
BA_ "GenSigSendType" SG_ 16 DoorPassLatPosn 0;
BA_ "GenSigSendType" SG_ 16 DoorPassLockSts 0;
BA_ "GenSigStartValue" SG_ 16 DoorPassOpenLowReqOutdSwt1 2;
BA_ "GenSigSendType" SG_ 16 DoorPassOpenLowReqOutdSwt1 0;
BA_ "GenSigStartValue" SG_ 16 DoorPassOpenReqInsdSwt1 2;
BA_ "GenSigSendType" SG_ 16 DoorPassOpenReqInsdSwt1 0;
BA_ "GenSigSendType" SG_ 16 DoorPassRelsFailCinchOverTimed 0;
BA_ "GenSigSendType" SG_ 16 DoorPassRelsFailFailure1 0;
BA_ "GenSigSendType" SG_ 16 DoorPassRelsFailMechRels 0;
BA_ "GenSigSendType" SG_ 16 DoorPassSwtIntrLockgReq 0;
BA_ "GenSigSendType" SG_ 16 FltOfIndcrTurnOnPassSide 0;
BA_ "GenSigStartValue" SG_ 16 LcmaLedStsPassSide 1;
BA_ "GenSigSendType" SG_ 16 LcmaLedStsPassSide 0;
BA_ "GenSigSendType" SG_ 16 MirrAtPassInMovmt 0;
BA_ "GenSigSendType" SG_ 16 MirrDwnStsAtPass 0;
BA_ "GenSigSendType" SG_ 16 MirrFoldStsAtPass 0;
BA_ "GenSigSendType" SG_ 16 PassMemBtnPsdMemBtn1 1;
BA_ "GenSigSendType" SG_ 16 PassMemBtnPsdMemBtn2 1;
BA_ "GenSigSendType" SG_ 16 PassMemBtnPsdMemBtn3 1;
BA_ "GenSigSendType" SG_ 16 PassMemBtnPsdMemButM 1;
BA_ "GenSigSendType" SG_ 16 ShortDropWinPassSts 0;
BA_ "GenSigSendType" SG_ 16 WinPosnStsAtPass 0;
BA_ "GenSigStartValue" SG_ 293 AmbTRawAtPassSideAmbTVal 700;
BA_ "GenSigSendType" SG_ 293 AmbTRawAtPassSideAmbTVal 0;
BA_ "GenSigSendType" SG_ 293 AmbTRawAtPassSideQly 0;
BA_ "GenSigStartValue" SG_ 293 AmbTURawAtPassSide 700;
BA_ "GenSigSendType" SG_ 293 AmbTURawAtPassSide 0;
BA_ "GenSigSendType" SG_ 293 DoorPassCinhIntFailInfCinchFlt1 0;
BA_ "GenSigSendType" SG_ 293 DoorPassCinhIntFailInfCinchRestF 0;
BA_ "SystemSignalLongSymbol" SG_ 293 DoorPassCinhIntFailInfCinchRestF "DoorPassCinhIntFailInfCinchRestFlt";
BA_ "GenSigSendType" SG_ 293 DoorPassHndlHMIStsDeployedOverTm 0;
BA_ "SystemSignalLongSymbol" SG_ 293 DoorPassHndlHMIStsDeployedOverTm "DoorPassHndlHMIStsDeployedOverTmd";
BA_ "GenSigSendType" SG_ 293 DoorPassHndlHMIStsReserved1 0;
BA_ "GenSigSendType" SG_ 293 DoorPassHndlHMIStsRetractOverTmd 0;
BA_ "GenSigSendType" SG_ 293 DoorPassHndlHMIStsUnsScsHallSnsr 0;
BA_ "SystemSignalLongSymbol" SG_ 293 DoorPassHndlHMIStsUnsScsHallSnsr "DoorPassHndlHMIStsUnsScsHallSnsrRest";
BA_ "GenSigSendType" SG_ 293 DoorPassHndlSts 0;
BA_ "GenSigSendType" SG_ 293 MirrDefrstAtPassSts 0;
BA_ "GenSigSendType" SG_ 293 MirrPosnFromCldAtPassIntFb 0;
BA_ "GenSigSendType" SG_ 293 MirrPosnToCldAtPassMirrPosnAdjCl 0;
BA_ "SystemSignalLongSymbol" SG_ 293 MirrPosnToCldAtPassMirrPosnAdjCl "MirrPosnToCldAtPassMirrPosnAdjCldLeRi";
BA_ "GenSigSendType" SG_ 293 MirrPosnToCldAtPassMirrPosn_0000 0;
BA_ "SystemSignalLongSymbol" SG_ 293 MirrPosnToCldAtPassMirrPosn_0000 "MirrPosnToCldAtPassMirrPosnAdjCldUpDwn";
BA_ "GenSigSendType" SG_ 293 WinFailrStsAtPass 0;
BA_ "GenSigSendType" SG_ 565 DoorPassSwpLockBtn 0;
BA_ "GenSigSendType" SG_ 1348 VFCVectorPDMBlockID 1;
BA_ "GenSigSendType" SG_ 1348 VFCVectorPDMVFCid0 1;
BA_ "GenSigSendType" SG_ 1348 VFCVectorPDMVFCid1 1;
BA_ "GenSigSendType" SG_ 1348 VFCVectorPDMVFCid10 1;
BA_ "GenSigSendType" SG_ 1348 VFCVectorPDMVFCid11 1;
BA_ "GenSigSendType" SG_ 1348 VFCVectorPDMVFCid12 1;
BA_ "GenSigSendType" SG_ 1348 VFCVectorPDMVFCid13 1;
BA_ "GenSigSendType" SG_ 1348 VFCVectorPDMVFCid14 1;
BA_ "GenSigSendType" SG_ 1348 VFCVectorPDMVFCid15 1;
BA_ "GenSigSendType" SG_ 1348 VFCVectorPDMVFCid16 1;
BA_ "GenSigSendType" SG_ 1348 VFCVectorPDMVFCid17 1;
BA_ "GenSigSendType" SG_ 1348 VFCVectorPDMVFCid18 1;
BA_ "GenSigSendType" SG_ 1348 VFCVectorPDMVFCid19 1;
BA_ "GenSigSendType" SG_ 1348 VFCVectorPDMVFCid2 1;
BA_ "GenSigSendType" SG_ 1348 VFCVectorPDMVFCid20 1;
BA_ "GenSigSendType" SG_ 1348 VFCVectorPDMVFCid21 1;
BA_ "GenSigSendType" SG_ 1348 VFCVectorPDMVFCid22 1;
BA_ "GenSigSendType" SG_ 1348 VFCVectorPDMVFCid23 1;
BA_ "GenSigSendType" SG_ 1348 VFCVectorPDMVFCid24 1;
BA_ "GenSigSendType" SG_ 1348 VFCVectorPDMVFCid25 1;
BA_ "GenSigSendType" SG_ 1348 VFCVectorPDMVFCid26 1;
BA_ "GenSigSendType" SG_ 1348 VFCVectorPDMVFCid27 1;
BA_ "GenSigSendType" SG_ 1348 VFCVectorPDMVFCid28 1;
BA_ "GenSigSendType" SG_ 1348 VFCVectorPDMVFCid29 1;
BA_ "GenSigSendType" SG_ 1348 VFCVectorPDMVFCid3 1;
BA_ "GenSigSendType" SG_ 1348 VFCVectorPDMVFCid30 1;
BA_ "GenSigSendType" SG_ 1348 VFCVectorPDMVFCid31 1;
BA_ "GenSigSendType" SG_ 1348 VFCVectorPDMVFCid32 1;
BA_ "GenSigSendType" SG_ 1348 VFCVectorPDMVFCid33 1;
BA_ "GenSigSendType" SG_ 1348 VFCVectorPDMVFCid34 1;
BA_ "GenSigSendType" SG_ 1348 VFCVectorPDMVFCid35 1;
BA_ "GenSigSendType" SG_ 1348 VFCVectorPDMVFCid36 1;
BA_ "GenSigSendType" SG_ 1348 VFCVectorPDMVFCid37 1;
BA_ "GenSigSendType" SG_ 1348 VFCVectorPDMVFCid38 1;
BA_ "GenSigSendType" SG_ 1348 VFCVectorPDMVFCid39 1;
BA_ "GenSigSendType" SG_ 1348 VFCVectorPDMVFCid4 1;
BA_ "GenSigSendType" SG_ 1348 VFCVectorPDMVFCid40 1;
BA_ "GenSigSendType" SG_ 1348 VFCVectorPDMVFCid41 1;
BA_ "GenSigSendType" SG_ 1348 VFCVectorPDMVFCid42 1;
BA_ "GenSigSendType" SG_ 1348 VFCVectorPDMVFCid43 1;
BA_ "GenSigSendType" SG_ 1348 VFCVectorPDMVFCid44 1;
BA_ "GenSigSendType" SG_ 1348 VFCVectorPDMVFCid45 1;
BA_ "GenSigSendType" SG_ 1348 VFCVectorPDMVFCid46 1;
BA_ "GenSigSendType" SG_ 1348 VFCVectorPDMVFCid47 1;
BA_ "GenSigSendType" SG_ 1348 VFCVectorPDMVFCid48 1;
BA_ "GenSigSendType" SG_ 1348 VFCVectorPDMVFCid49 1;
BA_ "GenSigSendType" SG_ 1348 VFCVectorPDMVFCid5 1;
BA_ "GenSigSendType" SG_ 1348 VFCVectorPDMVFCid50 1;
BA_ "GenSigSendType" SG_ 1348 VFCVectorPDMVFCid51 1;
BA_ "GenSigSendType" SG_ 1348 VFCVectorPDMVFCid52 1;
BA_ "GenSigSendType" SG_ 1348 VFCVectorPDMVFCid53 1;
BA_ "GenSigSendType" SG_ 1348 VFCVectorPDMVFCid54 1;
BA_ "GenSigSendType" SG_ 1348 VFCVectorPDMVFCid55 1;
BA_ "GenSigSendType" SG_ 1348 VFCVectorPDMVFCid56 1;
BA_ "GenSigSendType" SG_ 1348 VFCVectorPDMVFCid57 1;
BA_ "GenSigSendType" SG_ 1348 VFCVectorPDMVFCid58 1;
BA_ "GenSigSendType" SG_ 1348 VFCVectorPDMVFCid59 1;
BA_ "GenSigSendType" SG_ 1348 VFCVectorPDMVFCid6 1;
BA_ "GenSigSendType" SG_ 1348 VFCVectorPDMVFCid60 1;
BA_ "GenSigSendType" SG_ 1348 VFCVectorPDMVFCid61 1;
BA_ "GenSigSendType" SG_ 1348 VFCVectorPDMVFCid7 1;
BA_ "GenSigSendType" SG_ 1348 VFCVectorPDMVFCid8 1;
BA_ "GenSigSendType" SG_ 1348 VFCVectorPDMVFCid9 1;
BA_ "GenSigSendType" SG_ 416 BodyMissComPrmntFromBoot 0;
BA_ "GenSigSendType" SG_ 149 SwtTrClsSts 0;
BA_ "GenSigSendType" SG_ 149 TopPosHmiFeedBackPerc13 0;
BA_ "GenSigSendType" SG_ 149 TopPosHmiFeedBackUknFl 0;
BA_ "GenSigSendType" SG_ 149 TrAntiPnch 0;
BA_ "GenSigSendType" SG_ 149 TrObstclDetn 0;
BA_ "GenSigSendType" SG_ 149 TrOpenerSts 0;
BA_ "GenSigSendType" SG_ 149 TrRelsFailtoHMI 0;
BA_ "GenSigSendType" SG_ 1351 VFCVectorPOTBlockID 1;
BA_ "GenSigSendType" SG_ 1351 VFCVectorPOTVFCid0 1;
BA_ "GenSigSendType" SG_ 1351 VFCVectorPOTVFCid1 1;
BA_ "GenSigSendType" SG_ 1351 VFCVectorPOTVFCid10 1;
BA_ "GenSigSendType" SG_ 1351 VFCVectorPOTVFCid11 1;
BA_ "GenSigSendType" SG_ 1351 VFCVectorPOTVFCid12 1;
BA_ "GenSigSendType" SG_ 1351 VFCVectorPOTVFCid13 1;
BA_ "GenSigSendType" SG_ 1351 VFCVectorPOTVFCid14 1;
BA_ "GenSigSendType" SG_ 1351 VFCVectorPOTVFCid15 1;
BA_ "GenSigSendType" SG_ 1351 VFCVectorPOTVFCid16 1;
BA_ "GenSigSendType" SG_ 1351 VFCVectorPOTVFCid17 1;
BA_ "GenSigSendType" SG_ 1351 VFCVectorPOTVFCid18 1;
BA_ "GenSigSendType" SG_ 1351 VFCVectorPOTVFCid19 1;
BA_ "GenSigSendType" SG_ 1351 VFCVectorPOTVFCid2 1;
BA_ "GenSigSendType" SG_ 1351 VFCVectorPOTVFCid20 1;
BA_ "GenSigSendType" SG_ 1351 VFCVectorPOTVFCid21 1;
BA_ "GenSigSendType" SG_ 1351 VFCVectorPOTVFCid22 1;
BA_ "GenSigSendType" SG_ 1351 VFCVectorPOTVFCid23 1;
BA_ "GenSigSendType" SG_ 1351 VFCVectorPOTVFCid24 1;
BA_ "GenSigSendType" SG_ 1351 VFCVectorPOTVFCid25 1;
BA_ "GenSigSendType" SG_ 1351 VFCVectorPOTVFCid26 1;
BA_ "GenSigSendType" SG_ 1351 VFCVectorPOTVFCid27 1;
BA_ "GenSigSendType" SG_ 1351 VFCVectorPOTVFCid28 1;
BA_ "GenSigSendType" SG_ 1351 VFCVectorPOTVFCid29 1;
BA_ "GenSigSendType" SG_ 1351 VFCVectorPOTVFCid3 1;
BA_ "GenSigSendType" SG_ 1351 VFCVectorPOTVFCid30 1;
BA_ "GenSigSendType" SG_ 1351 VFCVectorPOTVFCid31 1;
BA_ "GenSigSendType" SG_ 1351 VFCVectorPOTVFCid32 1;
BA_ "GenSigSendType" SG_ 1351 VFCVectorPOTVFCid33 1;
BA_ "GenSigSendType" SG_ 1351 VFCVectorPOTVFCid34 1;
BA_ "GenSigSendType" SG_ 1351 VFCVectorPOTVFCid35 1;
BA_ "GenSigSendType" SG_ 1351 VFCVectorPOTVFCid36 1;
BA_ "GenSigSendType" SG_ 1351 VFCVectorPOTVFCid37 1;
BA_ "GenSigSendType" SG_ 1351 VFCVectorPOTVFCid38 1;
BA_ "GenSigSendType" SG_ 1351 VFCVectorPOTVFCid39 1;
BA_ "GenSigSendType" SG_ 1351 VFCVectorPOTVFCid4 1;
BA_ "GenSigSendType" SG_ 1351 VFCVectorPOTVFCid40 1;
BA_ "GenSigSendType" SG_ 1351 VFCVectorPOTVFCid41 1;
BA_ "GenSigSendType" SG_ 1351 VFCVectorPOTVFCid42 1;
BA_ "GenSigSendType" SG_ 1351 VFCVectorPOTVFCid43 1;
BA_ "GenSigSendType" SG_ 1351 VFCVectorPOTVFCid44 1;
BA_ "GenSigSendType" SG_ 1351 VFCVectorPOTVFCid45 1;
BA_ "GenSigSendType" SG_ 1351 VFCVectorPOTVFCid46 1;
BA_ "GenSigSendType" SG_ 1351 VFCVectorPOTVFCid47 1;
BA_ "GenSigSendType" SG_ 1351 VFCVectorPOTVFCid48 1;
BA_ "GenSigSendType" SG_ 1351 VFCVectorPOTVFCid49 1;
BA_ "GenSigSendType" SG_ 1351 VFCVectorPOTVFCid5 1;
BA_ "GenSigSendType" SG_ 1351 VFCVectorPOTVFCid50 1;
BA_ "GenSigSendType" SG_ 1351 VFCVectorPOTVFCid51 1;
BA_ "GenSigSendType" SG_ 1351 VFCVectorPOTVFCid52 1;
BA_ "GenSigSendType" SG_ 1351 VFCVectorPOTVFCid53 1;
BA_ "GenSigSendType" SG_ 1351 VFCVectorPOTVFCid54 1;
BA_ "GenSigSendType" SG_ 1351 VFCVectorPOTVFCid55 1;
BA_ "GenSigSendType" SG_ 1351 VFCVectorPOTVFCid56 1;
BA_ "GenSigSendType" SG_ 1351 VFCVectorPOTVFCid57 1;
BA_ "GenSigSendType" SG_ 1351 VFCVectorPOTVFCid58 1;
BA_ "GenSigSendType" SG_ 1351 VFCVectorPOTVFCid59 1;
BA_ "GenSigSendType" SG_ 1351 VFCVectorPOTVFCid6 1;
BA_ "GenSigSendType" SG_ 1351 VFCVectorPOTVFCid60 1;
BA_ "GenSigSendType" SG_ 1351 VFCVectorPOTVFCid61 1;
BA_ "GenSigSendType" SG_ 1351 VFCVectorPOTVFCid7 1;
BA_ "GenSigSendType" SG_ 1351 VFCVectorPOTVFCid8 1;
BA_ "GenSigSendType" SG_ 1351 VFCVectorPOTVFCid9 1;
VAL_ 820 ExtrLtgStsAFS 0 "DevSts4_Off" 1 "DevSts4_On" 2 "DevSts4_Err" 3 "DevSts4_Resd" ;
VAL_ 820 ExtrLtgStsAHBC 0 "DevSts4_Off" 1 "DevSts4_On" 2 "DevSts4_Err" 3 "DevSts4_Resd" ;
VAL_ 820 ExtrLtgStsAHL 0 "DevSts4_Off" 1 "DevSts4_On" 2 "DevSts4_Err" 3 "DevSts4_Resd" ;
VAL_ 820 ExtrLtgStsAllWL 0 "DevSts4_Off" 1 "DevSts4_On" 2 "DevSts4_Err" 3 "DevSts4_Resd" ;
VAL_ 820 ExtrLtgStsApproach 0 "DevSts4_Off" 1 "DevSts4_On" 2 "DevSts4_Err" 3 "DevSts4_Resd" ;
VAL_ 820 ExtrLtgStsCornrgLi 0 "DevSts4_Off" 1 "DevSts4_On" 2 "DevSts4_Err" 3 "DevSts4_Resd" ;
VAL_ 820 ExtrLtgStsDBL 0 "DevSts4_Off" 1 "DevSts4_On" 2 "DevSts4_Err" 3 "DevSts4_Resd" ;
VAL_ 820 ExtrLtgStsDRL 0 "DevSts4_Off" 1 "DevSts4_On" 2 "DevSts4_Err" 3 "DevSts4_Resd" ;
VAL_ 820 ExtrLtgStsFlash 0 "DevSts4_Off" 1 "DevSts4_On" 2 "DevSts4_Err" 3 "DevSts4_Resd" ;
VAL_ 820 ExtrLtgStsFrntFog 0 "DevSts4_Off" 1 "DevSts4_On" 2 "DevSts4_Err" 3 "DevSts4_Resd" ;
VAL_ 820 ExtrLtgStsGoodbye 0 "DevSts4_Off" 1 "DevSts4_On" 2 "DevSts4_Err" 3 "DevSts4_Resd" ;
VAL_ 820 ExtrLtgStsHiBeam 0 "DevSts4_Off" 1 "DevSts4_On" 2 "DevSts4_Err" 3 "DevSts4_Resd" ;
VAL_ 820 ExtrLtgStsHomeSafe 0 "DevSts4_Off" 1 "DevSts4_On" 2 "DevSts4_Err" 3 "DevSts4_Resd" ;
VAL_ 820 ExtrLtgStsHWL 0 "DevSts4_Off" 1 "DevSts4_On" 2 "DevSts4_Err" 3 "DevSts4_Resd" ;
VAL_ 820 ExtrLtgStsLoBeam 0 "DevSts4_Off" 1 "DevSts4_On" 2 "DevSts4_Err" 3 "DevSts4_Resd" ;
VAL_ 820 ExtrLtgStsLtgShow 0 "DevSts4_Off" 1 "DevSts4_On" 2 "DevSts4_Err" 3 "DevSts4_Resd" ;
VAL_ 820 ExtrLtgStsPosLiFrnt 0 "DevSts4_Off" 1 "DevSts4_On" 2 "DevSts4_Err" 3 "DevSts4_Resd" ;
VAL_ 820 ExtrLtgStsPosLiRe 0 "DevSts4_Off" 1 "DevSts4_On" 2 "DevSts4_Err" 3 "DevSts4_Resd" ;
VAL_ 820 ExtrLtgStsReFog 0 "DevSts4_Off" 1 "DevSts4_On" 2 "DevSts4_Err" 3 "DevSts4_Resd" ;
VAL_ 820 ExtrLtgStsReverseLi 0 "DevSts4_Off" 1 "DevSts4_On" 2 "DevSts4_Err" 3 "DevSts4_Resd" ;
VAL_ 820 ExtrLtgStsStopLi 0 "DevSts4_Off" 1 "DevSts4_On" 2 "DevSts4_Err" 3 "DevSts4_Resd" ;
VAL_ 820 ExtrLtgStsTurnIndrLe 0 "DevSts4_Off" 1 "DevSts4_On" 2 "DevSts4_Err" 3 "DevSts4_Resd" ;
VAL_ 820 ExtrLtgStsTurnIndrRi 0 "DevSts4_Off" 1 "DevSts4_On" 2 "DevSts4_Err" 3 "DevSts4_Resd" ;
VAL_ 820 ExtrLtgStsWelcome 0 "DevSts4_Off" 1 "DevSts4_On" 2 "DevSts4_Err" 3 "DevSts4_Resd" ;
VAL_ 836 ADIntrLiCtrlReq 0 "ADIntrLiCtrlReq_NoRequest" 1 "ADIntrLiCtrlReq_LightForActivation" 2 "ADIntrLiCtrlReq_LightForDeactivation" 3 "ADIntrLiCtrlReq_LightForNormalSHWAWork" 4 "ADIntrLiCtrlReq_ForNormalTJPWork" 5 "ADIntrLiCtrlReq_ForTakeOverRequest" 6 "ADIntrLiCtrlReq_ForSafeStopOrSpeedReduceRequest" 7 "ADIntrLiCtrlReq_Reserved1" ;
VAL_ 836 AmbientLiEffectStatusBreathingEf 0 "OnOff1_Off" 1 "OnOff1_On" ;
VAL_ 836 AmbientLiEffectStatusIdPen 0 "IdPen_ProfUkwn" 1 "IdPen_Prof1" 2 "IdPen_Prof2" 3 "IdPen_Prof3" 4 "IdPen_Prof4" 5 "IdPen_Prof5" 6 "IdPen_Prof6" 7 "IdPen_Prof7" 8 "IdPen_Prof8" 9 "IdPen_Prof9" 10 "IdPen_Prof10" 11 "IdPen_Prof11" 12 "IdPen_Prof12" 13 "IdPen_Prof13" 14 "IdPen_Resd14" 15 "IdPen_ProfAll" ;
VAL_ 836 AmbientLiEffectStatusTransitionE 0 "OnOff1_Off" 1 "OnOff1_On" ;
VAL_ 836 AmbLiEnduranceMilgOpenReqIdPen 0 "IdPen_ProfUkwn" 1 "IdPen_Prof1" 2 "IdPen_Prof2" 3 "IdPen_Prof3" 4 "IdPen_Prof4" 5 "IdPen_Prof5" 6 "IdPen_Prof6" 7 "IdPen_Prof7" 8 "IdPen_Prof8" 9 "IdPen_Prof9" 10 "IdPen_Prof10" 11 "IdPen_Prof11" 12 "IdPen_Prof12" 13 "IdPen_Prof13" 14 "IdPen_Resd14" 15 "IdPen_ProfAll" ;
VAL_ 836 AmbLiEnduranceMilgOpenReqOnOff1 0 "OnOff1_Off" 1 "OnOff1_On" ;
VAL_ 836 CallSts 0 "CallSts_Inactive" 1 "CallSts_Active" ;
VAL_ 836 Zone1SettingsIdPen 0 "IdPen_ProfUkwn" 1 "IdPen_Prof1" 2 "IdPen_Prof2" 3 "IdPen_Prof3" 4 "IdPen_Prof4" 5 "IdPen_Prof5" 6 "IdPen_Prof6" 7 "IdPen_Prof7" 8 "IdPen_Prof8" 9 "IdPen_Prof9" 10 "IdPen_Prof10" 11 "IdPen_Prof11" 12 "IdPen_Prof12" 13 "IdPen_Prof13" 14 "IdPen_Resd14" 15 "IdPen_ProfAll" ;
VAL_ 836 Zone1SettingsZoneStatus 0 "OnOff1_Off" 1 "OnOff1_On" ;
VAL_ 840 AmbLiPhoneOpenReqIdPen 0 "IdPen_ProfUkwn" 1 "IdPen_Prof1" 2 "IdPen_Prof2" 3 "IdPen_Prof3" 4 "IdPen_Prof4" 5 "IdPen_Prof5" 6 "IdPen_Prof6" 7 "IdPen_Prof7" 8 "IdPen_Prof8" 9 "IdPen_Prof9" 10 "IdPen_Prof10" 11 "IdPen_Prof11" 12 "IdPen_Prof12" 13 "IdPen_Prof13" 14 "IdPen_Resd14" 15 "IdPen_ProfAll" ;
VAL_ 840 AmbLiPhoneOpenReqOnOff1 0 "OnOff1_Off" 1 "OnOff1_On" ;
VAL_ 840 FuLvlLoWarn 0 "Trig1_NoTrig" 1 "Trig1_Trig" ;
VAL_ 840 GoodbyeLiOpenReqIdPen 0 "IdPen_ProfUkwn" 1 "IdPen_Prof1" 2 "IdPen_Prof2" 3 "IdPen_Prof3" 4 "IdPen_Prof4" 5 "IdPen_Prof5" 6 "IdPen_Prof6" 7 "IdPen_Prof7" 8 "IdPen_Prof8" 9 "IdPen_Prof9" 10 "IdPen_Prof10" 11 "IdPen_Prof11" 12 "IdPen_Prof12" 13 "IdPen_Prof13" 14 "IdPen_Resd14" 15 "IdPen_ProfAll" ;
VAL_ 840 GoodbyeLiOpenReqOnOff1 0 "OnOff1_Off" 1 "OnOff1_On" ;
VAL_ 840 WelcomeLiOpenReqIdPen 0 "IdPen_ProfUkwn" 1 "IdPen_Prof1" 2 "IdPen_Prof2" 3 "IdPen_Prof3" 4 "IdPen_Prof4" 5 "IdPen_Prof5" 6 "IdPen_Prof6" 7 "IdPen_Prof7" 8 "IdPen_Prof8" 9 "IdPen_Prof9" 10 "IdPen_Prof10" 11 "IdPen_Prof11" 12 "IdPen_Prof12" 13 "IdPen_Prof13" 14 "IdPen_Resd14" 15 "IdPen_ProfAll" ;
VAL_ 840 WelcomeLiOpenReqOnOff1 0 "OnOff1_Off" 1 "OnOff1_On" ;
VAL_ 840 Zone2SettingsIdPen 0 "IdPen_ProfUkwn" 1 "IdPen_Prof1" 2 "IdPen_Prof2" 3 "IdPen_Prof3" 4 "IdPen_Prof4" 5 "IdPen_Prof5" 6 "IdPen_Prof6" 7 "IdPen_Prof7" 8 "IdPen_Prof8" 9 "IdPen_Prof9" 10 "IdPen_Prof10" 11 "IdPen_Prof11" 12 "IdPen_Prof12" 13 "IdPen_Prof13" 14 "IdPen_Resd14" 15 "IdPen_ProfAll" ;
VAL_ 840 Zone2SettingsZoneStatus 0 "OnOff1_Off" 1 "OnOff1_On" ;
VAL_ 844 AmbLiAllIdPen 0 "IdPen_ProfUkwn" 1 "IdPen_Prof1" 2 "IdPen_Prof2" 3 "IdPen_Prof3" 4 "IdPen_Prof4" 5 "IdPen_Prof5" 6 "IdPen_Prof6" 7 "IdPen_Prof7" 8 "IdPen_Prof8" 9 "IdPen_Prof9" 10 "IdPen_Prof10" 11 "IdPen_Prof11" 12 "IdPen_Prof12" 13 "IdPen_Prof13" 14 "IdPen_Resd14" 15 "IdPen_ProfAll" ;
VAL_ 844 AmbLiAllOnOff1 0 "OnOff1_Off" 1 "OnOff1_On" ;
VAL_ 844 Zone3SettingsIdPen 0 "IdPen_ProfUkwn" 1 "IdPen_Prof1" 2 "IdPen_Prof2" 3 "IdPen_Prof3" 4 "IdPen_Prof4" 5 "IdPen_Prof5" 6 "IdPen_Prof6" 7 "IdPen_Prof7" 8 "IdPen_Prof8" 9 "IdPen_Prof9" 10 "IdPen_Prof10" 11 "IdPen_Prof11" 12 "IdPen_Prof12" 13 "IdPen_Prof13" 14 "IdPen_Resd14" 15 "IdPen_ProfAll" ;
VAL_ 844 Zone3SettingsZoneStatus 0 "OnOff1_Off" 1 "OnOff1_On" ;
VAL_ 34 MusicInfoForMusicShow1StateFlagA 0 "Boolean_FALSE" 1 "Boolean_TRUE" ;
VAL_ 34 MusicInfoForMusicShow1StateFlagN 0 "Boolean_FALSE" 1 "Boolean_TRUE" ;
VAL_ 34 SecRowRiCmftSet 0 "CmftSet_NoReq" 1 "CmftSet_ComfortReq" 2 "CmftSet_ReturnReq" ;
VAL_ 34 WinOpenLDACReq 0 "OnOff1_Off" 1 "OnOff1_On" ;
VAL_ 827 ClimaCmd 0 "OkNotOk_NotOk" 1 "OkNotOk_Ok" ;
VAL_ 827 ErsCmdByKey 0 "ErsCmd_ErsCmdNotSet" 1 "ErsCmd_ErsCmdOn" 2 "ErsCmd_ErsCmdOff" ;
VAL_ 827 RainfallAmnt 0 "AmntSnsr_Amnt" 14 "AmntSnsr_InitValue" 15 "AmntSnsr_Error" ;
VAL_ 48 ChdLockLeftCmd 0 "OnOffSafe1_OnOffSafeInvld1" 1 "OnOffSafe1_OnOffSafeOn" 2 "OnOffSafe1_OnOffSafeOff" 3 "OnOffSafe1_OnOffSafeInvld2" ;
VAL_ 48 ChdLockRightStsToHmi 0 "OnOffSafe1_OnOffSafeInvld1" 1 "OnOffSafe1_OnOffSafeOn" 2 "OnOffSafe1_OnOffSafeOff" 3 "OnOffSafe1_OnOffSafeInvld2" ;
VAL_ 48 DoorDrvrHndlHMIStsDeployedOverTm 0 "Boolean_FALSE" 1 "Boolean_TRUE" ;
VAL_ 48 DoorDrvrHndlHMIStsReserved1 0 "Boolean_FALSE" 1 "Boolean_TRUE" ;
VAL_ 48 DoorDrvrHndlHMIStsRetractOverTmd 0 "Boolean_FALSE" 1 "Boolean_TRUE" ;
VAL_ 48 DoorDrvrHndlHMIStsUnsScsHallSnsr 0 "Boolean_FALSE" 1 "Boolean_TRUE" ;
VAL_ 48 DoorDrvrRelsFailCinchOverTimed 0 "Boolean_FALSE" 1 "Boolean_TRUE" ;
VAL_ 48 DoorDrvrRelsFailFailure1 0 "Boolean_FALSE" 1 "Boolean_TRUE" ;
VAL_ 48 DoorDrvrRelsFailMechRels 0 "Boolean_FALSE" 1 "Boolean_TRUE" ;
VAL_ 48 FltOfIndcrTurnOnDrvrSide 0 "DevErrSts2_NoFlt" 1 "DevErrSts2_Flt" ;
VAL_ 48 MemBtnPsdMemBtn1 0 "Boolean_FALSE" 1 "Boolean_TRUE" ;
VAL_ 48 MemBtnPsdMemBtn2 0 "Boolean_FALSE" 1 "Boolean_TRUE" ;
VAL_ 48 MemBtnPsdMemBtn3 0 "Boolean_FALSE" 1 "Boolean_TRUE" ;
VAL_ 48 MemBtnPsdMemButM 0 "Boolean_FALSE" 1 "Boolean_TRUE" ;
VAL_ 48 MirrFoldStsAtDrvr 0 "MirrFoldStsTyp_MirrFoldPosnUndefd" 1 "MirrFoldStsTyp_MirrNotFoldPosn" 2 "MirrFoldStsTyp_MirrFoldPosn" 3 "MirrFoldStsTyp_MirrMovgToNotFold" 4 "MirrFoldStsTyp_MirrMovgToFold" ;
VAL_ 48 ShortDropWinDrvrSts 0 "ShortDropSts_Idle" 1 "ShortDropSts_WindowDown" 2 "ShortDropSts_WindowClosed" 3 "ShortDropSts_NotUsed" ;
VAL_ 48 WinDsblRightCmd 0 "OnOff1_Off" 1 "OnOff1_On" ;
VAL_ 48 WinFailrStsAtDrvr 0 "Flt_NoFault" 1 "Flt_Fault" ;
VAL_ 480 AmbTRawAtDrvrSideQly 0 "GenQf1_UndefindDataAccur" 1 "GenQf1_TmpUndefdData" 2 "GenQf1_DataAccurNotWithinSpcn" 3 "GenQf1_AccurData" ;
VAL_ 480 ChdLockRightFailStsToHmi 0 "OnOffSafe1_OnOffSafeInvld1" 1 "OnOffSafe1_OnOffSafeOn" 2 "OnOffSafe1_OnOffSafeOff" 3 "OnOffSafe1_OnOffSafeInvld2" ;
VAL_ 480 MirrDefrstAtDrvSts 0 "OnOff1_Off" 1 "OnOff1_On" ;
VAL_ 291 DoorDrvrCinhIntFailInfCinchFlt1 0 "Boolean_FALSE" 1 "Boolean_TRUE" ;
VAL_ 291 DoorDrvrCinhIntFailInfCinchRestF 0 "Boolean_FALSE" 1 "Boolean_TRUE" ;
VAL_ 291 DoorDrvrHndlSts 0 "DoorHndlSts_Ukwn" 1 "DoorHndlSts_FullRtrctd" 2 "DoorHndlSts_MovgOut" 3 "DoorHndlSts_StopDurgDply" 4 "DoorHndlSts_FullDplyd" 5 "DoorHndlSts_MovgIn" 6 "DoorHndlSts_StopDurgRtrct" 7 "DoorHndlSts_Flt" ;
VAL_ 291 DoorDrvrSwpLockBtn 0 "PsdNotPsd1_NotPsd" 1 "PsdNotPsd1_Psd" ;
VAL_ 291 MirrDwnStsAtDrvr 0 "MirrDwnStsTyp_MirrTiltUndefd" 1 "MirrDwnStsTyp_MirrUpPosn" 2 "MirrDwnStsTyp_MirrTiltPosn" 3 "MirrDwnStsTyp_MirrMovgToUpPosn" 4 "MirrDwnStsTyp_MirrMovgToTiltPosn" ;
VAL_ 5 ChdLockRightCmd 0 "OnOffSafe1_OnOffSafeInvld1" 1 "OnOffSafe1_OnOffSafeOn" 2 "OnOffSafe1_OnOffSafeOff" 3 "OnOffSafe1_OnOffSafeInvld2" ;
VAL_ 5 ChdPrtnLeftFailStsToHmi 0 "OnOffSafe1_OnOffSafeInvld1" 1 "OnOffSafe1_OnOffSafeOn" 2 "OnOffSafe1_OnOffSafeOff" 3 "OnOffSafe1_OnOffSafeInvld2" ;
VAL_ 5 ChdPrtnLeftStsToHmi 0 "OnOffSafe1_OnOffSafeInvld1" 1 "OnOffSafe1_OnOffSafeOn" 2 "OnOffSafe1_OnOffSafeOff" 3 "OnOffSafe1_OnOffSafeInvld2" ;
VAL_ 5 DoorDrvrLatPawlSt 0 "DoorSts2_Ukwn" 1 "DoorSts2_Opend" 2 "DoorSts2_Clsd" ;
VAL_ 5 DoorDrvrLatPosn 0 "DoorPos_Undefined" 1 "DoorPos_FullyClosed" 2 "DoorPos_SecondaryPosition" 3 "DoorPos_FullyOpen" ;
VAL_ 5 DoorDrvrLockSts 0 "LockSts2_LockStsUkwn" 1 "LockSts2_Unlckd" 2 "LockSts2_Lockd" 3 "LockSts2_SafeLockd" ;
VAL_ 5 DoorDrvrOpenLowReqOutdSwt1 0 "PsdNotPsd3_NoInfo1" 1 "PsdNotPsd3_Psd" 2 "PsdNotPsd3_NotPsd" 3 "PsdNotPsd3_NoInfo2" ;
VAL_ 5 DoorDrvrOpenReqInsdSwt1 0 "PsdNotPsd3_NoInfo1" 1 "PsdNotPsd3_Psd" 2 "PsdNotPsd3_NotPsd" 3 "PsdNotPsd3_NoInfo2" ;
VAL_ 5 DoorDrvrSwtIntrLockgReq 0 "LockgCenReq2_Idle" 1 "LockgCenReq2_Unlck" 2 "LockgCenReq2_Lock" ;
VAL_ 5 LcmaLedStsDrvrSide 0 "YesNo1_Yes" 1 "YesNo1_No" ;
VAL_ 5 MirrAtDrvrInMovmt 0 "Boolean_FALSE" 1 "Boolean_TRUE" ;
VAL_ 5 MirrBtnPsdAtDrvr 0 "Boolean_FALSE" 1 "Boolean_TRUE" ;
VAL_ 5 MirrCmdAtPassMirrDwnCmd 0 "MirrDwnCmdTyp_Idle" 1 "MirrDwnCmdTyp_MirrUp" 2 "MirrDwnCmdTyp_MirrDwn" ;
VAL_ 5 MirrCmdAtPassMirrFoldCmd 0 "MirrFoldCmdTyp_Idle" 1 "MirrFoldCmdTyp_FoldIn" 2 "MirrFoldCmdTyp_FoldOut" ;
VAL_ 5 MirrCmdAtPassMirrPosAdjCmd 0 "MirrAdjCmdTyp_Idle" 1 "MirrAdjCmdTyp_Up" 2 "MirrAdjCmdTyp_Dwn" 3 "MirrAdjCmdTyp_Le" 4 "MirrAdjCmdTyp_Ri" ;
VAL_ 5 MirrPosnDownLdSts 0 "Sts_Resd" 1 "Sts_Err" 2 "Sts_CmplOk" 3 "Sts_InProgs" ;
VAL_ 5 MirrPosnFromCldAtDrvrFb 0 "Sts_Resd" 1 "Sts_Err" 2 "Sts_CmplOk" 3 "Sts_InProgs" ;
VAL_ 5 MirrPosnFromCldAtPassFb 0 "Sts_Resd" 1 "Sts_Err" 2 "Sts_CmplOk" 3 "Sts_InProgs" ;
VAL_ 5 MirrPosnMemSts 0 "Sts_Resd" 1 "Sts_Err" 2 "Sts_CmplOk" 3 "Sts_InProgs" ;
VAL_ 5 WinDsblLeftCmd 0 "Boolean_FALSE" 1 "Boolean_TRUE" ;
VAL_ 5 WinPosnStsAtDrvr 0 "WinAndRoofAndCurtPosnTyp_PosnUkwn" 1 "WinAndRoofAndCurtPosnTyp_ClsFull" 2 "WinAndRoofAndCurtPosnTyp_PercOpen4" 3 "WinAndRoofAndCurtPosnTyp_PercOpen8" 4 "WinAndRoofAndCurtPosnTyp_PercOpen12" 5 "WinAndRoofAndCurtPosnTyp_PercOpen16" 6 "WinAndRoofAndCurtPosnTyp_PercOpen20" 7 "WinAndRoofAndCurtPosnTyp_PercOpen24" 8 "WinAndRoofAndCurtPosnTyp_PercOpen28" 9 "WinAndRoofAndCurtPosnTyp_PercOpen32" 10 "WinAndRoofAndCurtPosnTyp_PercOpen36" 11 "WinAndRoofAndCurtPosnTyp_PercOpen40" 12 "WinAndRoofAndCurtPosnTyp_PercOpen44" 13 "WinAndRoofAndCurtPosnTyp_PercOpen48" 14 "WinAndRoofAndCurtPosnTyp_PercOpen52" 15 "WinAndRoofAndCurtPosnTyp_PercOpen56" 16 "WinAndRoofAndCurtPosnTyp_PercOpen60" 17 "WinAndRoofAndCurtPosnTyp_PercOpen64" 18 "WinAndRoofAndCurtPosnTyp_PercOpen68" 19 "WinAndRoofAndCurtPosnTyp_PercOpen72" 20 "WinAndRoofAndCurtPosnTyp_PercOpen76" 21 "WinAndRoofAndCurtPosnTyp_PercOpen80" 22 "WinAndRoofAndCurtPosnTyp_PercOpen84" 23 "WinAndRoofAndCurtPosnTyp_PercOpen88" 24 "WinAndRoofAndCurtPosnTyp_PercOpen92" 25 "WinAndRoofAndCurtPosnTyp_PercOpen96" 26 "WinAndRoofAndCurtPosnTyp_OpenFull" 27 "WinAndRoofAndCurtPosnTyp_Resd1" 28 "WinAndRoofAndCurtPosnTyp_Resd2" 29 "WinAndRoofAndCurtPosnTyp_Resd3" 30 "WinAndRoofAndCurtPosnTyp_Resd4" 31 "WinAndRoofAndCurtPosnTyp_Movg" ;
VAL_ 192 CenLockMacKeyReq 0 "LockgCenReq2_Idle" 1 "LockgCenReq2_Unlck" 2 "LockgCenReq2_Lock" ;
VAL_ 192 WinSwtReqFrntLe 0 "WinPosnReq_Idle" 1 "WinPosnReq_UpMan" 2 "WinPosnReq_UpAut" 3 "WinPosnReq_DwnMan" 4 "WinPosnReq_DwnAut" 5 "WinPosnReq_NotDefd" ;
VAL_ 192 WinSwtReqFrntRi 0 "WinPosnReq_Idle" 1 "WinPosnReq_UpMan" 2 "WinPosnReq_UpAut" 3 "WinPosnReq_DwnMan" 4 "WinPosnReq_DwnAut" 5 "WinPosnReq_NotDefd" ;
VAL_ 192 WinSwtReqReLe 0 "WinPosnReq_Idle" 1 "WinPosnReq_UpMan" 2 "WinPosnReq_UpAut" 3 "WinPosnReq_DwnMan" 4 "WinPosnReq_DwnAut" 5 "WinPosnReq_NotDefd" ;
VAL_ 192 WinSwtReqReRi 0 "WinPosnReq_Idle" 1 "WinPosnReq_UpMan" 2 "WinPosnReq_UpAut" 3 "WinPosnReq_DwnMan" 4 "WinPosnReq_DwnAut" 5 "WinPosnReq_NotDefd" ;
VAL_ 1347 VFCVectorDDMVFCid0 0 "VFCOnOff_Off" 1 "VFCOnOff_On" ;
VAL_ 1347 VFCVectorDDMVFCid1 0 "VFCOnOff_Off" 1 "VFCOnOff_On" ;
VAL_ 1347 VFCVectorDDMVFCid10 0 "VFCOnOff_Off" 1 "VFCOnOff_On" ;
VAL_ 1347 VFCVectorDDMVFCid11 0 "VFCOnOff_Off" 1 "VFCOnOff_On" ;
VAL_ 1347 VFCVectorDDMVFCid12 0 "VFCOnOff_Off" 1 "VFCOnOff_On" ;
VAL_ 1347 VFCVectorDDMVFCid13 0 "VFCOnOff_Off" 1 "VFCOnOff_On" ;
VAL_ 1347 VFCVectorDDMVFCid14 0 "VFCOnOff_Off" 1 "VFCOnOff_On" ;
VAL_ 1347 VFCVectorDDMVFCid15 0 "VFCOnOff_Off" 1 "VFCOnOff_On" ;
VAL_ 1347 VFCVectorDDMVFCid16 0 "VFCOnOff_Off" 1 "VFCOnOff_On" ;
VAL_ 1347 VFCVectorDDMVFCid17 0 "VFCOnOff_Off" 1 "VFCOnOff_On" ;
VAL_ 1347 VFCVectorDDMVFCid18 0 "VFCOnOff_Off" 1 "VFCOnOff_On" ;
VAL_ 1347 VFCVectorDDMVFCid19 0 "VFCOnOff_Off" 1 "VFCOnOff_On" ;
VAL_ 1347 VFCVectorDDMVFCid2 0 "VFCOnOff_Off" 1 "VFCOnOff_On" ;
VAL_ 1347 VFCVectorDDMVFCid20 0 "VFCOnOff_Off" 1 "VFCOnOff_On" ;
VAL_ 1347 VFCVectorDDMVFCid21 0 "VFCOnOff_Off" 1 "VFCOnOff_On" ;
VAL_ 1347 VFCVectorDDMVFCid22 0 "VFCOnOff_Off" 1 "VFCOnOff_On" ;
VAL_ 1347 VFCVectorDDMVFCid23 0 "VFCOnOff_Off" 1 "VFCOnOff_On" ;
VAL_ 1347 VFCVectorDDMVFCid24 0 "VFCOnOff_Off" 1 "VFCOnOff_On" ;
VAL_ 1347 VFCVectorDDMVFCid25 0 "VFCOnOff_Off" 1 "VFCOnOff_On" ;
VAL_ 1347 VFCVectorDDMVFCid26 0 "VFCOnOff_Off" 1 "VFCOnOff_On" ;
VAL_ 1347 VFCVectorDDMVFCid27 0 "VFCOnOff_Off" 1 "VFCOnOff_On" ;
VAL_ 1347 VFCVectorDDMVFCid28 0 "VFCOnOff_Off" 1 "VFCOnOff_On" ;
VAL_ 1347 VFCVectorDDMVFCid29 0 "VFCOnOff_Off" 1 "VFCOnOff_On" ;
VAL_ 1347 VFCVectorDDMVFCid3 0 "VFCOnOff_Off" 1 "VFCOnOff_On" ;
VAL_ 1347 VFCVectorDDMVFCid30 0 "VFCOnOff_Off" 1 "VFCOnOff_On" ;
VAL_ 1347 VFCVectorDDMVFCid31 0 "VFCOnOff_Off" 1 "VFCOnOff_On" ;
VAL_ 1347 VFCVectorDDMVFCid32 0 "VFCOnOff_Off" 1 "VFCOnOff_On" ;
VAL_ 1347 VFCVectorDDMVFCid33 0 "VFCOnOff_Off" 1 "VFCOnOff_On" ;
VAL_ 1347 VFCVectorDDMVFCid34 0 "VFCOnOff_Off" 1 "VFCOnOff_On" ;
VAL_ 1347 VFCVectorDDMVFCid35 0 "VFCOnOff_Off" 1 "VFCOnOff_On" ;
VAL_ 1347 VFCVectorDDMVFCid36 0 "VFCOnOff_Off" 1 "VFCOnOff_On" ;
VAL_ 1347 VFCVectorDDMVFCid37 0 "VFCOnOff_Off" 1 "VFCOnOff_On" ;
VAL_ 1347 VFCVectorDDMVFCid38 0 "VFCOnOff_Off" 1 "VFCOnOff_On" ;
VAL_ 1347 VFCVectorDDMVFCid39 0 "VFCOnOff_Off" 1 "VFCOnOff_On" ;
VAL_ 1347 VFCVectorDDMVFCid4 0 "VFCOnOff_Off" 1 "VFCOnOff_On" ;
VAL_ 1347 VFCVectorDDMVFCid40 0 "VFCOnOff_Off" 1 "VFCOnOff_On" ;
VAL_ 1347 VFCVectorDDMVFCid41 0 "VFCOnOff_Off" 1 "VFCOnOff_On" ;
VAL_ 1347 VFCVectorDDMVFCid42 0 "VFCOnOff_Off" 1 "VFCOnOff_On" ;
VAL_ 1347 VFCVectorDDMVFCid43 0 "VFCOnOff_Off" 1 "VFCOnOff_On" ;
VAL_ 1347 VFCVectorDDMVFCid44 0 "VFCOnOff_Off" 1 "VFCOnOff_On" ;
VAL_ 1347 VFCVectorDDMVFCid45 0 "VFCOnOff_Off" 1 "VFCOnOff_On" ;
VAL_ 1347 VFCVectorDDMVFCid46 0 "VFCOnOff_Off" 1 "VFCOnOff_On" ;
VAL_ 1347 VFCVectorDDMVFCid47 0 "VFCOnOff_Off" 1 "VFCOnOff_On" ;
VAL_ 1347 VFCVectorDDMVFCid48 0 "VFCOnOff_Off" 1 "VFCOnOff_On" ;
VAL_ 1347 VFCVectorDDMVFCid49 0 "VFCOnOff_Off" 1 "VFCOnOff_On" ;
VAL_ 1347 VFCVectorDDMVFCid5 0 "VFCOnOff_Off" 1 "VFCOnOff_On" ;
VAL_ 1347 VFCVectorDDMVFCid50 0 "VFCOnOff_Off" 1 "VFCOnOff_On" ;
VAL_ 1347 VFCVectorDDMVFCid51 0 "VFCOnOff_Off" 1 "VFCOnOff_On" ;
VAL_ 1347 VFCVectorDDMVFCid52 0 "VFCOnOff_Off" 1 "VFCOnOff_On" ;
VAL_ 1347 VFCVectorDDMVFCid53 0 "VFCOnOff_Off" 1 "VFCOnOff_On" ;
VAL_ 1347 VFCVectorDDMVFCid54 0 "VFCOnOff_Off" 1 "VFCOnOff_On" ;
VAL_ 1347 VFCVectorDDMVFCid55 0 "VFCOnOff_Off" 1 "VFCOnOff_On" ;
VAL_ 1347 VFCVectorDDMVFCid56 0 "VFCOnOff_Off" 1 "VFCOnOff_On" ;
VAL_ 1347 VFCVectorDDMVFCid57 0 "VFCOnOff_Off" 1 "VFCOnOff_On" ;
VAL_ 1347 VFCVectorDDMVFCid58 0 "VFCOnOff_Off" 1 "VFCOnOff_On" ;
VAL_ 1347 VFCVectorDDMVFCid59 0 "VFCOnOff_Off" 1 "VFCOnOff_On" ;
VAL_ 1347 VFCVectorDDMVFCid6 0 "VFCOnOff_Off" 1 "VFCOnOff_On" ;
VAL_ 1347 VFCVectorDDMVFCid60 0 "VFCOnOff_Off" 1 "VFCOnOff_On" ;
VAL_ 1347 VFCVectorDDMVFCid61 0 "VFCOnOff_Off" 1 "VFCOnOff_On" ;
VAL_ 1347 VFCVectorDDMVFCid7 0 "VFCOnOff_Off" 1 "VFCOnOff_On" ;
VAL_ 1347 VFCVectorDDMVFCid8 0 "VFCOnOff_Off" 1 "VFCOnOff_On" ;
VAL_ 1347 VFCVectorDDMVFCid9 0 "VFCOnOff_Off" 1 "VFCOnOff_On" ;
VAL_ 16 DoorPassLatPawlSt 0 "DoorSts2_Ukwn" 1 "DoorSts2_Opend" 2 "DoorSts2_Clsd" ;
VAL_ 16 DoorPassLatPosn 0 "DoorPos_Undefined" 1 "DoorPos_FullyClosed" 2 "DoorPos_SecondaryPosition" 3 "DoorPos_FullyOpen" ;
VAL_ 16 DoorPassLockSts 0 "LockSts2_LockStsUkwn" 1 "LockSts2_Unlckd" 2 "LockSts2_Lockd" 3 "LockSts2_SafeLockd" ;
VAL_ 16 DoorPassOpenLowReqOutdSwt1 0 "PsdNotPsd3_NoInfo1" 1 "PsdNotPsd3_Psd" 2 "PsdNotPsd3_NotPsd" 3 "PsdNotPsd3_NoInfo2" ;
VAL_ 16 DoorPassOpenReqInsdSwt1 0 "PsdNotPsd3_NoInfo1" 1 "PsdNotPsd3_Psd" 2 "PsdNotPsd3_NotPsd" 3 "PsdNotPsd3_NoInfo2" ;
VAL_ 16 DoorPassRelsFailCinchOverTimed 0 "Boolean_FALSE" 1 "Boolean_TRUE" ;
VAL_ 16 DoorPassRelsFailFailure1 0 "Boolean_FALSE" 1 "Boolean_TRUE" ;
VAL_ 16 DoorPassRelsFailMechRels 0 "Boolean_FALSE" 1 "Boolean_TRUE" ;
VAL_ 16 DoorPassSwtIntrLockgReq 0 "LockgCenReq2_Idle" 1 "LockgCenReq2_Unlck" 2 "LockgCenReq2_Lock" ;
VAL_ 16 FltOfIndcrTurnOnPassSide 0 "DevErrSts2_NoFlt" 1 "DevErrSts2_Flt" ;
VAL_ 16 LcmaLedStsPassSide 0 "YesNo1_Yes" 1 "YesNo1_No" ;
VAL_ 16 MirrAtPassInMovmt 0 "Boolean_FALSE" 1 "Boolean_TRUE" ;
VAL_ 16 MirrDwnStsAtPass 0 "MirrDwnStsTyp_MirrTiltUndefd" 1 "MirrDwnStsTyp_MirrUpPosn" 2 "MirrDwnStsTyp_MirrTiltPosn" 3 "MirrDwnStsTyp_MirrMovgToUpPosn" 4 "MirrDwnStsTyp_MirrMovgToTiltPosn" ;
VAL_ 16 MirrFoldStsAtPass 0 "MirrFoldStsTyp_MirrFoldPosnUndefd" 1 "MirrFoldStsTyp_MirrNotFoldPosn" 2 "MirrFoldStsTyp_MirrFoldPosn" 3 "MirrFoldStsTyp_MirrMovgToNotFold" 4 "MirrFoldStsTyp_MirrMovgToFold" ;
VAL_ 16 PassMemBtnPsdMemBtn1 0 "Boolean_FALSE" 1 "Boolean_TRUE" ;
VAL_ 16 PassMemBtnPsdMemBtn2 0 "Boolean_FALSE" 1 "Boolean_TRUE" ;
VAL_ 16 PassMemBtnPsdMemBtn3 0 "Boolean_FALSE" 1 "Boolean_TRUE" ;
VAL_ 16 PassMemBtnPsdMemButM 0 "Boolean_FALSE" 1 "Boolean_TRUE" ;
VAL_ 16 ShortDropWinPassSts 0 "ShortDropSts_Idle" 1 "ShortDropSts_WindowDown" 2 "ShortDropSts_WindowClosed" 3 "ShortDropSts_NotUsed" ;
VAL_ 16 WinPosnStsAtPass 0 "WinAndRoofAndCurtPosnTyp_PosnUkwn" 1 "WinAndRoofAndCurtPosnTyp_ClsFull" 2 "WinAndRoofAndCurtPosnTyp_PercOpen4" 3 "WinAndRoofAndCurtPosnTyp_PercOpen8" 4 "WinAndRoofAndCurtPosnTyp_PercOpen12" 5 "WinAndRoofAndCurtPosnTyp_PercOpen16" 6 "WinAndRoofAndCurtPosnTyp_PercOpen20" 7 "WinAndRoofAndCurtPosnTyp_PercOpen24" 8 "WinAndRoofAndCurtPosnTyp_PercOpen28" 9 "WinAndRoofAndCurtPosnTyp_PercOpen32" 10 "WinAndRoofAndCurtPosnTyp_PercOpen36" 11 "WinAndRoofAndCurtPosnTyp_PercOpen40" 12 "WinAndRoofAndCurtPosnTyp_PercOpen44" 13 "WinAndRoofAndCurtPosnTyp_PercOpen48" 14 "WinAndRoofAndCurtPosnTyp_PercOpen52" 15 "WinAndRoofAndCurtPosnTyp_PercOpen56" 16 "WinAndRoofAndCurtPosnTyp_PercOpen60" 17 "WinAndRoofAndCurtPosnTyp_PercOpen64" 18 "WinAndRoofAndCurtPosnTyp_PercOpen68" 19 "WinAndRoofAndCurtPosnTyp_PercOpen72" 20 "WinAndRoofAndCurtPosnTyp_PercOpen76" 21 "WinAndRoofAndCurtPosnTyp_PercOpen80" 22 "WinAndRoofAndCurtPosnTyp_PercOpen84" 23 "WinAndRoofAndCurtPosnTyp_PercOpen88" 24 "WinAndRoofAndCurtPosnTyp_PercOpen92" 25 "WinAndRoofAndCurtPosnTyp_PercOpen96" 26 "WinAndRoofAndCurtPosnTyp_OpenFull" 27 "WinAndRoofAndCurtPosnTyp_Resd1" 28 "WinAndRoofAndCurtPosnTyp_Resd2" 29 "WinAndRoofAndCurtPosnTyp_Resd3" 30 "WinAndRoofAndCurtPosnTyp_Resd4" 31 "WinAndRoofAndCurtPosnTyp_Movg" ;
VAL_ 293 AmbTRawAtPassSideQly 0 "GenQf1_UndefindDataAccur" 1 "GenQf1_TmpUndefdData" 2 "GenQf1_DataAccurNotWithinSpcn" 3 "GenQf1_AccurData" ;
VAL_ 293 DoorPassCinhIntFailInfCinchFlt1 0 "Boolean_FALSE" 1 "Boolean_TRUE" ;
VAL_ 293 DoorPassCinhIntFailInfCinchRestF 0 "Boolean_FALSE" 1 "Boolean_TRUE" ;
VAL_ 293 DoorPassHndlHMIStsDeployedOverTm 0 "Boolean_FALSE" 1 "Boolean_TRUE" ;
VAL_ 293 DoorPassHndlHMIStsReserved1 0 "Boolean_FALSE" 1 "Boolean_TRUE" ;
VAL_ 293 DoorPassHndlHMIStsRetractOverTmd 0 "Boolean_FALSE" 1 "Boolean_TRUE" ;
VAL_ 293 DoorPassHndlHMIStsUnsScsHallSnsr 0 "Boolean_FALSE" 1 "Boolean_TRUE" ;
VAL_ 293 DoorPassHndlSts 0 "DoorHndlSts_Ukwn" 1 "DoorHndlSts_FullRtrctd" 2 "DoorHndlSts_MovgOut" 3 "DoorHndlSts_StopDurgDply" 4 "DoorHndlSts_FullDplyd" 5 "DoorHndlSts_MovgIn" 6 "DoorHndlSts_StopDurgRtrct" 7 "DoorHndlSts_Flt" ;
VAL_ 293 MirrDefrstAtPassSts 0 "OnOff1_Off" 1 "OnOff1_On" ;
VAL_ 293 MirrPosnFromCldAtPassIntFb 0 "Sts_Resd" 1 "Sts_Err" 2 "Sts_CmplOk" 3 "Sts_InProgs" ;
VAL_ 293 WinFailrStsAtPass 0 "Flt_NoFault" 1 "Flt_Fault" ;
VAL_ 565 DoorPassSwpLockBtn 0 "PsdNotPsd1_NotPsd" 1 "PsdNotPsd1_Psd" ;
VAL_ 1348 VFCVectorPDMVFCid0 0 "VFCOnOff_Off" 1 "VFCOnOff_On" ;
VAL_ 1348 VFCVectorPDMVFCid1 0 "VFCOnOff_Off" 1 "VFCOnOff_On" ;
VAL_ 1348 VFCVectorPDMVFCid10 0 "VFCOnOff_Off" 1 "VFCOnOff_On" ;
VAL_ 1348 VFCVectorPDMVFCid11 0 "VFCOnOff_Off" 1 "VFCOnOff_On" ;
VAL_ 1348 VFCVectorPDMVFCid12 0 "VFCOnOff_Off" 1 "VFCOnOff_On" ;
VAL_ 1348 VFCVectorPDMVFCid13 0 "VFCOnOff_Off" 1 "VFCOnOff_On" ;
VAL_ 1348 VFCVectorPDMVFCid14 0 "VFCOnOff_Off" 1 "VFCOnOff_On" ;
VAL_ 1348 VFCVectorPDMVFCid15 0 "VFCOnOff_Off" 1 "VFCOnOff_On" ;
VAL_ 1348 VFCVectorPDMVFCid16 0 "VFCOnOff_Off" 1 "VFCOnOff_On" ;
VAL_ 1348 VFCVectorPDMVFCid17 0 "VFCOnOff_Off" 1 "VFCOnOff_On" ;
VAL_ 1348 VFCVectorPDMVFCid18 0 "VFCOnOff_Off" 1 "VFCOnOff_On" ;
VAL_ 1348 VFCVectorPDMVFCid19 0 "VFCOnOff_Off" 1 "VFCOnOff_On" ;
VAL_ 1348 VFCVectorPDMVFCid2 0 "VFCOnOff_Off" 1 "VFCOnOff_On" ;
VAL_ 1348 VFCVectorPDMVFCid20 0 "VFCOnOff_Off" 1 "VFCOnOff_On" ;
VAL_ 1348 VFCVectorPDMVFCid21 0 "VFCOnOff_Off" 1 "VFCOnOff_On" ;
VAL_ 1348 VFCVectorPDMVFCid22 0 "VFCOnOff_Off" 1 "VFCOnOff_On" ;
VAL_ 1348 VFCVectorPDMVFCid23 0 "VFCOnOff_Off" 1 "VFCOnOff_On" ;
VAL_ 1348 VFCVectorPDMVFCid24 0 "VFCOnOff_Off" 1 "VFCOnOff_On" ;
VAL_ 1348 VFCVectorPDMVFCid25 0 "VFCOnOff_Off" 1 "VFCOnOff_On" ;
VAL_ 1348 VFCVectorPDMVFCid26 0 "VFCOnOff_Off" 1 "VFCOnOff_On" ;
VAL_ 1348 VFCVectorPDMVFCid27 0 "VFCOnOff_Off" 1 "VFCOnOff_On" ;
VAL_ 1348 VFCVectorPDMVFCid28 0 "VFCOnOff_Off" 1 "VFCOnOff_On" ;
VAL_ 1348 VFCVectorPDMVFCid29 0 "VFCOnOff_Off" 1 "VFCOnOff_On" ;
VAL_ 1348 VFCVectorPDMVFCid3 0 "VFCOnOff_Off" 1 "VFCOnOff_On" ;
VAL_ 1348 VFCVectorPDMVFCid30 0 "VFCOnOff_Off" 1 "VFCOnOff_On" ;
VAL_ 1348 VFCVectorPDMVFCid31 0 "VFCOnOff_Off" 1 "VFCOnOff_On" ;
VAL_ 1348 VFCVectorPDMVFCid32 0 "VFCOnOff_Off" 1 "VFCOnOff_On" ;
VAL_ 1348 VFCVectorPDMVFCid33 0 "VFCOnOff_Off" 1 "VFCOnOff_On" ;
VAL_ 1348 VFCVectorPDMVFCid34 0 "VFCOnOff_Off" 1 "VFCOnOff_On" ;
VAL_ 1348 VFCVectorPDMVFCid35 0 "VFCOnOff_Off" 1 "VFCOnOff_On" ;
VAL_ 1348 VFCVectorPDMVFCid36 0 "VFCOnOff_Off" 1 "VFCOnOff_On" ;
VAL_ 1348 VFCVectorPDMVFCid37 0 "VFCOnOff_Off" 1 "VFCOnOff_On" ;
VAL_ 1348 VFCVectorPDMVFCid38 0 "VFCOnOff_Off" 1 "VFCOnOff_On" ;
VAL_ 1348 VFCVectorPDMVFCid39 0 "VFCOnOff_Off" 1 "VFCOnOff_On" ;
VAL_ 1348 VFCVectorPDMVFCid4 0 "VFCOnOff_Off" 1 "VFCOnOff_On" ;
VAL_ 1348 VFCVectorPDMVFCid40 0 "VFCOnOff_Off" 1 "VFCOnOff_On" ;
VAL_ 1348 VFCVectorPDMVFCid41 0 "VFCOnOff_Off" 1 "VFCOnOff_On" ;
VAL_ 1348 VFCVectorPDMVFCid42 0 "VFCOnOff_Off" 1 "VFCOnOff_On" ;
VAL_ 1348 VFCVectorPDMVFCid43 0 "VFCOnOff_Off" 1 "VFCOnOff_On" ;
VAL_ 1348 VFCVectorPDMVFCid44 0 "VFCOnOff_Off" 1 "VFCOnOff_On" ;
VAL_ 1348 VFCVectorPDMVFCid45 0 "VFCOnOff_Off" 1 "VFCOnOff_On" ;
VAL_ 1348 VFCVectorPDMVFCid46 0 "VFCOnOff_Off" 1 "VFCOnOff_On" ;
VAL_ 1348 VFCVectorPDMVFCid47 0 "VFCOnOff_Off" 1 "VFCOnOff_On" ;
VAL_ 1348 VFCVectorPDMVFCid48 0 "VFCOnOff_Off" 1 "VFCOnOff_On" ;
VAL_ 1348 VFCVectorPDMVFCid49 0 "VFCOnOff_Off" 1 "VFCOnOff_On" ;
VAL_ 1348 VFCVectorPDMVFCid5 0 "VFCOnOff_Off" 1 "VFCOnOff_On" ;
VAL_ 1348 VFCVectorPDMVFCid50 0 "VFCOnOff_Off" 1 "VFCOnOff_On" ;
VAL_ 1348 VFCVectorPDMVFCid51 0 "VFCOnOff_Off" 1 "VFCOnOff_On" ;
VAL_ 1348 VFCVectorPDMVFCid52 0 "VFCOnOff_Off" 1 "VFCOnOff_On" ;
VAL_ 1348 VFCVectorPDMVFCid53 0 "VFCOnOff_Off" 1 "VFCOnOff_On" ;
VAL_ 1348 VFCVectorPDMVFCid54 0 "VFCOnOff_Off" 1 "VFCOnOff_On" ;
VAL_ 1348 VFCVectorPDMVFCid55 0 "VFCOnOff_Off" 1 "VFCOnOff_On" ;
VAL_ 1348 VFCVectorPDMVFCid56 0 "VFCOnOff_Off" 1 "VFCOnOff_On" ;
VAL_ 1348 VFCVectorPDMVFCid57 0 "VFCOnOff_Off" 1 "VFCOnOff_On" ;
VAL_ 1348 VFCVectorPDMVFCid58 0 "VFCOnOff_Off" 1 "VFCOnOff_On" ;
VAL_ 1348 VFCVectorPDMVFCid59 0 "VFCOnOff_Off" 1 "VFCOnOff_On" ;
VAL_ 1348 VFCVectorPDMVFCid6 0 "VFCOnOff_Off" 1 "VFCOnOff_On" ;
VAL_ 1348 VFCVectorPDMVFCid60 0 "VFCOnOff_Off" 1 "VFCOnOff_On" ;
VAL_ 1348 VFCVectorPDMVFCid61 0 "VFCOnOff_Off" 1 "VFCOnOff_On" ;
VAL_ 1348 VFCVectorPDMVFCid7 0 "VFCOnOff_Off" 1 "VFCOnOff_On" ;
VAL_ 1348 VFCVectorPDMVFCid8 0 "VFCOnOff_Off" 1 "VFCOnOff_On" ;
VAL_ 1348 VFCVectorPDMVFCid9 0 "VFCOnOff_Off" 1 "VFCOnOff_On" ;
VAL_ 416 BodyMissComPrmntFromBoot 0 "Boolean_FALSE" 1 "Boolean_TRUE" ;
VAL_ 149 SwtTrClsSts 0 "PsdNotPsd_NotPsd" 1 "PsdNotPsd_Psd" ;
VAL_ 149 TopPosHmiFeedBackUknFl 0 "UknFl_Unknown" 1 "UknFl_Fail" ;
VAL_ 149 TrAntiPnch 0 "Boolean_FALSE" 1 "Boolean_TRUE" ;
VAL_ 149 TrObstclDetn 0 "Boolean_FALSE" 1 "Boolean_TRUE" ;
VAL_ 149 TrOpenerSts 0 "TrOpenerSts1_Ukwn" 1 "TrOpenerSts1_FullClsd" 2 "TrOpenerSts1_MovgUp" 3 "TrOpenerSts1_MovgUpBrkg" 4 "TrOpenerSts1_StopDurgOpen" 5 "TrOpenerSts1_FullOpend" 6 "TrOpenerSts1_MovgDwn" 7 "TrOpenerSts1_MovgDwnBrkg" 8 "TrOpenerSts1_StopDurgCls" 9 "TrOpenerSts1_HalfClsd" 10 "TrOpenerSts1_StopMinPntForCls" ;
VAL_ 149 TrRelsFailtoHMI 0 "Boolean_FALSE" 1 "Boolean_TRUE" ;
VAL_ 1351 VFCVectorPOTVFCid0 0 "VFCOnOff_Off" 1 "VFCOnOff_On" ;
VAL_ 1351 VFCVectorPOTVFCid1 0 "VFCOnOff_Off" 1 "VFCOnOff_On" ;
VAL_ 1351 VFCVectorPOTVFCid10 0 "VFCOnOff_Off" 1 "VFCOnOff_On" ;
VAL_ 1351 VFCVectorPOTVFCid11 0 "VFCOnOff_Off" 1 "VFCOnOff_On" ;
VAL_ 1351 VFCVectorPOTVFCid12 0 "VFCOnOff_Off" 1 "VFCOnOff_On" ;
VAL_ 1351 VFCVectorPOTVFCid13 0 "VFCOnOff_Off" 1 "VFCOnOff_On" ;
VAL_ 1351 VFCVectorPOTVFCid14 0 "VFCOnOff_Off" 1 "VFCOnOff_On" ;
VAL_ 1351 VFCVectorPOTVFCid15 0 "VFCOnOff_Off" 1 "VFCOnOff_On" ;
VAL_ 1351 VFCVectorPOTVFCid16 0 "VFCOnOff_Off" 1 "VFCOnOff_On" ;
VAL_ 1351 VFCVectorPOTVFCid17 0 "VFCOnOff_Off" 1 "VFCOnOff_On" ;
VAL_ 1351 VFCVectorPOTVFCid18 0 "VFCOnOff_Off" 1 "VFCOnOff_On" ;
VAL_ 1351 VFCVectorPOTVFCid19 0 "VFCOnOff_Off" 1 "VFCOnOff_On" ;
VAL_ 1351 VFCVectorPOTVFCid2 0 "VFCOnOff_Off" 1 "VFCOnOff_On" ;
VAL_ 1351 VFCVectorPOTVFCid20 0 "VFCOnOff_Off" 1 "VFCOnOff_On" ;
VAL_ 1351 VFCVectorPOTVFCid21 0 "VFCOnOff_Off" 1 "VFCOnOff_On" ;
VAL_ 1351 VFCVectorPOTVFCid22 0 "VFCOnOff_Off" 1 "VFCOnOff_On" ;
VAL_ 1351 VFCVectorPOTVFCid23 0 "VFCOnOff_Off" 1 "VFCOnOff_On" ;
VAL_ 1351 VFCVectorPOTVFCid24 0 "VFCOnOff_Off" 1 "VFCOnOff_On" ;
VAL_ 1351 VFCVectorPOTVFCid25 0 "VFCOnOff_Off" 1 "VFCOnOff_On" ;
VAL_ 1351 VFCVectorPOTVFCid26 0 "VFCOnOff_Off" 1 "VFCOnOff_On" ;
VAL_ 1351 VFCVectorPOTVFCid27 0 "VFCOnOff_Off" 1 "VFCOnOff_On" ;
VAL_ 1351 VFCVectorPOTVFCid28 0 "VFCOnOff_Off" 1 "VFCOnOff_On" ;
VAL_ 1351 VFCVectorPOTVFCid29 0 "VFCOnOff_Off" 1 "VFCOnOff_On" ;
VAL_ 1351 VFCVectorPOTVFCid3 0 "VFCOnOff_Off" 1 "VFCOnOff_On" ;
VAL_ 1351 VFCVectorPOTVFCid30 0 "VFCOnOff_Off" 1 "VFCOnOff_On" ;
VAL_ 1351 VFCVectorPOTVFCid31 0 "VFCOnOff_Off" 1 "VFCOnOff_On" ;
VAL_ 1351 VFCVectorPOTVFCid32 0 "VFCOnOff_Off" 1 "VFCOnOff_On" ;
VAL_ 1351 VFCVectorPOTVFCid33 0 "VFCOnOff_Off" 1 "VFCOnOff_On" ;
VAL_ 1351 VFCVectorPOTVFCid34 0 "VFCOnOff_Off" 1 "VFCOnOff_On" ;
VAL_ 1351 VFCVectorPOTVFCid35 0 "VFCOnOff_Off" 1 "VFCOnOff_On" ;
VAL_ 1351 VFCVectorPOTVFCid36 0 "VFCOnOff_Off" 1 "VFCOnOff_On" ;
VAL_ 1351 VFCVectorPOTVFCid37 0 "VFCOnOff_Off" 1 "VFCOnOff_On" ;
VAL_ 1351 VFCVectorPOTVFCid38 0 "VFCOnOff_Off" 1 "VFCOnOff_On" ;
VAL_ 1351 VFCVectorPOTVFCid39 0 "VFCOnOff_Off" 1 "VFCOnOff_On" ;
VAL_ 1351 VFCVectorPOTVFCid4 0 "VFCOnOff_Off" 1 "VFCOnOff_On" ;
VAL_ 1351 VFCVectorPOTVFCid40 0 "VFCOnOff_Off" 1 "VFCOnOff_On" ;
VAL_ 1351 VFCVectorPOTVFCid41 0 "VFCOnOff_Off" 1 "VFCOnOff_On" ;
VAL_ 1351 VFCVectorPOTVFCid42 0 "VFCOnOff_Off" 1 "VFCOnOff_On" ;
VAL_ 1351 VFCVectorPOTVFCid43 0 "VFCOnOff_Off" 1 "VFCOnOff_On" ;
VAL_ 1351 VFCVectorPOTVFCid44 0 "VFCOnOff_Off" 1 "VFCOnOff_On" ;
VAL_ 1351 VFCVectorPOTVFCid45 0 "VFCOnOff_Off" 1 "VFCOnOff_On" ;
VAL_ 1351 VFCVectorPOTVFCid46 0 "VFCOnOff_Off" 1 "VFCOnOff_On" ;
VAL_ 1351 VFCVectorPOTVFCid47 0 "VFCOnOff_Off" 1 "VFCOnOff_On" ;
VAL_ 1351 VFCVectorPOTVFCid48 0 "VFCOnOff_Off" 1 "VFCOnOff_On" ;
VAL_ 1351 VFCVectorPOTVFCid49 0 "VFCOnOff_Off" 1 "VFCOnOff_On" ;
VAL_ 1351 VFCVectorPOTVFCid5 0 "VFCOnOff_Off" 1 "VFCOnOff_On" ;
VAL_ 1351 VFCVectorPOTVFCid50 0 "VFCOnOff_Off" 1 "VFCOnOff_On" ;
VAL_ 1351 VFCVectorPOTVFCid51 0 "VFCOnOff_Off" 1 "VFCOnOff_On" ;
VAL_ 1351 VFCVectorPOTVFCid52 0 "VFCOnOff_Off" 1 "VFCOnOff_On" ;
VAL_ 1351 VFCVectorPOTVFCid53 0 "VFCOnOff_Off" 1 "VFCOnOff_On" ;
VAL_ 1351 VFCVectorPOTVFCid54 0 "VFCOnOff_Off" 1 "VFCOnOff_On" ;
VAL_ 1351 VFCVectorPOTVFCid55 0 "VFCOnOff_Off" 1 "VFCOnOff_On" ;
VAL_ 1351 VFCVectorPOTVFCid56 0 "VFCOnOff_Off" 1 "VFCOnOff_On" ;
VAL_ 1351 VFCVectorPOTVFCid57 0 "VFCOnOff_Off" 1 "VFCOnOff_On" ;
VAL_ 1351 VFCVectorPOTVFCid58 0 "VFCOnOff_Off" 1 "VFCOnOff_On" ;
VAL_ 1351 VFCVectorPOTVFCid59 0 "VFCOnOff_Off" 1 "VFCOnOff_On" ;
VAL_ 1351 VFCVectorPOTVFCid6 0 "VFCOnOff_Off" 1 "VFCOnOff_On" ;
VAL_ 1351 VFCVectorPOTVFCid60 0 "VFCOnOff_Off" 1 "VFCOnOff_On" ;
VAL_ 1351 VFCVectorPOTVFCid61 0 "VFCOnOff_Off" 1 "VFCOnOff_On" ;
VAL_ 1351 VFCVectorPOTVFCid7 0 "VFCOnOff_Off" 1 "VFCOnOff_On" ;
VAL_ 1351 VFCVectorPOTVFCid8 0 "VFCOnOff_Off" 1 "VFCOnOff_On" ;
VAL_ 1351 VFCVectorPOTVFCid9 0 "VFCOnOff_Off" 1 "VFCOnOff_On" ;
SIG_GROUP_ 820 ExtrLtgSts 1 : ExtrLtgStsAFS ExtrLtgStsAHBC ExtrLtgStsAHL ExtrLtgStsAllWL ExtrLtgStsApproach ExtrLtgStsChks ExtrLtgStsCntr ExtrLtgStsCornrgLi ExtrLtgStsDBL ExtrLtgStsDRL ExtrLtgStsFlash ExtrLtgStsFrntFog ExtrLtgStsGoodbye ExtrLtgStsHiBeam ExtrLtgStsHomeSafe ExtrLtgStsHWL ExtrLtgStsLoBeam ExtrLtgStsLtgShow ExtrLtgStsPosLiFrnt ExtrLtgStsPosLiRe ExtrLtgStsReFog ExtrLtgStsReverseLi ExtrLtgStsStopLi ExtrLtgStsTurnIndrLe ExtrLtgStsTurnIndrRi ExtrLtgStsWelcome;
SIG_GROUP_ 836 AmbientLiEffectStatus 1 : AmbientLiEffectStatusBreathingEf AmbientLiEffectStatusIdPen AmbientLiEffectStatusTransitionE;
SIG_GROUP_ 836 AmbLiEnduranceMilgOpenReq 1 : AmbLiEnduranceMilgOpenReqIdPen AmbLiEnduranceMilgOpenReqOnOff1;
SIG_GROUP_ 836 Zone1Settings 1 : Zone1SettingsBlue Zone1SettingsGreen Zone1SettingsIdPen Zone1SettingsIntensity Zone1SettingsRed Zone1SettingsZoneStatus;
SIG_GROUP_ 840 AmbLiPhoneOpenReq 1 : AmbLiPhoneOpenReqIdPen AmbLiPhoneOpenReqOnOff1;
SIG_GROUP_ 840 GoodbyeLiOpenReq 1 : GoodbyeLiOpenReqIdPen GoodbyeLiOpenReqOnOff1;
SIG_GROUP_ 840 WelcomeLiOpenReq 1 : WelcomeLiOpenReqIdPen WelcomeLiOpenReqOnOff1;
SIG_GROUP_ 840 Zone2Settings 1 : Zone2SettingsBlue Zone2SettingsGreen Zone2SettingsIdPen Zone2SettingsIntensity Zone2SettingsRed Zone2SettingsZoneStatus;
SIG_GROUP_ 844 AmbLiAll 1 : AmbLiAllIdPen AmbLiAllOnOff1;
SIG_GROUP_ 844 Zone3Settings 1 : Zone3SettingsBlue Zone3SettingsGreen Zone3SettingsIdPen Zone3SettingsIntensity Zone3SettingsRed Zone3SettingsZoneStatus;
SIG_GROUP_ 34 MusicInfoForMusicShow1 1 : MusicInfoForMusicShow1DownSampli MusicInfoForMusicShow1MaxFFT100m MusicInfoForMusicShow1MaxFF_0000 MusicInfoForMusicShow1Segment1FF MusicInfoForMusicShow1Segment2FF MusicInfoForMusicShow1Segment3FF MusicInfoForMusicShow1Segment4FF MusicInfoForMusicShow1Segment5FF MusicInfoForMusicShow1Segment6FF MusicInfoForMusicShow1Segment7FF MusicInfoForMusicShow1Segment8FF MusicInfoForMusicShow1StateFlagA MusicInfoForMusicShow1StateFlagN MusicInfoForMusicShow1TimeFlagAu MusicInfoForMusicShow1TimeFlagMe;
SIG_GROUP_ 48 DoorDrvrHndlHMISts 1 : DoorDrvrHndlHMIStsDeployedOverTm DoorDrvrHndlHMIStsReserved1 DoorDrvrHndlHMIStsRetractOverTmd DoorDrvrHndlHMIStsUnsScsHallSnsr;
SIG_GROUP_ 48 DoorDrvrRelsFail 1 : DoorDrvrRelsFailCinchOverTimed DoorDrvrRelsFailFailure1 DoorDrvrRelsFailMechRels;
SIG_GROUP_ 48 MemBtnPsd 1 : MemBtnPsdMemBtn1 MemBtnPsdMemBtn2 MemBtnPsdMemBtn3 MemBtnPsdMemButM;
SIG_GROUP_ 480 AmbTRawAtDrvrSide 1 : AmbTRawAtDrvrSideAmbTVal AmbTRawAtDrvrSideQly;
SIG_GROUP_ 291 DoorDrvrCinhIntFailInf 1 : DoorDrvrCinhIntFailInfCinchFlt1 DoorDrvrCinhIntFailInfCinchRestF;
SIG_GROUP_ 291 MirrPosnAdjFromCldPass 1 : MirrPosnAdjFromCldPassMirrPosnAd MirrPosnAdjFromCldPassMirrP_0000;
SIG_GROUP_ 291 MirrPosnToCldAtDrvr 1 : MirrPosnToCldAtDrvrMirrPosnAdjCl MirrPosnToCldAtDrvrMirrPosn_0000;
SIG_GROUP_ 5 MirrCmdAtPass 1 : MirrCmdAtPassMirrDwnCmd MirrCmdAtPassMirrFoldCmd MirrCmdAtPassMirrPosAdjCmd;
SIG_GROUP_ 192 WinSwtReq 1 : WinSwtReqChks WinSwtReqCntr WinSwtReqFrntLe WinSwtReqFrntRi WinSwtReqReLe WinSwtReqReRi;
SIG_GROUP_ 1021 DDSPartNo10Cmpl 1 : DDSPartNo10CmplEndSgn1 DDSPartNo10CmplEndSgn2 DDSPartNo10CmplEndSgn3 DDSPartNo10CmplNr1 DDSPartNo10CmplNr2 DDSPartNo10CmplNr3 DDSPartNo10CmplNr4 DDSPartNo10CmplNr5;
SIG_GROUP_ 1022 DDSPartNoCmpl 1 : DDSPartNoCmplEndSgn1 DDSPartNoCmplEndSgn2 DDSPartNoCmplEndSgn3 DDSPartNoCmplNr1 DDSPartNoCmplNr2 DDSPartNoCmplNr3 DDSPartNoCmplNr4;
SIG_GROUP_ 1023 DDSSerNo 1 : DDSSerNoNr1 DDSSerNoNr2 DDSSerNoNr3 DDSSerNoNr4;
SIG_GROUP_ 1347 VFCVectorDDM 1 : VFCVectorDDMBlockID VFCVectorDDMVFCid0 VFCVectorDDMVFCid1 VFCVectorDDMVFCid10 VFCVectorDDMVFCid11 VFCVectorDDMVFCid12 VFCVectorDDMVFCid13 VFCVectorDDMVFCid14 VFCVectorDDMVFCid15 VFCVectorDDMVFCid16 VFCVectorDDMVFCid17 VFCVectorDDMVFCid18 VFCVectorDDMVFCid19 VFCVectorDDMVFCid2 VFCVectorDDMVFCid20 VFCVectorDDMVFCid21 VFCVectorDDMVFCid22 VFCVectorDDMVFCid23 VFCVectorDDMVFCid24 VFCVectorDDMVFCid25 VFCVectorDDMVFCid26 VFCVectorDDMVFCid27 VFCVectorDDMVFCid28 VFCVectorDDMVFCid29 VFCVectorDDMVFCid3 VFCVectorDDMVFCid30 VFCVectorDDMVFCid31 VFCVectorDDMVFCid32 VFCVectorDDMVFCid33 VFCVectorDDMVFCid34 VFCVectorDDMVFCid35 VFCVectorDDMVFCid36 VFCVectorDDMVFCid37 VFCVectorDDMVFCid38 VFCVectorDDMVFCid39 VFCVectorDDMVFCid4 VFCVectorDDMVFCid40 VFCVectorDDMVFCid41 VFCVectorDDMVFCid42 VFCVectorDDMVFCid43 VFCVectorDDMVFCid44 VFCVectorDDMVFCid45 VFCVectorDDMVFCid46 VFCVectorDDMVFCid47 VFCVectorDDMVFCid48 VFCVectorDDMVFCid49 VFCVectorDDMVFCid5 VFCVectorDDMVFCid50 VFCVectorDDMVFCid51 VFCVectorDDMVFCid52 VFCVectorDDMVFCid53 VFCVectorDDMVFCid54 VFCVectorDDMVFCid55 VFCVectorDDMVFCid56 VFCVectorDDMVFCid57 VFCVectorDDMVFCid58 VFCVectorDDMVFCid59 VFCVectorDDMVFCid6 VFCVectorDDMVFCid60 VFCVectorDDMVFCid61 VFCVectorDDMVFCid7 VFCVectorDDMVFCid8 VFCVectorDDMVFCid9;
SIG_GROUP_ 1425 SMBdevelpsignalgroupreq 1 : SMBdevelpsignalgroupreqFunctiond SMBdevelpsignalgroupreqFunc_0000 SMBdevelpsignalgroupreqFunc_0001 SMBdevelpsignalgroupreqFunc_0002 SMBdevelpsignalgroupreqFunc_0003 SMBdevelpsignalgroupreqFunc_0004 SMBdevelpsignalgroupreqFunc_0005 SMBdevelpsignalgroupreqFunc_0006;
SIG_GROUP_ 1426 SMDdevelpsignalgroupreq 1 : SMDdevelpsignalgroupreqFunctiond SMDdevelpsignalgroupreqFunc_0000 SMDdevelpsignalgroupreqFunc_0001 SMDdevelpsignalgroupreqFunc_0002 SMDdevelpsignalgroupreqFunc_0003 SMDdevelpsignalgroupreqFunc_0004 SMDdevelpsignalgroupreqFunc_0005 SMDdevelpsignalgroupreqFunc_0006;
SIG_GROUP_ 1427 SMPdevelpsignalgroupreq 1 : SMPdevelpsignalgroupreqFunctiond SMPdevelpsignalgroupreqFunc_0000 SMPdevelpsignalgroupreqFunc_0001 SMPdevelpsignalgroupreqFunc_0002 SMPdevelpsignalgroupreqFunc_0003 SMPdevelpsignalgroupreqFunc_0004 SMPdevelpsignalgroupreqFunc_0005 SMPdevelpsignalgroupreqFunc_0006;
SIG_GROUP_ 297 AmbLiSettingInfo 1 : AmbLiSettingInfoBlue AmbLiSettingInfoGreen AmbLiSettingInfoIntensity AmbLiSettingInfoRed AmbLiSettingInfoSynchDelay AmbLiSettingInfoTransitionTime;
SIG_GROUP_ 16 DoorPassRelsFail 1 : DoorPassRelsFailCinchOverTimed DoorPassRelsFailFailure1 DoorPassRelsFailMechRels;
SIG_GROUP_ 16 PassMemBtnPsd 1 : PassMemBtnPsdMemBtn1 PassMemBtnPsdMemBtn2 PassMemBtnPsdMemBtn3 PassMemBtnPsdMemButM;
SIG_GROUP_ 293 AmbTRawAtPassSide 1 : AmbTRawAtPassSideAmbTVal AmbTRawAtPassSideQly;
SIG_GROUP_ 293 DoorPassCinhIntFailInf 1 : DoorPassCinhIntFailInfCinchFlt1 DoorPassCinhIntFailInfCinchRestF;
SIG_GROUP_ 293 DoorPassHndlHMISts 1 : DoorPassHndlHMIStsDeployedOverTm DoorPassHndlHMIStsReserved1 DoorPassHndlHMIStsRetractOverTmd DoorPassHndlHMIStsUnsScsHallSnsr;
SIG_GROUP_ 293 MirrPosnToCldAtPass 1 : MirrPosnToCldAtPassMirrPosnAdjCl MirrPosnToCldAtPassMirrPosn_0000;
SIG_GROUP_ 1348 VFCVectorPDM 1 : VFCVectorPDMBlockID VFCVectorPDMVFCid0 VFCVectorPDMVFCid1 VFCVectorPDMVFCid10 VFCVectorPDMVFCid11 VFCVectorPDMVFCid12 VFCVectorPDMVFCid13 VFCVectorPDMVFCid14 VFCVectorPDMVFCid15 VFCVectorPDMVFCid16 VFCVectorPDMVFCid17 VFCVectorPDMVFCid18 VFCVectorPDMVFCid19 VFCVectorPDMVFCid2 VFCVectorPDMVFCid20 VFCVectorPDMVFCid21 VFCVectorPDMVFCid22 VFCVectorPDMVFCid23 VFCVectorPDMVFCid24 VFCVectorPDMVFCid25 VFCVectorPDMVFCid26 VFCVectorPDMVFCid27 VFCVectorPDMVFCid28 VFCVectorPDMVFCid29 VFCVectorPDMVFCid3 VFCVectorPDMVFCid30 VFCVectorPDMVFCid31 VFCVectorPDMVFCid32 VFCVectorPDMVFCid33 VFCVectorPDMVFCid34 VFCVectorPDMVFCid35 VFCVectorPDMVFCid36 VFCVectorPDMVFCid37 VFCVectorPDMVFCid38 VFCVectorPDMVFCid39 VFCVectorPDMVFCid4 VFCVectorPDMVFCid40 VFCVectorPDMVFCid41 VFCVectorPDMVFCid42 VFCVectorPDMVFCid43 VFCVectorPDMVFCid44 VFCVectorPDMVFCid45 VFCVectorPDMVFCid46 VFCVectorPDMVFCid47 VFCVectorPDMVFCid48 VFCVectorPDMVFCid49 VFCVectorPDMVFCid5 VFCVectorPDMVFCid50 VFCVectorPDMVFCid51 VFCVectorPDMVFCid52 VFCVectorPDMVFCid53 VFCVectorPDMVFCid54 VFCVectorPDMVFCid55 VFCVectorPDMVFCid56 VFCVectorPDMVFCid57 VFCVectorPDMVFCid58 VFCVectorPDMVFCid59 VFCVectorPDMVFCid6 VFCVectorPDMVFCid60 VFCVectorPDMVFCid61 VFCVectorPDMVFCid7 VFCVectorPDMVFCid8 VFCVectorPDMVFCid9;
SIG_GROUP_ 149 TopPosHmiFeedBack 1 : TopPosHmiFeedBackPerc13 TopPosHmiFeedBackUknFl;
SIG_GROUP_ 1351 VFCVectorPOT 1 : VFCVectorPOTBlockID VFCVectorPOTVFCid0 VFCVectorPOTVFCid1 VFCVectorPOTVFCid10 VFCVectorPOTVFCid11 VFCVectorPOTVFCid12 VFCVectorPOTVFCid13 VFCVectorPOTVFCid14 VFCVectorPOTVFCid15 VFCVectorPOTVFCid16 VFCVectorPOTVFCid17 VFCVectorPOTVFCid18 VFCVectorPOTVFCid19 VFCVectorPOTVFCid2 VFCVectorPOTVFCid20 VFCVectorPOTVFCid21 VFCVectorPOTVFCid22 VFCVectorPOTVFCid23 VFCVectorPOTVFCid24 VFCVectorPOTVFCid25 VFCVectorPOTVFCid26 VFCVectorPOTVFCid27 VFCVectorPOTVFCid28 VFCVectorPOTVFCid29 VFCVectorPOTVFCid3 VFCVectorPOTVFCid30 VFCVectorPOTVFCid31 VFCVectorPOTVFCid32 VFCVectorPOTVFCid33 VFCVectorPOTVFCid34 VFCVectorPOTVFCid35 VFCVectorPOTVFCid36 VFCVectorPOTVFCid37 VFCVectorPOTVFCid38 VFCVectorPOTVFCid39 VFCVectorPOTVFCid4 VFCVectorPOTVFCid40 VFCVectorPOTVFCid41 VFCVectorPOTVFCid42 VFCVectorPOTVFCid43 VFCVectorPOTVFCid44 VFCVectorPOTVFCid45 VFCVectorPOTVFCid46 VFCVectorPOTVFCid47 VFCVectorPOTVFCid48 VFCVectorPOTVFCid49 VFCVectorPOTVFCid5 VFCVectorPOTVFCid50 VFCVectorPOTVFCid51 VFCVectorPOTVFCid52 VFCVectorPOTVFCid53 VFCVectorPOTVFCid54 VFCVectorPOTVFCid55 VFCVectorPOTVFCid56 VFCVectorPOTVFCid57 VFCVectorPOTVFCid58 VFCVectorPOTVFCid59 VFCVectorPOTVFCid6 VFCVectorPOTVFCid60 VFCVectorPOTVFCid61 VFCVectorPOTVFCid7 VFCVectorPOTVFCid8 VFCVectorPOTVFCid9;
